VERSION ""

NS_ :

BS_:

BU_: CH DIPF DIPR ETH FC HVI HVS PARTY SDCV VEH VIRT

BO_ 1448 EPBR_alertLog: 8 VEH
 SG_ EPBR_a174_nonterminalReason m174 : 56|5@1+ (1,0) [0|21] ""  gtw
 SG_ EPBR_a190_nonterminalReason m190 : 56|5@1+ (1,0) [0|21] ""  gtw
 SG_ EPBR_a175_nonterminalReason m175 : 56|5@1+ (1,0) [0|21] ""  gtw
 SG_ EPBR_a042_UsageNVMMTask m42 : 56|8@1+ (1,0) [0|255] ""  gtw
 SG_ EPBR_a247_nonterminalReason m247 : 56|5@1+ (1,0) [0|21] ""  gtw
 SG_ EPBR_a191_nonterminalReason m191 : 56|5@1+ (1,0) [0|21] ""  gtw
 SG_ EPBR_a022_TaskInitError4 m22 : 56|8@1+ (1,0) [0|255] ""  gtw
 SG_ EPBR_a179_nonterminalReason m179 : 56|5@1+ (1,0) [0|21] ""  gtw
 SG_ EPBR_a176_nonterminalReason m176 : 56|5@1+ (1,0) [0|21] ""  gtw
 SG_ EPBR_a248_nonterminalReason m248 : 56|5@1+ (1,0) [0|21] ""  gtw
 SG_ EPBR_a177_nonterminalReason m177 : 56|5@1+ (1,0) [0|21] ""  gtw
 SG_ EPBR_a041_CPULoadNVMMTask m41 : 56|8@1+ (1,0) [0|255] ""  gtw
 SG_ EPBR_a138_monitorState m138 : 51|3@1+ (1,0) [0|5] ""  gtw
 SG_ EPBR_a177_esmOpTrigger m177 : 48|5@1+ (1,0) [0|30] ""  gtw
 SG_ EPBR_a248_esmOpTrigger m248 : 48|5@1+ (1,0) [0|30] ""  gtw
 SG_ EPBR_a041_CPULoad1000msTask m41 : 48|8@1+ (1,0) [0|255] ""  gtw
 SG_ EPBR_a022_TaskInitError3 m22 : 48|8@1+ (1,0) [0|255] ""  gtw
 SG_ EPBR_a190_esmOpTrigger m190 : 48|5@1+ (1,0) [0|30] ""  gtw
 SG_ EPBR_a042_UsageUDSTask m42 : 48|8@1+ (1,0) [0|255] ""  gtw
 SG_ EPBR_a174_esmOpTrigger m174 : 48|5@1+ (1,0) [0|30] ""  gtw
 SG_ EPBR_a003_Data m3 : 48|16@1+ (1,0) [0|65535] ""  gtw
 SG_ EPBR_a138_localState m138 : 48|3@1+ (1,0) [0|5] ""  gtw
 SG_ EPBR_a247_esmOpTrigger m247 : 48|5@1+ (1,0) [0|30] ""  gtw
 SG_ EPBR_a191_esmOpTrigger m191 : 48|5@1+ (1,0) [0|30] ""  gtw
 SG_ EPBR_a175_esmOpTrigger m175 : 48|5@1+ (1,0) [0|30] ""  gtw
 SG_ EPBR_a216_byte3 m216 : 48|8@1+ (1,0) [0|255] ""  gtw
 SG_ EPBR_a176_esmOpTrigger m176 : 48|5@1+ (1,0) [0|30] ""  gtw
 SG_ EPBR_a000_alertDataW2 m0 : 48|16@1+ (1,0) [0|65535] ""  X
 SG_ EPBR_a179_esmOpTrigger m179 : 48|5@1+ (1,0) [0|30] ""  gtw
 SG_ EPBR_a183_invalidateReason m183 : 45|2@1+ (1,0) [0|3] ""  gtw
 SG_ EPBR_a063_faulted m63 : 43|1@1+ (1,0) [0|1] ""  gtw
 SG_ EPBR_a063_stuckActive m63 : 42|1@1+ (1,0) [0|1] ""  gtw
 SG_ EPBR_a063_indeterminate m63 : 41|1@1+ (1,0) [0|1] ""  gtw
 SG_ EPBR_a171_12vFilt m171 : 40|12@1+ (0.005443676098,0) [0|22.29185] "V"  gtw
 SG_ EPBR_a135_12vFilt m135 : 40|12@1+ (0.005443676098,0) [0|22.29185] "V"  gtw
 SG_ EPBR_a022_TaskInitError2 m22 : 40|8@1+ (1,0) [0|255] ""  gtw
 SG_ EPBR_a247_csmFaultReason m247 : 40|5@1+ (1,0) [0|21] ""  gtw
 SG_ EPBR_a183_nextState m183 : 40|5@1+ (1,0) [0|19] ""  gtw
 SG_ EPBR_a191_csmFaultReason m191 : 40|5@1+ (1,0) [0|21] ""  gtw
 SG_ EPBR_a186_nextState m186 : 40|5@1+ (1,0) [0|19] ""  gtw
 SG_ EPBR_a126_12vFilt m126 : 40|12@1+ (0.005443676098,0) [0|22.29185] "V"  gtw
 SG_ EPBR_a041_CPULoad100msTask m41 : 40|8@1+ (1,0) [0|255] ""  gtw
 SG_ EPBR_a170_12vFilt m170 : 40|12@1+ (0.005443676098,0) [0|22.29185] "V"  gtw
 SG_ EPBR_a246_esmOpTrigger m246 : 40|5@1+ (1,0) [0|30] ""  gtw
 SG_ EPBR_a134_12vFilt m134 : 40|12@1+ (0.005443676098,0) [0|22.29185] "V"  gtw
 SG_ EPBR_a063_disconnected m63 : 40|1@1+ (1,0) [0|1] ""  gtw
 SG_ EPBR_a180_nextState m180 : 40|5@1+ (1,0) [0|19] ""  gtw
 SG_ EPBR_a174_csmFaultReason m174 : 40|5@1+ (1,0) [0|21] ""  gtw
 SG_ EPBR_a217_byte7 m217 : 40|8@1+ (1,0) [0|255] ""  gtw
 SG_ EPBR_a187_nextState m187 : 40|5@1+ (1,0) [0|19] ""  gtw
 SG_ EPBR_a127_12vFilt m127 : 40|12@1+ (0.005443676098,0) [0|22.29185] "V"  gtw
 SG_ EPBR_a190_csmFaultReason m190 : 40|5@1+ (1,0) [0|21] ""  gtw
 SG_ EPBR_a249_esmOpTrigger m249 : 40|5@1+ (1,0) [0|30] ""  gtw
 SG_ EPBR_a216_byte2 m216 : 40|8@1+ (1,0) [0|255] ""  gtw
 SG_ EPBR_a059_current m59 : 40|12@1+ (0.05,0) [0|204.75] "A"  gtw
 SG_ EPBR_a184_nextState m184 : 40|5@1+ (1,0) [0|19] ""  gtw
 SG_ EPBR_a043_CallTrace1 m43 : 40|24@1+ (1,0) [0|16777215] ""  gtw
 SG_ EPBR_a248_csmFaultReason m248 : 40|5@1+ (1,0) [0|21] ""  gtw
 SG_ EPBR_a044_CallTrace1 m44 : 40|24@1+ (1,0) [0|16777215] ""  gtw
 SG_ EPBR_a177_csmFaultReason m177 : 40|5@1+ (1,0) [0|21] ""  gtw
 SG_ EPBR_a137_12vFilt m137 : 40|12@1+ (0.005443676098,0) [0|22.29185] "V"  gtw
 SG_ EPBR_a125_12vFilt m125 : 40|12@1+ (0.005443676098,0) [0|22.29185] "V"  gtw
 SG_ EPBR_a179_csmFaultReason m179 : 40|5@1+ (1,0) [0|21] ""  gtw
 SG_ EPBR_a042_Usage1000msTask m42 : 40|8@1+ (1,0) [0|255] ""  gtw
 SG_ EPBR_a188_nextState m188 : 40|5@1+ (1,0) [0|19] ""  gtw
 SG_ EPBR_a128_12vFilt m128 : 40|12@1+ (0.005443676098,0) [0|22.29185] "V"  gtw
 SG_ EPBR_a136_12vFilt m136 : 40|12@1+ (0.005443676098,0) [0|22.29185] "V"  gtw
 SG_ EPBR_a176_csmFaultReason m176 : 40|5@1+ (1,0) [0|21] ""  gtw
 SG_ EPBR_a045_CallTrace1 m45 : 40|24@1+ (1,0) [0|16777215] ""  gtw
 SG_ EPBR_a189_nextState m189 : 40|5@1+ (1,0) [0|19] ""  gtw
 SG_ EPBR_a046_CallTrace1 m46 : 40|24@1+ (1,0) [0|16777215] ""  gtw
 SG_ EPBR_a175_csmFaultReason m175 : 40|5@1+ (1,0) [0|21] ""  gtw
 SG_ EPBR_a176_monitorFaultStatus m176 : 37|2@1+ (1,0) [0|3] ""  gtw
 SG_ EPBR_a249_faultStatus m249 : 37|2@1+ (1,0) [0|3] ""  gtw
 SG_ EPBR_a177_monitorFaultStatus m177 : 37|2@1+ (1,0) [0|3] ""  gtw
 SG_ EPBR_a174_monitorFaultStatus m174 : 37|2@1+ (1,0) [0|3] ""  gtw
 SG_ EPBR_a179_monitorFaultStatus m179 : 37|2@1+ (1,0) [0|3] ""  gtw
 SG_ EPBR_a190_monitorFaultStatus m190 : 37|2@1+ (1,0) [0|3] ""  gtw
 SG_ EPBR_a248_monitorFaultStatus m248 : 37|2@1+ (1,0) [0|3] ""  gtw
 SG_ EPBR_a175_monitorFaultStatus m175 : 37|2@1+ (1,0) [0|3] ""  gtw
 SG_ EPBR_a246_faultStatus m246 : 37|2@1+ (1,0) [0|3] ""  gtw
 SG_ EPBR_a191_monitorFaultStatus m191 : 37|2@1+ (1,0) [0|3] ""  gtw
 SG_ EPBR_a247_monitorFaultStatus m247 : 37|2@1+ (1,0) [0|3] ""  gtw
 SG_ EPBR_a188_previousState m188 : 32|5@1+ (1,0) [0|19] ""  gtw
 SG_ EPBR_a177_monitorUnitStatus m177 : 32|5@1+ (1,0) [0|21] ""  gtw
 SG_ EPBR_a041_CPULoad10msTask m41 : 32|8@1+ (1,0) [0|255] ""  gtw
 SG_ EPBR_a183_previousState m183 : 32|5@1+ (1,0) [0|19] ""  gtw
 SG_ EPBR_a003_LineNumber m3 : 32|16@1+ (1,0) [0|65535] ""  gtw
 SG_ EPBR_a176_monitorUnitStatus m176 : 32|5@1+ (1,0) [0|21] ""  gtw
 SG_ EPBR_a216_byte1 m216 : 32|8@1+ (1,0) [0|255] ""  gtw
 SG_ EPBR_a189_previousState m189 : 32|5@1+ (1,0) [0|19] ""  gtw
 SG_ EPBR_a184_previousState m184 : 32|5@1+ (1,0) [0|19] ""  gtw
 SG_ EPBR_a217_byte6 m217 : 32|8@1+ (1,0) [0|255] ""  gtw
 SG_ EPBR_a248_monitorUnitStatus m248 : 32|5@1+ (1,0) [0|21] ""  gtw
 SG_ EPBR_a000_alertDataW1 m0 : 32|16@1+ (1,0) [0|65535] ""  X
 SG_ EPBR_a175_monitorUnitStatus m175 : 32|5@1+ (1,0) [0|21] ""  gtw
 SG_ EPBR_a246_esmStateRequest m246 : 32|5@1+ (1,0) [0|19] ""  gtw
 SG_ EPBR_a249_esmStateRequest m249 : 32|5@1+ (1,0) [0|19] ""  gtw
 SG_ EPBR_a247_monitorUnitStatus m247 : 32|5@1+ (1,0) [0|21] ""  gtw
 SG_ EPBR_a191_monitorUnitStatus m191 : 32|5@1+ (1,0) [0|21] ""  gtw
 SG_ EPBR_a180_previousState m180 : 32|5@1+ (1,0) [0|19] ""  gtw
 SG_ EPBR_a173_csmState m173 : 32|4@1+ (1,0) [0|14] ""  gtw
 SG_ EPBR_a182_temperature m182 : 32|8@1- (0.5,-40) [-40|80] "deg C"  gtw
 SG_ EPBR_a174_monitorUnitStatus m174 : 32|5@1+ (1,0) [0|21] ""  gtw
 SG_ EPBR_a042_Usage100msTask m42 : 32|8@1+ (1,0) [0|255] ""  gtw
 SG_ EPBR_a179_monitorUnitStatus m179 : 32|5@1+ (1,0) [0|21] ""  gtw
 SG_ EPBR_a186_previousState m186 : 32|5@1+ (1,0) [0|19] ""  gtw
 SG_ EPBR_a063_ADCVoltage m63 : 32|8@1+ (0.025,0) [0|6.375] "V"  gtw
 SG_ EPBR_a022_TaskInitError1 m22 : 32|8@1+ (1,0) [0|255] ""  gtw
 SG_ EPBR_a190_monitorUnitStatus m190 : 32|5@1+ (1,0) [0|21] ""  gtw
 SG_ EPBR_a187_previousState m187 : 32|5@1+ (1,0) [0|19] ""  gtw
 SG_ EPBR_a177_faultStatus m177 : 29|2@1+ (1,0) [0|3] ""  gtw
 SG_ EPBR_a176_faultStatus m176 : 29|2@1+ (1,0) [0|3] ""  gtw
 SG_ EPBR_a248_faultStatus m248 : 29|2@1+ (1,0) [0|3] ""  gtw
 SG_ EPBR_a175_faultStatus m175 : 29|2@1+ (1,0) [0|3] ""  gtw
 SG_ EPBR_a191_faultStatus m191 : 29|2@1+ (1,0) [0|3] ""  gtw
 SG_ EPBR_a247_faultStatus m247 : 29|2@1+ (1,0) [0|3] ""  gtw
 SG_ EPBR_a174_faultStatus m174 : 29|2@1+ (1,0) [0|3] ""  gtw
 SG_ EPBR_a179_faultStatus m179 : 29|2@1+ (1,0) [0|3] ""  gtw
 SG_ EPBR_a190_faultStatus m190 : 29|2@1+ (1,0) [0|3] ""  gtw
 SG_ EPBR_a126_nvFilt m126 : 28|12@1+ (0.005443676098,0) [0|22.29185] "V"  gtw
 SG_ EPBR_a128_nvFilt m128 : 28|12@1+ (0.005443676098,0) [0|22.29185] "V"  gtw
 SG_ EPBR_a170_nvFilt m170 : 28|12@1+ (0.005443676098,0) [0|22.29185] "V"  gtw
 SG_ EPBR_a059_resistanceEstimate m59 : 28|12@1+ (0.00244,0) [0|9.9918] "Ohms"  gtw
 SG_ EPBR_a134_nvFilt m134 : 28|12@1+ (0.005443676098,0) [0|22.29185] "V"  gtw
 SG_ EPBR_a127_nvFilt m127 : 28|12@1+ (0.005443676098,0) [0|22.29185] "V"  gtw
 SG_ EPBR_a137_nvFilt m137 : 28|12@1+ (0.005443676098,0) [0|22.29185] "V"  gtw
 SG_ EPBR_a125_nvFilt m125 : 28|12@1+ (0.005443676098,0) [0|22.29185] "V"  gtw
 SG_ EPBR_a136_nvFilt m136 : 28|12@1+ (0.005443676098,0) [0|22.29185] "V"  gtw
 SG_ EPBR_a135_nvFilt m135 : 28|12@1+ (0.005443676098,0) [0|22.29185] "V"  gtw
 SG_ EPBR_a171_nvFilt m171 : 28|12@1+ (0.005443676098,0) [0|22.29185] "V"  gtw
 SG_ EPBR_a116_VEH_logging1Hz m116 : 27|1@1+ (1,0) [0|1] ""  gtw
 SG_ EPBR_a021_Task1000msMissed m21 : 27|1@1+ (1,0) [0|1] ""  gtw
 SG_ EPBR_a021_Task1000msStarved m21 : 26|1@1+ (1,0) [0|1] ""  gtw
 SG_ EPBR_a116_VEH_switchStatus m116 : 26|1@1+ (1,0) [0|1] ""  gtw
 SG_ EPBR_a241_highCurrent m241 : 26|2@1+ (1,0) [0|3] ""  gtw
 SG_ EPBR_a243_brakeDiscWipingActive m243 : 26|1@1+ (1,0) [0|1] ""  gtw
 SG_ EPBR_a242_highCurrent m242 : 26|2@1+ (1,0) [0|3] ""  gtw
 SG_ EPBR_a021_Task1000msLate m21 : 25|1@1+ (1,0) [0|1] ""  gtw
 SG_ EPBR_a243_vehiclePowerState m243 : 25|1@1+ (1,0) [0|1] ""  gtw
 SG_ EPBR_a116_VEH_restraintStatus m116 : 25|1@1+ (1,0) [0|1] ""  gtw
 SG_ EPBR_a117_VEH_intrusionSensorSta m117 : 25|1@1+ (1,0) [0|1] ""  gtw
 SG_ EPBR_a180_esmOpTrigger m180 : 24|5@1+ (1,0) [0|30] ""  gtw
 SG_ EPBR_a176_esmStateRequest m176 : 24|5@1+ (1,0) [0|19] ""  gtw
 SG_ EPBR_a187_esmOpTrigger m187 : 24|5@1+ (1,0) [0|30] ""  gtw
 SG_ EPBR_a179_esmStateRequest m179 : 24|5@1+ (1,0) [0|19] ""  gtw
 SG_ EPBR_a216_byte0 m216 : 24|8@1+ (1,0) [0|255] ""  gtw
 SG_ EPBR_a249_nextState m249 : 24|5@1+ (1,0) [0|19] ""  gtw
 SG_ EPBR_a041_CPULoad1msTask m41 : 24|8@1+ (1,0) [0|255] ""  gtw
 SG_ EPBR_a300_subUsageId m300 : 24|5@1+ (1,0) [0|19] ""  gtw
 SG_ EPBR_a242_vehiclePowerState m242 : 24|2@1+ (1,0) [0|3] ""  gtw
 SG_ EPBR_a177_esmStateRequest m177 : 24|5@1+ (1,0) [0|19] ""  gtw
 SG_ EPBR_a189_esmOpTrigger m189 : 24|5@1+ (1,0) [0|30] ""  gtw
 SG_ EPBR_a183_esmOpTrigger m183 : 24|5@1+ (1,0) [0|30] ""  gtw
 SG_ EPBR_a186_esmOpTrigger m186 : 24|5@1+ (1,0) [0|30] ""  gtw
 SG_ EPBR_a248_esmStateRequest m248 : 24|5@1+ (1,0) [0|19] ""  gtw
 SG_ EPBR_a141_toState m141 : 24|5@1+ (1,0) [0|19] ""  gtw
 SG_ EPBR_a117_VEH_switchStatus m117 : 24|1@1+ (1,0) [0|1] ""  gtw
 SG_ EPBR_a118_VEH_systemStatus m118 : 24|1@1+ (1,0) [0|1] ""  gtw
 SG_ EPBR_a190_esmStateRequest m190 : 24|5@1+ (1,0) [0|19] ""  gtw
 SG_ EPBR_a116_VEH_seatHeatStatus m116 : 24|1@1+ (1,0) [0|1] ""  gtw
 SG_ EPBR_a188_esmOpTrigger m188 : 24|5@1+ (1,0) [0|30] ""  gtw
 SG_ EPBR_a241_vehiclePowerState m241 : 24|2@1+ (1,0) [0|3] ""  gtw
 SG_ EPBR_a113_VEH_powertrainControl m113 : 24|1@1+ (1,0) [0|1] ""  gtw
 SG_ EPBR_a174_esmStateRequest m174 : 24|5@1+ (1,0) [0|19] ""  gtw
 SG_ EPBR_a022_TaskInitError0 m22 : 24|8@1+ (1,0) [0|255] ""  gtw
 SG_ EPBR_a063_switchType m63 : 24|8@1+ (1,0) [0|255] ""  gtw
 SG_ EPBR_a191_esmStateRequest m191 : 24|5@1+ (1,0) [0|19] ""  gtw
 SG_ EPBR_a021_Task100msMissed m21 : 24|1@1+ (1,0) [0|1] ""  gtw
 SG_ EPBR_a247_esmStateRequest m247 : 24|5@1+ (1,0) [0|19] ""  gtw
 SG_ EPBR_a184_esmOpTrigger m184 : 24|5@1+ (1,0) [0|30] ""  gtw
 SG_ EPBR_a042_Usage10msTask m42 : 24|8@1+ (1,0) [0|255] ""  gtw
 SG_ EPBR_a175_esmStateRequest m175 : 24|5@1+ (1,0) [0|19] ""  gtw
 SG_ EPBR_a182_grade m182 : 24|7@1- (1,0) [-64|63] "%"  gtw
 SG_ EPBR_a217_byte5 m217 : 24|8@1+ (1,0) [0|255] ""  gtw
 SG_ EPBR_a243_wiperSpeed m243 : 24|1@1+ (1,0) [0|1] ""  gtw
 SG_ EPBR_a173_esmStateRequest m173 : 24|5@1+ (1,0) [0|19] ""  gtw
 SG_ EPBR_a246_nextState m246 : 24|5@1+ (1,0) [0|19] ""  gtw
 SG_ EPBR_a120_VEH_speed m120 : 24|1@1+ (1,0) [0|1] ""  gtw
 SG_ EPBR_a120_PARTY_speed m120 : 23|1@1+ (1,0) [0|1] ""  gtw
 SG_ EPBR_a117_VEH_doorStatus m117 : 23|1@1+ (1,0) [0|1] ""  gtw
 SG_ EPBR_a113_VEH_chassisControl m113 : 23|1@1+ (1,0) [0|1] ""  gtw
 SG_ EPBR_a021_Task100msStarved m21 : 23|1@1+ (1,0) [0|1] ""  gtw
 SG_ EPBR_a243_thermistorTMin m243 : 23|1@1+ (1,0) [0|1] ""  gtw
 SG_ EPBR_a118_VEH_12VBattStatus m118 : 23|1@1+ (1,0) [0|1] ""  gtw
 SG_ EPBR_a116_VEH_doorStatus m116 : 23|1@1+ (1,0) [0|1] ""  gtw
 SG_ EPBR_a117_VEH_seatStatus m117 : 22|1@1+ (1,0) [0|1] ""  gtw
 SG_ EPBR_a118_VEH_vehicleStatus m118 : 22|1@1+ (1,0) [0|1] ""  gtw
 SG_ EPBR_a021_Task100msLate m21 : 22|1@1+ (1,0) [0|1] ""  gtw
 SG_ EPBR_a113_VEH_ventCntlReq m113 : 22|1@1+ (1,0) [0|1] ""  gtw
 SG_ EPBR_a116_VEH_thsStatus m116 : 22|1@1+ (1,0) [0|1] ""  gtw
 SG_ EPBR_a243_tempAmbient m243 : 22|1@1+ (1,0) [0|1] ""  gtw
 SG_ EPBR_a120_VEH_status m120 : 22|1@1+ (1,0) [0|1] ""  gtw
 SG_ EPBR_a015_NVMMWriteFailed m15 : 21|1@1+ (1,0) [0|1] ""  gtw
 SG_ EPBR_a021_Task10msMissed m21 : 21|1@1+ (1,0) [0|1] ""  gtw
 SG_ EPBR_a113_VEH_solarData m113 : 21|1@1+ (1,0) [0|1] ""  gtw
 SG_ EPBR_a117_VEH_lightStatus m117 : 21|1@1+ (1,0) [0|1] ""  gtw
 SG_ EPBR_a120_PARTY_locStatus m120 : 21|1@1+ (1,0) [0|1] ""  gtw
 SG_ EPBR_a012_ExternalReset m12 : 21|1@1+ (1,0) [0|1] ""  gtw
 SG_ EPBR_a116_VEH_seatStatus m116 : 21|1@1+ (1,0) [0|1] ""  gtw
 SG_ EPBR_a243_vehicleSpeed m243 : 21|1@1+ (1,0) [0|1] ""  gtw
 SG_ EPBR_a118_VEH_LVPowerState m118 : 21|1@1+ (1,0) [0|1] ""  gtw
 SG_ EPBR_a242_hvState m242 : 20|3@1+ (1,0) [0|6] ""  gtw
 SG_ EPBR_a243_DIStorqueActual m243 : 20|1@1+ (1,0) [0|1] ""  gtw
 SG_ EPBR_a021_Task10msStarved m21 : 20|1@1+ (1,0) [0|1] ""  gtw
 SG_ EPBR_a117_VEH_restraintStatus m117 : 20|1@1+ (1,0) [0|1] ""  gtw
 SG_ EPBR_a118_VEH_okToUseHighPwr m118 : 20|1@1+ (1,0) [0|1] ""  gtw
 SG_ EPBR_a116_VEH_lightStatus m116 : 20|1@1+ (1,0) [0|1] ""  gtw
 SG_ EPBR_a015_NVMMMemOverflow m15 : 20|1@1+ (1,0) [0|1] ""  gtw
 SG_ EPBR_a113_VEH_vehicleControl2 m113 : 20|1@1+ (1,0) [0|1] ""  gtw
 SG_ EPBR_a120_VEH_torque m120 : 20|1@1+ (1,0) [0|1] ""  gtw
 SG_ EPBR_a012_DebugReset m12 : 20|1@1+ (1,0) [0|1] ""  gtw
 SG_ EPBR_a107_VEH_bmbMinMax m107 : 20|1@1+ (1,0) [0|1] ""  gtw
 SG_ EPBR_a107_VEH_thermalStatus m107 : 19|1@1+ (1,0) [0|1] ""  gtw
 SG_ EPBR_a015_NVMMRecordUpgraded m15 : 19|1@1+ (1,0) [0|1] ""  gtw
 SG_ EPBR_a021_Task10msLate m21 : 19|1@1+ (1,0) [0|1] ""  gtw
 SG_ EPBR_a178_monitorCaliperState m178 : 19|3@1+ (1,0) [0|5] ""  gtw
 SG_ EPBR_a241_epbSysStatus m241 : 19|4@1+ (1,0) [0|8] ""  gtw
 SG_ EPBR_a120_PARTY_torque m120 : 19|1@1+ (1,0) [0|1] ""  gtw
 SG_ EPBR_a012_CheckstopReset m12 : 19|1@1+ (1,0) [0|1] ""  gtw
 SG_ EPBR_a114_PARTY_party3 m114 : 19|1@1+ (1,0) [0|1] ""  gtw
 SG_ EPBR_a116_VEH_LVPowerState m116 : 19|1@1+ (1,0) [0|1] ""  gtw
 SG_ EPBR_a109_PARTY_collision m109 : 19|1@1+ (1,0) [0|1] ""  gtw
 SG_ EPBR_a242_contCurrentState m242 : 19|1@1+ (1,0) [0|1] ""  gtw
 SG_ EPBR_a117_VEH_LVPowerState m117 : 19|1@1+ (1,0) [0|1] ""  gtw
 SG_ EPBR_a243_DItorqueActual m243 : 19|1@1+ (1,0) [0|1] ""  gtw
 SG_ EPBR_a216_monitor_MIA m216 : 19|1@1+ (1,0) [0|1] ""  gtw
 SG_ EPBR_a104_PARTY_control m104 : 19|1@1+ (1,0) [0|1] ""  gtw
 SG_ EPBR_a113_VEH_vehicleControl m113 : 19|1@1+ (1,0) [0|1] ""  gtw
 SG_ EPBR_a108_PARTY_torque m108 : 19|1@1+ (1,0) [0|1] ""  gtw
 SG_ EPBR_a118_VEH_status m118 : 19|1@1+ (1,0) [0|1] ""  gtw
 SG_ EPBR_a242_contDesiredState m242 : 18|1@1+ (1,0) [0|1] ""  gtw
 SG_ EPBR_a109_PARTY_nearDeploy m109 : 18|1@1+ (1,0) [0|1] ""  gtw
 SG_ EPBR_a116_VEH_hvacRequest m116 : 18|1@1+ (1,0) [0|1] ""  gtw
 SG_ EPBR_a114_VEH_wheelSpeeds m114 : 18|1@1+ (1,0) [0|1] ""  gtw
 SG_ EPBR_a106_VEH_thermalStatus m106 : 18|1@1+ (1,0) [0|1] ""  gtw
 SG_ EPBR_a187_monitorCDPStatus m187 : 18|2@1+ (1,0) [0|2] ""  gtw
 SG_ EPBR_a110_VEH_time m110 : 18|1@1+ (1,0) [0|1] ""  gtw
 SG_ EPBR_a243_drivetrainType m243 : 18|1@1+ (1,0) [0|1] ""  gtw
 SG_ EPBR_a118_VEH_sensors m118 : 18|1@1+ (1,0) [0|1] ""  gtw
 SG_ EPBR_a241_diKeepAlive m241 : 18|1@1+ (1,0) [0|1] ""  gtw
 SG_ EPBR_a188_monitorCDPStatus m188 : 18|2@1+ (1,0) [0|2] ""  gtw
 SG_ EPBR_a117_VEH_hvacBlowerFdb m117 : 18|1@1+ (1,0) [0|1] ""  gtw
 SG_ EPBR_a102_VEH_sensorStatus m102 : 18|1@1+ (1,0) [0|1] ""  gtw
 SG_ EPBR_a183_monitorCDPStatus m183 : 18|2@1+ (1,0) [0|2] ""  gtw
 SG_ EPBR_a108_VEH_torque m108 : 18|1@1+ (1,0) [0|1] ""  gtw
 SG_ EPBR_a103_VEH_status m103 : 18|1@1+ (1,0) [0|1] ""  gtw
 SG_ EPBR_a015_NVMMVersionMismatch m15 : 18|1@1+ (1,0) [0|1] ""  gtw
 SG_ EPBR_a184_monitorCDPStatus m184 : 18|2@1+ (1,0) [0|2] ""  gtw
 SG_ EPBR_a189_monitorCDPStatus m189 : 18|2@1+ (1,0) [0|2] ""  gtw
 SG_ EPBR_a021_Task1msMissed m21 : 18|1@1+ (1,0) [0|1] ""  gtw
 SG_ EPBR_a113_VEH_chargeRequest m113 : 18|1@1+ (1,0) [0|1] ""  gtw
 SG_ EPBR_a119_VEH_rightStalk m119 : 18|1@1+ (1,0) [0|1] ""  gtw
 SG_ EPBR_a012_SoftwareReset m12 : 18|1@1+ (1,0) [0|1] ""  gtw
 SG_ EPBR_a180_monitorCDPStatus m180 : 18|2@1+ (1,0) [0|2] ""  gtw
 SG_ EPBR_a107_VEH_status m107 : 18|1@1+ (1,0) [0|1] ""  gtw
 SG_ EPBR_a104_VEH_thermalStatus m104 : 18|1@1+ (1,0) [0|1] ""  gtw
 SG_ EPBR_a120_PARTY_systemStatus m120 : 18|1@1+ (1,0) [0|1] ""  gtw
 SG_ EPBR_a216_CRC_error m216 : 18|1@1+ (1,0) [0|1] ""  gtw
 SG_ EPBR_a186_monitorCDPStatus m186 : 18|2@1+ (1,0) [0|2] ""  gtw
 SG_ EPBR_a216_spiFault m216 : 17|1@1+ (1,0) [0|1] ""  gtw
 SG_ EPBR_a114_PARTY_wheelSpeeds m114 : 17|1@1+ (1,0) [0|1] ""  gtw
 SG_ EPBR_a113_VEH_hvacRequest m113 : 17|1@1+ (1,0) [0|1] ""  gtw
 SG_ EPBR_a118_VEH_lighting m118 : 17|1@1+ (1,0) [0|1] ""  gtw
 SG_ EPBR_a107_VEH_vehNm m107 : 17|1@1+ (1,0) [0|1] ""  gtw
 SG_ EPBR_a112_VEH_status m112 : 17|1@1+ (1,0) [0|1] ""  gtw
 SG_ EPBR_a242_hvcCurrentState m242 : 17|1@1+ (1,0) [0|1] ""  gtw
 SG_ EPBR_a106_VEH_thermalControl m106 : 17|1@1+ (1,0) [0|1] ""  gtw
 SG_ EPBR_a119_VEH_leftStalk m119 : 17|1@1+ (1,0) [0|1] ""  gtw
 SG_ EPBR_a100_PARTY m100 : 17|1@1+ (1,0) [0|1] ""  gtw
 SG_ EPBR_a201_epbHWBrakeType m201 : 17|2@1+ (1,0) [0|2] ""  gtw
 SG_ EPBR_a241_currentState m241 : 17|1@1+ (1,0) [0|1] ""  gtw
 SG_ EPBR_a115_VEH_authentication m115 : 17|1@1+ (1,0) [0|1] ""  gtw
 SG_ EPBR_a002_PowerOnReset m2 : 17|1@1+ (1,0) [0|1] ""  gtw
 SG_ EPBR_a013_ClearQueueFull m13 : 17|1@1+ (1,0) [0|1] ""  gtw
 SG_ EPBR_a103_VEH_vehNm m103 : 17|1@1+ (1,0) [0|1] ""  gtw
 SG_ EPBR_a117_VEH_vehNm m117 : 17|1@1+ (1,0) [0|1] ""  gtw
 SG_ EPBR_a012_FlashError m12 : 17|1@1+ (1,0) [0|1] ""  gtw
 SG_ EPBR_a105_VEH_chNm m105 : 17|1@1+ (1,0) [0|1] ""  gtw
 SG_ EPBR_a097_VEH_state m97 : 17|1@1+ (1,0) [0|1] ""  gtw
 SG_ EPBR_a104_VEH_bodyControls m104 : 17|1@1+ (1,0) [0|1] ""  gtw
 SG_ EPBR_a021_Task1msStarved m21 : 17|1@1+ (1,0) [0|1] ""  gtw
 SG_ EPBR_a116_VEH_vehNm m116 : 17|1@1+ (1,0) [0|1] ""  gtw
 SG_ EPBR_a015_NVMMCRCMismatch m15 : 17|1@1+ (1,0) [0|1] ""  gtw
 SG_ EPBR_a102_VEH_feedbackStatus m102 : 17|1@1+ (1,0) [0|1] ""  gtw
 SG_ EPBR_a060_resetUnlocked m60 : 17|1@1+ (1,0) [0|1] ""  gtw
 SG_ EPBR_a098_VEH_temperature m98 : 17|1@1+ (1,0) [0|1] ""  gtw
 SG_ EPBR_a111_VEH_status m111 : 17|1@1+ (1,0) [0|1] ""  gtw
 SG_ EPBR_a108_VEH_thermalControl m108 : 17|1@1+ (1,0) [0|1] ""  gtw
 SG_ EPBR_a120_VEH_systemStatus m120 : 17|1@1+ (1,0) [0|1] ""  gtw
 SG_ EPBR_a110_VEH_carConfig m110 : 17|1@1+ (1,0) [0|1] ""  gtw
 SG_ EPBR_a109_PARTY_inertial2 m109 : 17|1@1+ (1,0) [0|1] ""  gtw
 SG_ EPBR_a243_brakeMasterCylPressQF m243 : 17|1@1+ (1,0) [0|1] ""  gtw
 SG_ EPBR_a010_UnderVoltageTimeout m10 : 17|1@1+ (1,0) [0|1] ""  gtw
 SG_ EPBR_a185_summonFaultReason m185 : 16|5@1+ (1,0) [0|28] ""  gtw
 SG_ EPBR_a109_PARTY_status m109 : 16|1@1+ (1,0) [0|1] ""  gtw
 SG_ EPBR_a121_caliperState m121 : 16|4@1+ (1,0) [0|14] ""  gtw
 SG_ EPBR_a177_esmState m177 : 16|5@1+ (1,0) [0|19] ""  gtw
 SG_ EPBR_a136_pvFilt m136 : 16|12@1+ (0.005443676098,0) [0|22.29185] "V"  gtw
 SG_ EPBR_a141_fromState m141 : 16|5@1+ (1,0) [0|19] ""  gtw
 SG_ EPBR_a181_grade m181 : 16|7@1+ (1,0) [0|127] "%"  gtw
 SG_ EPBR_a217_byte4 m217 : 16|8@1+ (1,0) [0|255] ""  gtw
 SG_ EPBR_a015_NVMMRecordNotFound m15 : 16|1@1+ (1,0) [0|1] ""  gtw
 SG_ EPBR_a030_logId m30 : 16|4@1+ (1,0) [0|15] ""  gtw
 SG_ EPBR_a045_CallTrace0 m45 : 16|24@1+ (1,0) [0|16777215] ""  gtw
 SG_ EPBR_a248_esmState m248 : 16|5@1+ (1,0) [0|19] ""  gtw
 SG_ EPBR_a128_pvFilt m128 : 16|12@1+ (0.005443676098,0) [0|22.29185] "V"  gtw
 SG_ EPBR_a100_VEH m100 : 16|1@1+ (1,0) [0|1] ""  gtw
 SG_ EPBR_a186_espCDPStatus m186 : 16|2@1+ (1,0) [0|2] ""  gtw
 SG_ EPBR_a041_CPULoadTotal m41 : 16|8@1+ (1,0) [0|255] ""  gtw
 SG_ EPBR_a059_voltageDrop m59 : 16|12@1+ (0.005443676098,0) [0|22.29185] "V"  gtw
 SG_ EPBR_a201_gtwHWBrakeType m201 : 16|1@1+ (1,0) [0|1] ""  gtw
 SG_ EPBR_a125_pvFilt m125 : 16|12@1+ (0.005443676098,0) [0|22.29185] "V"  gtw
 SG_ EPBR_a122_filteredCurrentCal m122 : 16|12@1+ (0.01,0) [0|40.95] "A"  gtw
 SG_ EPBR_a124_calOutOfBoundsData m124 : 16|1@1+ (1,0) [0|1] ""  gtw
 SG_ EPBR_a243_brakeMasterCylPress m243 : 16|1@1+ (1,0) [0|1] ""  gtw
 SG_ EPBR_a106_VEH_dcdcStatus m106 : 16|1@1+ (1,0) [0|1] ""  gtw
 SG_ EPBR_a105_VEH_states m105 : 16|1@1+ (1,0) [0|1] ""  gtw
 SG_ EPBR_a190_esmState m190 : 16|5@1+ (1,0) [0|19] ""  gtw
 SG_ EPBR_a188_espCDPStatus m188 : 16|2@1+ (1,0) [0|2] ""  gtw
 SG_ EPBR_a107_VEH_hvsNm m107 : 16|1@1+ (1,0) [0|1] ""  gtw
 SG_ EPBR_a003_AssertID m3 : 16|16@1+ (1,0) [0|65535] ""  gtw
 SG_ EPBR_a126_pvFilt m126 : 16|12@1+ (0.005443676098,0) [0|22.29185] "V"  gtw
 SG_ EPBR_a000_alertDataW0 m0 : 16|16@1+ (1,0) [0|65535] ""  X
 SG_ EPBR_a182_epbSysStatus m182 : 16|4@1+ (1,0) [0|8] ""  gtw
 SG_ EPBR_a002_CPUUndervoltage m2 : 16|1@1+ (1,0) [0|1] ""  gtw
 SG_ EPBR_a171_pvFilt m171 : 16|12@1+ (0.005443676098,0) [0|22.29185] "V"  gtw
 SG_ EPBR_a174_esmState m174 : 16|5@1+ (1,0) [0|19] ""  gtw
 SG_ EPBR_a246_previousState m246 : 16|5@1+ (1,0) [0|19] ""  gtw
 SG_ EPBR_a300_harnessId m300 : 16|5@1+ (1,0) [0|19] ""  gtw
 SG_ EPBR_a135_pvFilt m135 : 16|12@1+ (0.005443676098,0) [0|22.29185] "V"  gtw
 SG_ EPBR_a044_CallTrace0 m44 : 16|24@1+ (1,0) [0|16777215] ""  gtw
 SG_ EPBR_a060_lockoutDisabled m60 : 16|1@1+ (1,0) [0|1] ""  gtw
 SG_ EPBR_a187_espCDPStatus m187 : 16|2@1+ (1,0) [0|2] ""  gtw
 SG_ EPBR_a099_VEH_oocStatus m99 : 16|1@1+ (1,0) [0|1] ""  gtw
 SG_ EPBR_a001_InternalWatchdog m1 : 16|1@1+ (1,0) [0|1] ""  gtw
 SG_ EPBR_a064_busBitField m64 : 16|8@1+ (1,0) [0|255] ""  gtw
 SG_ EPBR_a117_PARTY_epbmStatus m117 : 16|1@1+ (1,0) [0|1] ""  gtw
 SG_ EPBR_a184_espCDPStatus m184 : 16|2@1+ (1,0) [0|2] ""  gtw
 SG_ EPBR_a097_VEH_HVStatus m97 : 16|1@1+ (1,0) [0|1] ""  gtw
 SG_ EPBR_a021_Task1msLate m21 : 16|1@1+ (1,0) [0|1] ""  gtw
 SG_ EPBR_a113_VEH_ethNm m113 : 16|1@1+ (1,0) [0|1] ""  gtw
 SG_ EPBR_a189_espCDPStatus m189 : 16|2@1+ (1,0) [0|2] ""  gtw
 SG_ EPBR_a247_esmState m247 : 16|5@1+ (1,0) [0|19] ""  gtw
 SG_ EPBR_a191_esmState m191 : 16|5@1+ (1,0) [0|19] ""  gtw
 SG_ EPBR_a112_VEH_internalStatus m112 : 16|1@1+ (1,0) [0|1] ""  gtw
 SG_ EPBR_a010_UnderVoltageDetected m10 : 16|1@1+ (1,0) [0|1] ""  gtw
 SG_ EPBR_a127_pvFilt m127 : 16|12@1+ (0.005443676098,0) [0|22.29185] "V"  gtw
 SG_ EPBR_a251_currentVariance m251 : 16|12@1+ (0.01,0) [0|40.95] "A"  gtw
 SG_ EPBR_a170_pvFilt m170 : 16|12@1+ (0.005443676098,0) [0|22.29185] "V"  gtw
 SG_ EPBR_a175_esmState m175 : 16|5@1+ (1,0) [0|19] ""  gtw
 SG_ EPBR_a183_espCDPStatus m183 : 16|2@1+ (1,0) [0|2] ""  gtw
 SG_ EPBR_a120_PARTY_chassisCntl m120 : 16|1@1+ (1,0) [0|1] ""  gtw
 SG_ EPBR_a134_pvFilt m134 : 16|12@1+ (0.005443676098,0) [0|22.29185] "V"  gtw
 SG_ EPBR_a137_pvFilt m137 : 16|12@1+ (0.005443676098,0) [0|22.29185] "V"  gtw
 SG_ EPBR_a180_espCDPStatus m180 : 16|2@1+ (1,0) [0|2] ""  gtw
 SG_ EPBR_a118_VEH_vehNm m118 : 16|1@1+ (1,0) [0|1] ""  gtw
 SG_ EPBR_a216_noData m216 : 16|1@1+ (1,0) [0|1] ""  gtw
 SG_ EPBR_a022_TaskInitErrorCount m22 : 16|8@1+ (1,0) [0|255] ""  gtw
 SG_ EPBR_a043_CallTrace0 m43 : 16|24@1+ (1,0) [0|16777215] ""  gtw
 SG_ EPBR_a178_localCaliperState m178 : 16|3@1+ (1,0) [0|5] ""  gtw
 SG_ EPBR_a013_LogQueueFull m13 : 16|1@1+ (1,0) [0|1] ""  gtw
 SG_ EPBR_a063_switchChannel m63 : 16|8@1+ (1,0) [0|255] ""  gtw
 SG_ EPBR_a176_esmState m176 : 16|5@1+ (1,0) [0|19] ""  gtw
 SG_ EPBR_a173_esmState m173 : 16|5@1+ (1,0) [0|19] ""  gtw
 SG_ EPBR_a098_VEH_thermalControl m98 : 16|1@1+ (1,0) [0|1] ""  gtw
 SG_ EPBR_a104_VEH_chNm m104 : 16|1@1+ (1,0) [0|1] ""  gtw
 SG_ EPBR_a249_previousState m249 : 16|5@1+ (1,0) [0|19] ""  gtw
 SG_ EPBR_a114_PARTY_status m114 : 16|1@1+ (1,0) [0|1] ""  gtw
 SG_ EPBR_a042_Usage1msTask m42 : 16|8@1+ (1,0) [0|255] ""  gtw
 SG_ EPBR_a119_VEH_steerAngle m119 : 16|1@1+ (1,0) [0|1] ""  gtw
 SG_ EPBR_a116_PARTY_epbmStatus m116 : 16|1@1+ (1,0) [0|1] ""  gtw
 SG_ EPBR_a108_VEH_temperature m108 : 16|1@1+ (1,0) [0|1] ""  gtw
 SG_ EPBR_a046_CallTrace0 m46 : 16|24@1+ (1,0) [0|16777215] ""  gtw
 SG_ EPBR_a115_VEH_vehNm m115 : 16|1@1+ (1,0) [0|1] ""  gtw
 SG_ EPBR_a111_VEH_internalStatus m111 : 16|1@1+ (1,0) [0|1] ""  gtw
 SG_ EPBR_a123_filteredCurrentCal m123 : 16|12@1+ (0.01,0) [0|40.95] "A"  gtw
 SG_ EPBR_a242_hvcDesiredState m242 : 16|1@1+ (1,0) [0|1] ""  gtw
 SG_ EPBR_a102_VEH_faults m102 : 16|1@1+ (1,0) [0|1] ""  gtw
 SG_ EPBR_a179_esmState m179 : 16|5@1+ (1,0) [0|19] ""  gtw
 SG_ EPBR_a110_VEH_carState m110 : 16|1@1+ (1,0) [0|1] ""  gtw
 SG_ EPBR_a101_VEH_state m101 : 16|1@1+ (1,0) [0|1] ""  gtw
 SG_ EPBR_a012_ClockError m12 : 16|1@1+ (1,0) [0|1] ""  gtw
 SG_ EPBR_a241_desiredState m241 : 16|1@1+ (1,0) [0|1] ""  gtw
 SG_ EPBR_a138_stateTime m138 : 16|32@1+ (1,0) [0|4294967295] ""  gtw
 SG_ EPBR_a103_VEH_hvsNm m103 : 16|1@1+ (1,0) [0|1] ""  gtw
 SG_ EPBR_alertType : 15|1@1+ (1,0) [0|1] ""  gtw
 SG_ EPBR_alertID M : 0|9@1+ (1,0) [0|300] ""  gtw

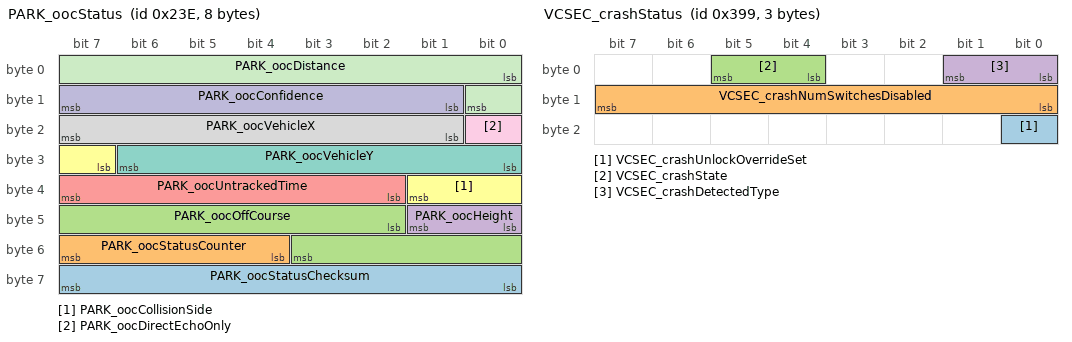
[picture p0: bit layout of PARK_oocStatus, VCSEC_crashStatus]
BO_ 574 PARK_oocStatus: 8 VEH
 SG_ PARK_oocStatusChecksum : 56|8@1+ (1,0) [0|255] ""  X
 SG_ PARK_oocStatusCounter : 52|4@1+ (1,0) [0|15] ""  X
 SG_ PARK_oocOffCourse : 42|10@1+ (1,-512) [-512|511] "cm"  X
 SG_ PARK_oocHeight : 40|2@1+ (1,0) [0|3] ""  X
 SG_ PARK_oocUntrackedTime : 34|6@1+ (0.1,0) [0|6.3] "s"  X
 SG_ PARK_oocCollisionSide : 31|3@1+ (1,0) [0|7] ""  X
 SG_ PARK_oocVehicleY : 24|7@1+ (2,-128) [-128|126] "cm"  X
 SG_ PARK_oocVehicleX : 17|7@1+ (4,-114) [-114|394] "cm"  X
 SG_ PARK_oocDirectEchoOnly : 16|1@1+ (1,0) [0|1] ""  X
 SG_ PARK_oocConfidence : 9|7@1+ (1,0) [0|127] ""  epbl
 SG_ PARK_oocDistance : 0|9@1+ (1,0) [0|511] ""  epbl

BO_ 921 VCSEC_crashStatus: 3 VEH
 SG_ VCSEC_crashUnlockOverrideSet : 16|1@1+ (1,0) [0|1] ""  gtw
 SG_ VCSEC_crashNumSwitchesDisabled : 8|8@1+ (1,0) [0|255] ""  gtw
 SG_ VCSEC_crashState : 4|2@1+ (1,0) [0|2] ""  gtw
 SG_ VCSEC_crashDetectedType : 0|2@1+ (1,0) [0|2] ""  gtw

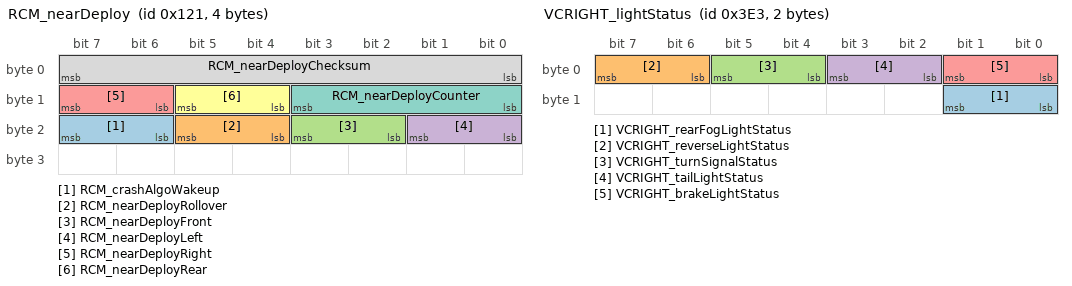
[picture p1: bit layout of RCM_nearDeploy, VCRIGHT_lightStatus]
BO_ 289 RCM_nearDeploy: 4 VEH
 SG_ RCM_crashAlgoWakeup : 22|2@1+ (1,0) [0|3] ""  vcfront
 SG_ RCM_nearDeployRollover : 20|2@1+ (1,0) [0|3] ""  vcfront
 SG_ RCM_nearDeployFront : 18|2@1+ (1,0) [0|3] ""  das
 SG_ RCM_nearDeployLeft : 16|2@1+ (1,0) [0|3] ""  vcfront
 SG_ RCM_nearDeployRight : 14|2@1+ (1,0) [0|3] ""  vcfront
 SG_ RCM_nearDeployRear : 12|2@1+ (1,0) [0|3] ""  vcfront
 SG_ RCM_nearDeployCounter : 8|4@1+ (1,0) [0|15] ""  vcfront
 SG_ RCM_nearDeployChecksum : 0|8@1+ (1,0) [0|255] ""  vcfront

BO_ 987 VCSEC_endpointTemp: 8 VEH
 SG_ VCSEC_rightCenterRSSI m1 : 56|8@1- (1,0) [-127|0] ""  X
 SG_ VCSEC_leftRearRSSI m1 : 48|8@1- (1,0) [-127|0] ""  X
 SG_ VCSEC_leftRightRSSI m1 : 40|8@1- (1,0) [-127|0] ""  X
 SG_ VCSEC_rearRightRSSI m2 : 40|8@1- (1,0) [-127|0] ""  X
 SG_ VCSEC_rearEndpointTemp m0 : 32|8@1- (1,0) [-128|127] "degC"  gtw
 SG_ VCSEC_rearLeftRSSI m2 : 32|8@1- (1,0) [-127|0] ""  X
 SG_ VCSEC_leftCenterRSSI m1 : 32|8@1- (1,0) [-127|0] ""  X
 SG_ VCSEC_rightEndpointTemp m0 : 24|8@1- (1,0) [-128|127] "degC"  gtw
 SG_ VCSEC_rearCenterRSSI m2 : 24|8@1- (1,0) [-127|0] ""  X
 SG_ VCSEC_centerRearRSSI m1 : 24|8@1- (1,0) [-127|0] ""  X
 SG_ VCSEC_leftEndpointTemp m0 : 16|8@1- (1,0) [-128|127] "degC"  gtw
 SG_ VCSEC_centerRightRSSI m1 : 16|8@1- (1,0) [-127|0] ""  X
 SG_ VCSEC_rightRearRSSI m2 : 16|8@1- (1,0) [-127|0] ""  X
 SG_ VCSEC_centerEndpointTemp m0 : 8|8@1- (1,0) [-128|127] "degC"  gtw
 SG_ VCSEC_rightLeftRSSI m2 : 8|8@1- (1,0) [-127|0] ""  X
 SG_ VCSEC_centerLeftRSSI m1 : 8|8@1- (1,0) [-127|0] ""  X
 SG_ VCSEC_endpointDataIndex M : 0|2@1+ (1,0) [0|2] ""  X

BO_ 995 VCRIGHT_lightStatus: 2 VEH
 SG_ VCRIGHT_rearFogLightStatus : 8|2@1+ (1,0) [0|3] ""  gtw
 SG_ VCRIGHT_reverseLightStatus : 6|2@1+ (1,0) [0|3] ""  gtw
 SG_ VCRIGHT_turnSignalStatus : 4|2@1+ (1,0) [0|3] ""  das
 SG_ VCRIGHT_tailLightStatus : 2|2@1+ (1,0) [0|3] ""  gtw
 SG_ VCRIGHT_brakeLightStatus : 0|2@1+ (1,0) [0|3] ""  gtw

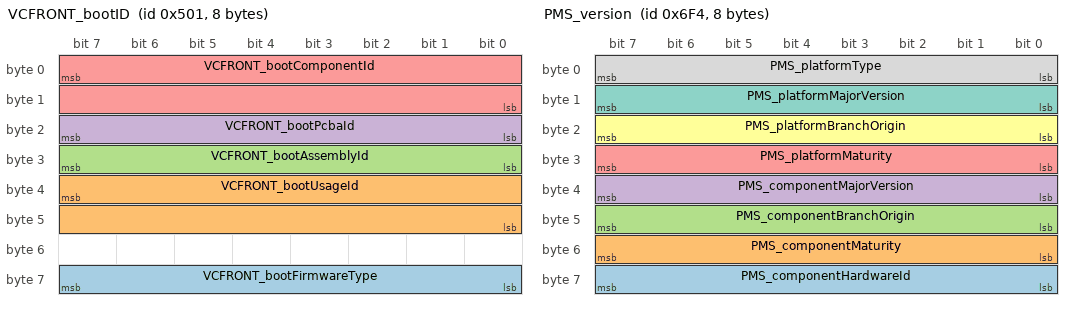
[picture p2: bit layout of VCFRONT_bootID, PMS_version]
BO_ 1281 VCFRONT_bootID: 8 VEH
 SG_ VCFRONT_bootFirmwareType : 63|8@0+ (1,0) [0|255] ""  X
 SG_ VCFRONT_bootUsageId : 39|16@0+ (1,0) [0|65535] ""  X
 SG_ VCFRONT_bootAssemblyId : 31|8@0+ (1,0) [0|255] ""  X
 SG_ VCFRONT_bootPcbaId : 23|8@0+ (1,0) [0|255] ""  gtw
 SG_ VCFRONT_bootComponentId : 7|16@0+ (1,0) [0|65535] ""  X

BO_ 1834 BMS_serialNumber: 8 VEH
 SG_ BMS_packSerialNumberByte07 m0 : 56|8@1+ (1,0) [0|255] ""  gtw
 SG_ BMS_packSerialNumberByte14 m1 : 56|8@1+ (1,0) [0|255] ""  gtw
 SG_ BMS_packSerialNumberByte13 m1 : 48|8@1+ (1,0) [0|255] ""  gtw
 SG_ BMS_packSerialNumberByte06 m0 : 48|8@1+ (1,0) [0|255] ""  gtw
 SG_ BMS_packSerialNumberByte05 m0 : 40|8@1+ (1,0) [0|255] ""  gtw
 SG_ BMS_packSerialNumberByte12 m1 : 40|8@1+ (1,0) [0|255] ""  gtw
 SG_ BMS_packSerialNumberByte11 m1 : 32|8@1+ (1,0) [0|255] ""  gtw
 SG_ BMS_packSerialNumberByte04 m0 : 32|8@1+ (1,0) [0|255] ""  gtw
 SG_ BMS_packSerialNumberByte03 m0 : 24|8@1+ (1,0) [0|255] ""  gtw
 SG_ BMS_packSerialNumberByte10 m1 : 24|8@1+ (1,0) [0|255] ""  gtw
 SG_ BMS_packSerialNumberByte02 m0 : 16|8@1+ (1,0) [0|255] ""  gtw
 SG_ BMS_packSerialNumberByte09 m1 : 16|8@1+ (1,0) [0|255] ""  gtw
 SG_ BMS_packSerialNumberByte01 m0 : 8|8@1+ (1,0) [0|255] ""  gtw
 SG_ BMS_packSerialNumberByte08 m1 : 8|8@1+ (1,0) [0|255] ""  gtw
 SG_ BMS_serialNumberMultiplexer M : 0|1@1+ (1,0) [0|1] ""  X

BO_ 1780 PMS_version: 8 VEH
 SG_ PMS_componentHardwareId : 56|8@1+ (1,0) [0|255] ""  X
 SG_ PMS_componentMaturity : 48|8@1+ (1,0) [0|255] ""  X
 SG_ PMS_componentBranchOrigin : 40|8@1+ (1,0) [0|255] ""  X
 SG_ PMS_componentMajorVersion : 32|8@1+ (1,0) [0|255] ""  X
 SG_ PMS_platformMaturity : 24|8@1+ (1,0) [0|255] ""  X
 SG_ PMS_platformBranchOrigin : 16|8@1+ (1,0) [0|255] ""  X
 SG_ PMS_platformMajorVersion : 8|8@1+ (1,0) [0|255] ""  X
 SG_ PMS_platformType : 0|8@1+ (1,0) [0|255] ""  X

BO_ 978 BMS_kwhCounter: 8 VEH
 SG_ BMS_kwhChargeTotal : 32|32@1+ (0.001,0) [0|268435.456] "KWh"  gtw
 SG_ BMS_kwhDischargeTotal : 0|32@1+ (0.001,0) [0|268435.456] "KWh"  gtw

BO_ 1290 HVP_alertLog: 8 VEH
 SG_ HVP_a033_pwmDutyCyleNegative m33 : 56|8@1+ (1,0) [0|255] "Percentage"  gtw
 SG_ HVP_a035_pwmDutyCyleNegative m35 : 56|8@1+ (1,0) [0|255] "Percentage"  gtw
 SG_ HVP_a050_negCtrState m50 : 51|3@1+ (1,0) [0|7] ""  gtw
 SG_ HVP_a049_negCtrState m49 : 51|3@1+ (1,0) [0|7] ""  gtw
 SG_ HVP_a020_shuntTemperature m20 : 48|16@1- (0.01,0) [-327.67|327.67] "C"  gtw
 SG_ HVP_a033_pwmDutyCylePositive m33 : 48|8@1+ (1,0) [0|255] "Percentage"  gtw
 SG_ HVP_a046_asicTemperature m46 : 48|16@1+ (0.01,0) [0|655.35] "C"  gtw
 SG_ HVP_a035_pwmDutyCylePositive m35 : 48|8@1+ (1,0) [0|255] "Percentage"  gtw
 SG_ HVP_a051_energyReserveV m51 : 48|16@1+ (0.001,0) [0|65.534] "V"  gtw
 SG_ HVP_a000_alertDataW2 m0 : 48|16@1+ (1,0) [0|65535] ""  X
 SG_ HVP_a050_posCtrState m50 : 48|3@1+ (1,0) [0|7] ""  gtw
 SG_ HVP_a049_posCtrState m49 : 48|3@1+ (1,0) [0|7] ""  gtw
 SG_ HVP_a036_pyroFiringAttempt m36 : 40|4@1+ (1,0) [0|15] ""  gtw
 SG_ HVP_a041_dcLinkOverVoltage m41 : 39|1@1+ (1,0) [0|1] ""  gtw
 SG_ HVP_a042_resetRequestRequired m42 : 39|1@1+ (1,0) [0|1] ""  gtw
 SG_ HVP_a010_primaryChainSensor m10 : 39|1@1+ (1,0) [0|1] ""  gtw
 SG_ HVP_a009_primaryChainSensor m9 : 39|1@1+ (1,0) [0|1] ""  gtw
 SG_ HVP_a042_packContactorOpening m42 : 38|1@1+ (1,0) [0|1] ""  gtw
 SG_ HVP_a008_primaryChainSensor m8 : 38|1@1+ (1,0) [0|1] ""  gtw
 SG_ HVP_a041_pyroFault m41 : 38|1@1+ (1,0) [0|1] ""  gtw
 SG_ HVP_a042_packContactorClosing m42 : 37|1@1+ (1,0) [0|1] ""  gtw
 SG_ HVP_a041_resetRequestRequired m41 : 37|1@1+ (1,0) [0|1] ""  gtw
 SG_ HVP_a042_shuntCurrentMia m42 : 36|1@1+ (1,0) [0|1] ""  gtw
 SG_ HVP_a041_fcContactorOpening m41 : 36|1@1+ (1,0) [0|1] ""  gtw
 SG_ HVP_a041_fcContactorClosing m41 : 35|1@1+ (1,0) [0|1] ""  gtw
 SG_ HVP_a042_shuntHwMia m42 : 35|1@1+ (1,0) [0|1] ""  gtw
 SG_ HVP_a041_gpoRequestActive m41 : 34|1@1+ (1,0) [0|1] ""  gtw
 SG_ HVP_a042_pcsFault m42 : 34|1@1+ (1,0) [0|1] ""  gtw
 SG_ HVP_a041_packVoltageMismatch m41 : 33|1@1+ (1,0) [0|1] ""  gtw
 SG_ HVP_a042_contactorStateWelded m42 : 33|1@1+ (1,0) [0|1] ""  gtw
 SG_ HVP_a047_auxCurrent m47 : 32|16@1+ (0.1,0) [0|6553.5] "A"  gtw
 SG_ HVP_a030_dcPositiveLinkV m30 : 32|16@1- (0.1,0) [-3276.8|3276.7] "V"  gtw
 SG_ HVP_a025_voltage2 m25 : 32|16@1+ (0.1,0) [0|6553.5] "V"  gtw
 SG_ HVP_a046_shuntTemperature m46 : 32|16@1+ (0.01,0) [0|655.35] "C"  gtw
 SG_ HVP_a050_coilCurrent m50 : 32|16@1+ (0.1,0) [0|6553.5] "A"  gtw
 SG_ HVP_a049_coilCurrent m49 : 32|16@1+ (0.1,0) [0|6553.5] "A"  gtw
 SG_ HVP_a000_alertDataW1 m0 : 32|16@1+ (1,0) [0|65535] ""  X
 SG_ HVP_a031_dcNegativeLinkV m31 : 32|16@1- (0.1,0) [-3276.8|3276.7] "V"  gtw
 SG_ HVP_a020_shuntCurrentAux m20 : 32|16@1- (0.1,0) [-3276.7|3276.7] "A"  gtw
 SG_ HVP_a035_coilCurrent m35 : 32|16@1+ (0.1,0) [0|6553.5] "A"  gtw
 SG_ HVP_a051_shuntCurrent m51 : 32|16@1- (0.1,0) [-3276.7|3276.7] "A"  gtw
 SG_ HVP_a041_secondaryBmbMia m41 : 32|1@1+ (1,0) [0|1] ""  gtw
 SG_ HVP_a028_sumOfBrickV m28 : 32|16@1+ (0.1,0) [0|6553.5] "V"  gtw
 SG_ HVP_a042_hvilFault m42 : 32|1@1+ (1,0) [0|1] ""  gtw
 SG_ HVP_a010_brickId m10 : 32|7@1+ (1,1) [1|128] ""  gtw
 SG_ HVP_a009_brickId m9 : 32|7@1+ (1,1) [1|128] ""  gtw
 SG_ HVP_a033_coilCurrent m33 : 32|16@1+ (0.1,0) [0|6553.5] "A"  gtw
 SG_ HVP_a044_contactorOpened m44 : 32|1@1+ (1,0) [0|1] ""  gtw
 SG_ HVP_a008_sensorId m8 : 32|6@1+ (1,0) [0|63] ""  gtw
 SG_ HVP_a034_brickId m34 : 32|7@1+ (1,1) [1|128] ""  gtw
 SG_ HVP_a042_packVoltageMismatch m42 : 31|1@1+ (1,0) [0|1] ""  gtw
 SG_ HVP_a044_packVoltageMismatch m44 : 31|1@1+ (1,0) [0|1] ""  gtw
 SG_ HVP_a041_shuntCurrentMia m41 : 31|1@1+ (1,0) [0|1] ""  gtw
 SG_ HVP_a041_shuntHwMia m41 : 30|1@1+ (1,0) [0|1] ""  gtw
 SG_ HVP_a044_bmsFault m44 : 30|1@1+ (1,0) [0|1] ""  gtw
 SG_ HVP_a042_bmsFault m42 : 30|1@1+ (1,0) [0|1] ""  gtw
 SG_ HVP_a042_supplyVer m42 : 29|1@1+ (1,0) [0|1] ""  gtw
 SG_ HVP_a044_supplyVer m44 : 29|1@1+ (1,0) [0|1] ""  gtw
 SG_ HVP_a041_pcsFault m41 : 29|1@1+ (1,0) [0|1] ""  gtw
 SG_ HVP_a044_supply12V m44 : 28|1@1+ (1,0) [0|1] ""  gtw
 SG_ HVP_a042_supply12V m42 : 28|1@1+ (1,0) [0|1] ""  gtw
 SG_ HVP_a041_contactorStateWelded m41 : 28|1@1+ (1,0) [0|1] ""  gtw
 SG_ HVP_a041_hvilFault m41 : 27|1@1+ (1,0) [0|1] ""  gtw
 SG_ HVP_a042_cpFault m42 : 27|1@1+ (1,0) [0|1] ""  gtw
 SG_ HVP_a044_cpFault m44 : 27|1@1+ (1,0) [0|1] ""  gtw
 SG_ HVP_a043_contactorOpened m43 : 27|1@1+ (1,0) [0|1] ""  gtw
 SG_ HVP_a042_secondaryBmbMia m42 : 26|1@1+ (1,0) [0|1] ""  gtw
 SG_ HVP_a043_bmbMia m43 : 26|1@1+ (1,0) [0|1] ""  gtw
 SG_ HVP_a044_secondaryBmbMia m44 : 26|1@1+ (1,0) [0|1] ""  gtw
 SG_ HVP_a041_bmbMia m41 : 26|1@1+ (1,0) [0|1] ""  gtw
 SG_ HVP_a044_cpMia m44 : 25|1@1+ (1,0) [0|1] ""  gtw
 SG_ HVP_a043_bmsFault m43 : 25|1@1+ (1,0) [0|1] ""  gtw
 SG_ HVP_a042_cpMia m42 : 25|1@1+ (1,0) [0|1] ""  gtw
 SG_ HVP_a041_bmsFault m41 : 25|1@1+ (1,0) [0|1] ""  gtw
 SG_ HVP_a041_notAllowedtoEnergize m41 : 24|1@1+ (1,0) [0|1] ""  gtw
 SG_ HVP_a036_pyroFiringTime m36 : 24|16@1+ (1,0) [0|65535] ""  gtw
 SG_ HVP_a044_bmsHvsMia m44 : 24|1@1+ (1,0) [0|1] ""  gtw
 SG_ HVP_a021_VstTestFailed m21 : 24|1@1+ (1,0) [0|1] ""  gtw
 SG_ HVP_a042_bmsHvsMia m42 : 24|1@1+ (1,0) [0|1] ""  gtw
 SG_ HVP_a043_notAllowedtoEnergize m43 : 24|1@1+ (1,0) [0|1] ""  gtw
 SG_ HVP_a041_packContactorHw m41 : 23|1@1+ (1,0) [0|1] ""  gtw
 SG_ HVP_a042_notAllowedtoEnergize m42 : 23|1@1+ (1,0) [0|1] ""  gtw
 SG_ HVP_a044_notAllowedtoEnergize m44 : 23|1@1+ (1,0) [0|1] ""  gtw
 SG_ HVP_a021_SquibResTestFailed m21 : 23|1@1+ (1,0) [0|1] ""  gtw
 SG_ HVP_a043_packContactorHw m43 : 23|1@1+ (1,0) [0|1] ""  gtw
 SG_ HVP_a021_SquibLeakTestFailed m21 : 22|1@1+ (1,0) [0|1] ""  gtw
 SG_ HVP_a044_fcContactorHw m44 : 22|1@1+ (1,0) [0|1] ""  gtw
 SG_ HVP_a043_crashEvent m43 : 22|1@1+ (1,0) [0|1] ""  gtw
 SG_ HVP_a042_fcContactorHw m42 : 22|1@1+ (1,0) [0|1] ""  gtw
 SG_ HVP_a041_crashEvent m41 : 22|1@1+ (1,0) [0|1] ""  gtw
 SG_ HVP_a042_crashEvent m42 : 21|1@1+ (1,0) [0|1] ""  gtw
 SG_ HVP_a041_underVoltage m41 : 21|1@1+ (1,0) [0|1] ""  gtw
 SG_ HVP_a021_RefCurrentTestFailed m21 : 21|1@1+ (1,0) [0|1] ""  gtw
 SG_ HVP_a044_crashEvent m44 : 21|1@1+ (1,0) [0|1] ""  gtw
 SG_ HVP_a043_underVoltage m43 : 21|1@1+ (1,0) [0|1] ""  gtw
 SG_ HVP_a042_overTemperature m42 : 20|1@1+ (1,0) [0|1] ""  gtw
 SG_ HVP_a021_LowSideLeakTestFailed m21 : 20|1@1+ (1,0) [0|1] ""  gtw
 SG_ HVP_a044_overTemperature m44 : 20|1@1+ (1,0) [0|1] ""  gtw
 SG_ HVP_a043_overTemperature m43 : 20|1@1+ (1,0) [0|1] ""  gtw
 SG_ HVP_a041_overTemperature m41 : 20|1@1+ (1,0) [0|1] ""  gtw
 SG_ HVP_a041_overVoltage m41 : 19|1@1+ (1,0) [0|1] ""  gtw
 SG_ HVP_a044_overVoltage m44 : 19|1@1+ (1,0) [0|1] ""  gtw
 SG_ HVP_a042_overVoltage m42 : 19|1@1+ (1,0) [0|1] ""  gtw
 SG_ HVP_a021_HighSideLeakTestFailed m21 : 19|1@1+ (1,0) [0|1] ""  gtw
 SG_ HVP_a043_overVoltage m43 : 19|1@1+ (1,0) [0|1] ""  gtw
 SG_ HVP_a043_overDischargeCurrent m43 : 18|1@1+ (1,0) [0|1] ""  gtw
 SG_ HVP_a041_overDischargeCurrent m41 : 18|1@1+ (1,0) [0|1] ""  gtw
 SG_ HVP_a021_ErTestFailed m21 : 18|1@1+ (1,0) [0|1] ""  gtw
 SG_ HVP_a042_overDischargeCurrent m42 : 18|1@1+ (1,0) [0|1] ""  gtw
 SG_ HVP_a044_overDischargeCurrent m44 : 18|1@1+ (1,0) [0|1] ""  gtw
 SG_ HVP_a043_overChargeCurrent m43 : 17|1@1+ (1,0) [0|1] ""  gtw
 SG_ HVP_a044_overChargeCurrent m44 : 17|1@1+ (1,0) [0|1] ""  gtw
 SG_ HVP_a042_overChargeCurrent m42 : 17|1@1+ (1,0) [0|1] ""  gtw
 SG_ HVP_a040_negContactorFailed m40 : 17|1@1+ (1,0) [0|1] ""  gtw
 SG_ HVP_a041_overChargeCurrent m41 : 17|1@1+ (1,0) [0|1] ""  gtw
 SG_ HVP_a039_negContactorFailed m39 : 17|1@1+ (1,0) [0|1] ""  gtw
 SG_ HVP_a047_shuntCurrent m47 : 16|16@1+ (0.1,0) [0|6553.5] "A"  gtw
 SG_ HVP_a007_current m7 : 16|24@1+ (0.001,0) [0|16777.215] "A"  gtw
 SG_ HVP_a031_packNegativeLinkV m31 : 16|16@1- (0.1,0) [-3276.8|3276.7] "V"  gtw
 SG_ HVP_a020_energyReserveV m20 : 16|16@1+ (0.001,0) [0|65.534] "V"  gtw
 SG_ HVP_a050_contactorPowerV m50 : 16|16@1+ (0.1,0) [0|6553.5] "V"  gtw
 SG_ HVP_a049_contactorPowerV m49 : 16|16@1+ (0.1,0) [0|6553.5] "V"  gtw
 SG_ HVP_a042_overCurrent m42 : 16|1@1+ (1,0) [0|1] ""  gtw
 SG_ HVP_a008_temperature m8 : 16|16@1+ (0.01,0) [0|655.35] "C"  gtw
 SG_ HVP_a045_dcLinkVoltage m45 : 16|16@1+ (0.1,0) [0|6553.5] "V"  gtw
 SG_ HVP_a033_contactorPowerV m33 : 16|16@1+ (0.1,0) [0|6553.5] "V"  gtw
 SG_ HVP_a034_brickVoltage m34 : 16|16@1- (0.001,0) [-5|5] "V"  gtw
 SG_ HVP_a037_pyroFiringHandle m37 : 16|4@1+ (1,0) [1|12] ""  gtw
 SG_ HVP_a006_current m6 : 16|24@1+ (0.001,0) [0|16777.215] "A"  gtw
 SG_ HVP_a009_brickVoltage m9 : 16|16@1+ (0.001,0) [0|65.535] "V"  gtw
 SG_ HVP_a035_contactorPowerV m35 : 16|16@1+ (0.1,0) [0|6553.5] "V"  gtw
 SG_ HVP_a010_brickVoltage m10 : 16|16@1- (0.001,0) [-5|5] "V"  gtw
 SG_ HVP_a041_overCurrent m41 : 16|1@1+ (1,0) [0|1] ""  gtw
 SG_ HVP_a021_pyroStatus m21 : 16|2@1+ (1,0) [0|3] ""  gtw
 SG_ HVP_a040_posContactorFailed m40 : 16|1@1+ (1,0) [0|1] ""  gtw
 SG_ HVP_a036_pyroFiringHandle m36 : 16|4@1+ (1,0) [1|12] ""  gtw
 SG_ HVP_a028_packVoltage m28 : 16|16@1+ (0.1,0) [0|6553.5] "V"  gtw
 SG_ HVP_a000_alertDataW0 m0 : 16|16@1+ (1,0) [0|65535] ""  X
 SG_ HVP_a024_voltage m24 : 16|16@1+ (0.1,0) [0|6553.5] "V"  gtw
 SG_ HVP_a051_shuntTemperature m51 : 16|16@1- (0.01,0) [-327.67|327.67] "C"  gtw
 SG_ HVP_a025_voltage1 m25 : 16|16@1+ (0.1,0) [0|6553.5] "V"  gtw
 SG_ HVP_a005_current m5 : 16|24@1+ (0.001,0) [0|16777.215] "A"  gtw
 SG_ HVP_a046_shuntCurrent m46 : 16|16@1+ (0.1,0) [0|6553.5] "A"  gtw
 SG_ HVP_a044_overCurrent m44 : 16|1@1+ (1,0) [0|1] ""  gtw
 SG_ HVP_a030_packPositiveLinkV m30 : 16|16@1- (0.1,0) [-3276.8|3276.7] "V"  gtw
 SG_ HVP_a048_logId m48 : 16|4@1+ (1,0) [0|15] ""  gtw
 SG_ HVP_a043_overCurrent m43 : 16|1@1+ (1,0) [0|1] ""  gtw
 SG_ HVP_a039_posContactorFailed m39 : 16|1@1+ (1,0) [0|1] ""  gtw
 SG_ HVP_a003_programCounter m3 : 16|32@1+ (1,0) [0|4294967295] ""  gtw
 SG_ HVP_a026_hvilStatus m26 : 16|4@1+ (1,0) [0|8] ""  gtw
 SG_ HVP_alertSet : 15|1@1+ (1,0) [0|1] ""  gtw
 SG_ HVP_alertID M : 0|6@1+ (1,0) [0|51] ""  dbg

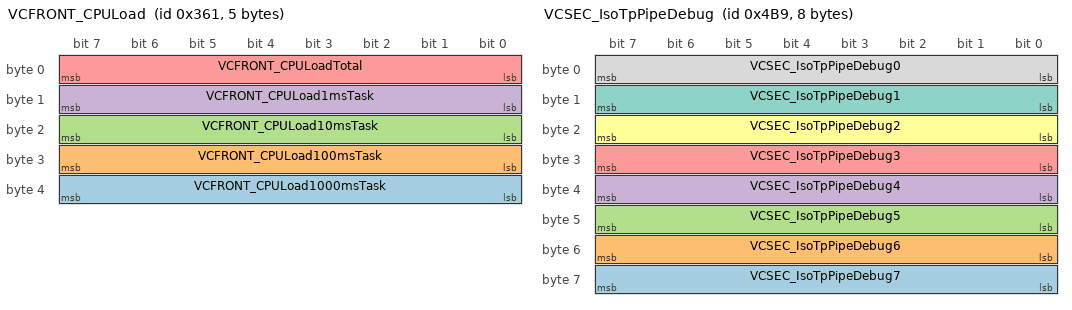
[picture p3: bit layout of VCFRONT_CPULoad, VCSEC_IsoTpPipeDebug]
BO_ 865 VCFRONT_CPULoad: 5 VEH
 SG_ VCFRONT_CPULoad1000msTask : 32|8@1+ (1,0) [0|255] ""  X
 SG_ VCFRONT_CPULoad100msTask : 24|8@1+ (1,0) [0|255] ""  X
 SG_ VCFRONT_CPULoad10msTask : 16|8@1+ (1,0) [0|255] ""  X
 SG_ VCFRONT_CPULoad1msTask : 8|8@1+ (1,0) [0|255] ""  X
 SG_ VCFRONT_CPULoadTotal : 0|8@1+ (1,0) [0|255] ""  X

BO_ 1878 XCP_vcleftRequest: 8 VEH
 SG_ XCP_vcleftRequestData : 7|64@0+ (1,0) [0|18446744073709551615] ""  vcleft

BO_ 1209 VCSEC_IsoTpPipeDebug: 8 VEH
 SG_ VCSEC_IsoTpPipeDebug7 : 56|8@1+ (1,0) [0|255] ""  X
 SG_ VCSEC_IsoTpPipeDebug6 : 48|8@1+ (1,0) [0|255] ""  X
 SG_ VCSEC_IsoTpPipeDebug5 : 40|8@1+ (1,0) [0|255] ""  X
 SG_ VCSEC_IsoTpPipeDebug4 : 32|8@1+ (1,0) [0|255] ""  X
 SG_ VCSEC_IsoTpPipeDebug3 : 24|8@1+ (1,0) [0|255] ""  X
 SG_ VCSEC_IsoTpPipeDebug2 : 16|8@1+ (1,0) [0|255] ""  X
 SG_ VCSEC_IsoTpPipeDebug1 : 8|8@1+ (1,0) [0|255] ""  X
 SG_ VCSEC_IsoTpPipeDebug0 : 0|8@1+ (1,0) [0|255] ""  X

BA_DEF_ SG_  "SystemSignalLongSymbol" STRING ;
BA_DEF_DEF_  "SystemSignalLongSymbol" "";
BA_ "SystemSignalLongSymbol" SG_ 1448 EPBR_a117_VEH_intrusionSensorSta "EPBR_a117_VEH_intrusionSensorStatus";
VAL_ 1448 EPBR_a174_nonterminalReason 5 "CSM_FAULT_APPLY_BLOCKED" 19 "CSM_FAULT_EPBM_MIA" 1 "CSM_FAULT_EPBM_DISABLED" 16 "CSM_FAULT_MOTOR_IDLE_FAULT" 8 "CSM_FAULT_TIMEOUT_APPLY_INRUSH" 3 "CSM_FAULT_STATE_MISMATCH" 13 "CSM_FAULT_TIMEOUT_EPBM_CUTOFF" 15 "CSM_FAULT_TIMEOUT_EPBM_START" 2 "CSM_FAULT_EPBM_FAULTED" 4 "CSM_FAULT_TIMEOUT_CALIBRATE" 12 "CSM_FAULT_TIMEOUT_RELEASE_COMPLETE" 17 "CSM_FAULT_MOTOR_ACTIVE_FAULT" 18 "CSM_FAULT_MOTOR_NOT_READY" 11 "CSM_FAULT_TIMEOUT_RELEASE_WAIT_FOR_ENDSTOP" 0 "CSM_FAULT_NONE" 9 "CSM_FAULT_TIMEOUT_WAIT_FOR_CLAMP" 14 "CSM_FAULT_TIMEOUT_NO_RAMP" 10 "CSM_FAULT_TIMEOUT_RELEASE_INRUSH" 21 "CSM_FAULT_REMOTE_MIA" 20 "CSM_FAULT_NVM_MISMATCH" 6 "CSM_FAULT_RELEASE_BLOCKED" 7 "CSM_FAULT_TIMEOUT_APPLY_COMPLETE" ;
VAL_ 1448 EPBR_a190_nonterminalReason 5 "CSM_FAULT_APPLY_BLOCKED" 19 "CSM_FAULT_EPBM_MIA" 1 "CSM_FAULT_EPBM_DISABLED" 16 "CSM_FAULT_MOTOR_IDLE_FAULT" 8 "CSM_FAULT_TIMEOUT_APPLY_INRUSH" 3 "CSM_FAULT_STATE_MISMATCH" 13 "CSM_FAULT_TIMEOUT_EPBM_CUTOFF" 15 "CSM_FAULT_TIMEOUT_EPBM_START" 2 "CSM_FAULT_EPBM_FAULTED" 4 "CSM_FAULT_TIMEOUT_CALIBRATE" 12 "CSM_FAULT_TIMEOUT_RELEASE_COMPLETE" 17 "CSM_FAULT_MOTOR_ACTIVE_FAULT" 18 "CSM_FAULT_MOTOR_NOT_READY" 11 "CSM_FAULT_TIMEOUT_RELEASE_WAIT_FOR_ENDSTOP" 0 "CSM_FAULT_NONE" 9 "CSM_FAULT_TIMEOUT_WAIT_FOR_CLAMP" 14 "CSM_FAULT_TIMEOUT_NO_RAMP" 10 "CSM_FAULT_TIMEOUT_RELEASE_INRUSH" 21 "CSM_FAULT_REMOTE_MIA" 20 "CSM_FAULT_NVM_MISMATCH" 6 "CSM_FAULT_RELEASE_BLOCKED" 7 "CSM_FAULT_TIMEOUT_APPLY_COMPLETE" ;
VAL_ 1448 EPBR_a175_nonterminalReason 5 "CSM_FAULT_APPLY_BLOCKED" 19 "CSM_FAULT_EPBM_MIA" 1 "CSM_FAULT_EPBM_DISABLED" 16 "CSM_FAULT_MOTOR_IDLE_FAULT" 8 "CSM_FAULT_TIMEOUT_APPLY_INRUSH" 3 "CSM_FAULT_STATE_MISMATCH" 13 "CSM_FAULT_TIMEOUT_EPBM_CUTOFF" 15 "CSM_FAULT_TIMEOUT_EPBM_START" 2 "CSM_FAULT_EPBM_FAULTED" 4 "CSM_FAULT_TIMEOUT_CALIBRATE" 12 "CSM_FAULT_TIMEOUT_RELEASE_COMPLETE" 17 "CSM_FAULT_MOTOR_ACTIVE_FAULT" 18 "CSM_FAULT_MOTOR_NOT_READY" 11 "CSM_FAULT_TIMEOUT_RELEASE_WAIT_FOR_ENDSTOP" 0 "CSM_FAULT_NONE" 9 "CSM_FAULT_TIMEOUT_WAIT_FOR_CLAMP" 14 "CSM_FAULT_TIMEOUT_NO_RAMP" 10 "CSM_FAULT_TIMEOUT_RELEASE_INRUSH" 21 "CSM_FAULT_REMOTE_MIA" 20 "CSM_FAULT_NVM_MISMATCH" 6 "CSM_FAULT_RELEASE_BLOCKED" 7 "CSM_FAULT_TIMEOUT_APPLY_COMPLETE" ;
VAL_ 1448 EPBR_a247_nonterminalReason 5 "CSM_FAULT_APPLY_BLOCKED" 19 "CSM_FAULT_EPBM_MIA" 1 "CSM_FAULT_EPBM_DISABLED" 16 "CSM_FAULT_MOTOR_IDLE_FAULT" 8 "CSM_FAULT_TIMEOUT_APPLY_INRUSH" 3 "CSM_FAULT_STATE_MISMATCH" 13 "CSM_FAULT_TIMEOUT_EPBM_CUTOFF" 15 "CSM_FAULT_TIMEOUT_EPBM_START" 2 "CSM_FAULT_EPBM_FAULTED" 4 "CSM_FAULT_TIMEOUT_CALIBRATE" 12 "CSM_FAULT_TIMEOUT_RELEASE_COMPLETE" 17 "CSM_FAULT_MOTOR_ACTIVE_FAULT" 18 "CSM_FAULT_MOTOR_NOT_READY" 11 "CSM_FAULT_TIMEOUT_RELEASE_WAIT_FOR_ENDSTOP" 0 "CSM_FAULT_NONE" 9 "CSM_FAULT_TIMEOUT_WAIT_FOR_CLAMP" 14 "CSM_FAULT_TIMEOUT_NO_RAMP" 10 "CSM_FAULT_TIMEOUT_RELEASE_INRUSH" 21 "CSM_FAULT_REMOTE_MIA" 20 "CSM_FAULT_NVM_MISMATCH" 6 "CSM_FAULT_RELEASE_BLOCKED" 7 "CSM_FAULT_TIMEOUT_APPLY_COMPLETE" ;
VAL_ 1448 EPBR_a191_nonterminalReason 5 "CSM_FAULT_APPLY_BLOCKED" 19 "CSM_FAULT_EPBM_MIA" 1 "CSM_FAULT_EPBM_DISABLED" 16 "CSM_FAULT_MOTOR_IDLE_FAULT" 8 "CSM_FAULT_TIMEOUT_APPLY_INRUSH" 3 "CSM_FAULT_STATE_MISMATCH" 13 "CSM_FAULT_TIMEOUT_EPBM_CUTOFF" 15 "CSM_FAULT_TIMEOUT_EPBM_START" 2 "CSM_FAULT_EPBM_FAULTED" 4 "CSM_FAULT_TIMEOUT_CALIBRATE" 12 "CSM_FAULT_TIMEOUT_RELEASE_COMPLETE" 17 "CSM_FAULT_MOTOR_ACTIVE_FAULT" 18 "CSM_FAULT_MOTOR_NOT_READY" 11 "CSM_FAULT_TIMEOUT_RELEASE_WAIT_FOR_ENDSTOP" 0 "CSM_FAULT_NONE" 9 "CSM_FAULT_TIMEOUT_WAIT_FOR_CLAMP" 14 "CSM_FAULT_TIMEOUT_NO_RAMP" 10 "CSM_FAULT_TIMEOUT_RELEASE_INRUSH" 21 "CSM_FAULT_REMOTE_MIA" 20 "CSM_FAULT_NVM_MISMATCH" 6 "CSM_FAULT_RELEASE_BLOCKED" 7 "CSM_FAULT_TIMEOUT_APPLY_COMPLETE" ;
VAL_ 1448 EPBR_a179_nonterminalReason 5 "CSM_FAULT_APPLY_BLOCKED" 19 "CSM_FAULT_EPBM_MIA" 1 "CSM_FAULT_EPBM_DISABLED" 16 "CSM_FAULT_MOTOR_IDLE_FAULT" 8 "CSM_FAULT_TIMEOUT_APPLY_INRUSH" 3 "CSM_FAULT_STATE_MISMATCH" 13 "CSM_FAULT_TIMEOUT_EPBM_CUTOFF" 15 "CSM_FAULT_TIMEOUT_EPBM_START" 2 "CSM_FAULT_EPBM_FAULTED" 4 "CSM_FAULT_TIMEOUT_CALIBRATE" 12 "CSM_FAULT_TIMEOUT_RELEASE_COMPLETE" 17 "CSM_FAULT_MOTOR_ACTIVE_FAULT" 18 "CSM_FAULT_MOTOR_NOT_READY" 11 "CSM_FAULT_TIMEOUT_RELEASE_WAIT_FOR_ENDSTOP" 0 "CSM_FAULT_NONE" 9 "CSM_FAULT_TIMEOUT_WAIT_FOR_CLAMP" 14 "CSM_FAULT_TIMEOUT_NO_RAMP" 10 "CSM_FAULT_TIMEOUT_RELEASE_INRUSH" 21 "CSM_FAULT_REMOTE_MIA" 20 "CSM_FAULT_NVM_MISMATCH" 6 "CSM_FAULT_RELEASE_BLOCKED" 7 "CSM_FAULT_TIMEOUT_APPLY_COMPLETE" ;
VAL_ 1448 EPBR_a176_nonterminalReason 5 "CSM_FAULT_APPLY_BLOCKED" 19 "CSM_FAULT_EPBM_MIA" 1 "CSM_FAULT_EPBM_DISABLED" 16 "CSM_FAULT_MOTOR_IDLE_FAULT" 8 "CSM_FAULT_TIMEOUT_APPLY_INRUSH" 3 "CSM_FAULT_STATE_MISMATCH" 13 "CSM_FAULT_TIMEOUT_EPBM_CUTOFF" 15 "CSM_FAULT_TIMEOUT_EPBM_START" 2 "CSM_FAULT_EPBM_FAULTED" 4 "CSM_FAULT_TIMEOUT_CALIBRATE" 12 "CSM_FAULT_TIMEOUT_RELEASE_COMPLETE" 17 "CSM_FAULT_MOTOR_ACTIVE_FAULT" 18 "CSM_FAULT_MOTOR_NOT_READY" 11 "CSM_FAULT_TIMEOUT_RELEASE_WAIT_FOR_ENDSTOP" 0 "CSM_FAULT_NONE" 9 "CSM_FAULT_TIMEOUT_WAIT_FOR_CLAMP" 14 "CSM_FAULT_TIMEOUT_NO_RAMP" 10 "CSM_FAULT_TIMEOUT_RELEASE_INRUSH" 21 "CSM_FAULT_REMOTE_MIA" 20 "CSM_FAULT_NVM_MISMATCH" 6 "CSM_FAULT_RELEASE_BLOCKED" 7 "CSM_FAULT_TIMEOUT_APPLY_COMPLETE" ;
VAL_ 1448 EPBR_a248_nonterminalReason 5 "CSM_FAULT_APPLY_BLOCKED" 19 "CSM_FAULT_EPBM_MIA" 1 "CSM_FAULT_EPBM_DISABLED" 16 "CSM_FAULT_MOTOR_IDLE_FAULT" 8 "CSM_FAULT_TIMEOUT_APPLY_INRUSH" 3 "CSM_FAULT_STATE_MISMATCH" 13 "CSM_FAULT_TIMEOUT_EPBM_CUTOFF" 15 "CSM_FAULT_TIMEOUT_EPBM_START" 2 "CSM_FAULT_EPBM_FAULTED" 4 "CSM_FAULT_TIMEOUT_CALIBRATE" 12 "CSM_FAULT_TIMEOUT_RELEASE_COMPLETE" 17 "CSM_FAULT_MOTOR_ACTIVE_FAULT" 18 "CSM_FAULT_MOTOR_NOT_READY" 11 "CSM_FAULT_TIMEOUT_RELEASE_WAIT_FOR_ENDSTOP" 0 "CSM_FAULT_NONE" 9 "CSM_FAULT_TIMEOUT_WAIT_FOR_CLAMP" 14 "CSM_FAULT_TIMEOUT_NO_RAMP" 10 "CSM_FAULT_TIMEOUT_RELEASE_INRUSH" 21 "CSM_FAULT_REMOTE_MIA" 20 "CSM_FAULT_NVM_MISMATCH" 6 "CSM_FAULT_RELEASE_BLOCKED" 7 "CSM_FAULT_TIMEOUT_APPLY_COMPLETE" ;
VAL_ 1448 EPBR_a177_nonterminalReason 5 "CSM_FAULT_APPLY_BLOCKED" 19 "CSM_FAULT_EPBM_MIA" 1 "CSM_FAULT_EPBM_DISABLED" 16 "CSM_FAULT_MOTOR_IDLE_FAULT" 8 "CSM_FAULT_TIMEOUT_APPLY_INRUSH" 3 "CSM_FAULT_STATE_MISMATCH" 13 "CSM_FAULT_TIMEOUT_EPBM_CUTOFF" 15 "CSM_FAULT_TIMEOUT_EPBM_START" 2 "CSM_FAULT_EPBM_FAULTED" 4 "CSM_FAULT_TIMEOUT_CALIBRATE" 12 "CSM_FAULT_TIMEOUT_RELEASE_COMPLETE" 17 "CSM_FAULT_MOTOR_ACTIVE_FAULT" 18 "CSM_FAULT_MOTOR_NOT_READY" 11 "CSM_FAULT_TIMEOUT_RELEASE_WAIT_FOR_ENDSTOP" 0 "CSM_FAULT_NONE" 9 "CSM_FAULT_TIMEOUT_WAIT_FOR_CLAMP" 14 "CSM_FAULT_TIMEOUT_NO_RAMP" 10 "CSM_FAULT_TIMEOUT_RELEASE_INRUSH" 21 "CSM_FAULT_REMOTE_MIA" 20 "CSM_FAULT_NVM_MISMATCH" 6 "CSM_FAULT_RELEASE_BLOCKED" 7 "CSM_FAULT_TIMEOUT_APPLY_COMPLETE" ;
VAL_ 1448 EPBR_a138_monitorState 5 "EPB_SAVED_CALIPERSTATE_SERVICE" 1 "EPB_SAVED_CALIPERSTATE_UNKNOWN" 4 "EPB_SAVED_CALIPERSTATE_OPEN" 2 "EPB_SAVED_CALIPERSTATE_REAPPLY" 0 "EPB_SAVED_CALIPERSTATE_UNSAVED" 3 "EPB_SAVED_CALIPERSTATE_PARK" ;
VAL_ 1448 EPBR_a177_esmOpTrigger 20 "EPB_TRIGGER_TIMEOUT" 2 "EPB_TRIGGER_PBUTTON_PRESSED_FAST" 19 "EPB_TRIGGER_SPEED_FAST" 3 "EPB_TRIGGER_PBUTTON_PRESSED_UNKNOWN" 27 "EPB_TRIGGER_EPBM_DISQUALIFIED" 10 "EPB_TRIGGER_WINCHMODE_UNAVAILABLE" 28 "EPB_TRIGGER_ACCELERATION" 12 "EPB_TRIGGER_DIAG_CLOSE" 24 "EPB_TRIGGER_FAULT" 25 "EPB_TRIGGER_SUMMON_FAULT" 30 "EPB_TRIGGER_DRIVER_IS_LEAVING" 18 "EPB_TRIGGER_SPEED_OKAYTOPARK" 1 "EPB_TRIGGER_PBUTTON_PRESSED_OKTOPARK" 4 "EPB_TRIGGER_PBUTTON_RELEASED" 14 "EPB_TRIGGER_DIAG_EXIT" 21 "EPB_TRIGGER_SAVESTATE_ON_BOOT" 6 "EPB_TRIGGER_DI_UNPARK" 23 "EPB_TRIGGER_SUMMON_COMPLETE" 22 "EPB_TRIGGER_REAPPLY" 26 "EPB_TRIGGER_DISQUALIFIED" 16 "EPB_TRIGGER_USER_CANCEL" 13 "EPB_TRIGGER_DIAG_OPEN" 11 "EPB_TRIGGER_SERVICE" 5 "EPB_TRIGGER_ACTIVE_PARK_REQUEST" 15 "EPB_TRIGGER_USER_CONFIRMED" 8 "EPB_TRIGGER_WINCHMODE_EXIT" 9 "EPB_TRIGGER_WINCHMODE_ENTER" 17 "EPB_TRIGGER_SPEED_STOPPED" 0 "EPB_TRIGGER_PBUTTON_PRESSED_STOPPED" 7 "EPB_TRIGGER_TOUCHSCREEN" 29 "EPB_TRIGGER_SYSTEM_APPLY" ;
VAL_ 1448 EPBR_a248_esmOpTrigger 20 "EPB_TRIGGER_TIMEOUT" 2 "EPB_TRIGGER_PBUTTON_PRESSED_FAST" 19 "EPB_TRIGGER_SPEED_FAST" 3 "EPB_TRIGGER_PBUTTON_PRESSED_UNKNOWN" 27 "EPB_TRIGGER_EPBM_DISQUALIFIED" 10 "EPB_TRIGGER_WINCHMODE_UNAVAILABLE" 28 "EPB_TRIGGER_ACCELERATION" 12 "EPB_TRIGGER_DIAG_CLOSE" 24 "EPB_TRIGGER_FAULT" 25 "EPB_TRIGGER_SUMMON_FAULT" 30 "EPB_TRIGGER_DRIVER_IS_LEAVING" 18 "EPB_TRIGGER_SPEED_OKAYTOPARK" 1 "EPB_TRIGGER_PBUTTON_PRESSED_OKTOPARK" 4 "EPB_TRIGGER_PBUTTON_RELEASED" 14 "EPB_TRIGGER_DIAG_EXIT" 21 "EPB_TRIGGER_SAVESTATE_ON_BOOT" 6 "EPB_TRIGGER_DI_UNPARK" 23 "EPB_TRIGGER_SUMMON_COMPLETE" 22 "EPB_TRIGGER_REAPPLY" 26 "EPB_TRIGGER_DISQUALIFIED" 16 "EPB_TRIGGER_USER_CANCEL" 13 "EPB_TRIGGER_DIAG_OPEN" 11 "EPB_TRIGGER_SERVICE" 5 "EPB_TRIGGER_ACTIVE_PARK_REQUEST" 15 "EPB_TRIGGER_USER_CONFIRMED" 8 "EPB_TRIGGER_WINCHMODE_EXIT" 9 "EPB_TRIGGER_WINCHMODE_ENTER" 17 "EPB_TRIGGER_SPEED_STOPPED" 0 "EPB_TRIGGER_PBUTTON_PRESSED_STOPPED" 7 "EPB_TRIGGER_TOUCHSCREEN" 29 "EPB_TRIGGER_SYSTEM_APPLY" ;
VAL_ 1448 EPBR_a190_esmOpTrigger 20 "EPB_TRIGGER_TIMEOUT" 2 "EPB_TRIGGER_PBUTTON_PRESSED_FAST" 19 "EPB_TRIGGER_SPEED_FAST" 3 "EPB_TRIGGER_PBUTTON_PRESSED_UNKNOWN" 27 "EPB_TRIGGER_EPBM_DISQUALIFIED" 10 "EPB_TRIGGER_WINCHMODE_UNAVAILABLE" 28 "EPB_TRIGGER_ACCELERATION" 12 "EPB_TRIGGER_DIAG_CLOSE" 24 "EPB_TRIGGER_FAULT" 25 "EPB_TRIGGER_SUMMON_FAULT" 30 "EPB_TRIGGER_DRIVER_IS_LEAVING" 18 "EPB_TRIGGER_SPEED_OKAYTOPARK" 1 "EPB_TRIGGER_PBUTTON_PRESSED_OKTOPARK" 4 "EPB_TRIGGER_PBUTTON_RELEASED" 14 "EPB_TRIGGER_DIAG_EXIT" 21 "EPB_TRIGGER_SAVESTATE_ON_BOOT" 6 "EPB_TRIGGER_DI_UNPARK" 23 "EPB_TRIGGER_SUMMON_COMPLETE" 22 "EPB_TRIGGER_REAPPLY" 26 "EPB_TRIGGER_DISQUALIFIED" 16 "EPB_TRIGGER_USER_CANCEL" 13 "EPB_TRIGGER_DIAG_OPEN" 11 "EPB_TRIGGER_SERVICE" 5 "EPB_TRIGGER_ACTIVE_PARK_REQUEST" 15 "EPB_TRIGGER_USER_CONFIRMED" 8 "EPB_TRIGGER_WINCHMODE_EXIT" 9 "EPB_TRIGGER_WINCHMODE_ENTER" 17 "EPB_TRIGGER_SPEED_STOPPED" 0 "EPB_TRIGGER_PBUTTON_PRESSED_STOPPED" 7 "EPB_TRIGGER_TOUCHSCREEN" 29 "EPB_TRIGGER_SYSTEM_APPLY" ;
VAL_ 1448 EPBR_a174_esmOpTrigger 20 "EPB_TRIGGER_TIMEOUT" 2 "EPB_TRIGGER_PBUTTON_PRESSED_FAST" 19 "EPB_TRIGGER_SPEED_FAST" 3 "EPB_TRIGGER_PBUTTON_PRESSED_UNKNOWN" 27 "EPB_TRIGGER_EPBM_DISQUALIFIED" 10 "EPB_TRIGGER_WINCHMODE_UNAVAILABLE" 28 "EPB_TRIGGER_ACCELERATION" 12 "EPB_TRIGGER_DIAG_CLOSE" 24 "EPB_TRIGGER_FAULT" 25 "EPB_TRIGGER_SUMMON_FAULT" 30 "EPB_TRIGGER_DRIVER_IS_LEAVING" 18 "EPB_TRIGGER_SPEED_OKAYTOPARK" 1 "EPB_TRIGGER_PBUTTON_PRESSED_OKTOPARK" 4 "EPB_TRIGGER_PBUTTON_RELEASED" 14 "EPB_TRIGGER_DIAG_EXIT" 21 "EPB_TRIGGER_SAVESTATE_ON_BOOT" 6 "EPB_TRIGGER_DI_UNPARK" 23 "EPB_TRIGGER_SUMMON_COMPLETE" 22 "EPB_TRIGGER_REAPPLY" 26 "EPB_TRIGGER_DISQUALIFIED" 16 "EPB_TRIGGER_USER_CANCEL" 13 "EPB_TRIGGER_DIAG_OPEN" 11 "EPB_TRIGGER_SERVICE" 5 "EPB_TRIGGER_ACTIVE_PARK_REQUEST" 15 "EPB_TRIGGER_USER_CONFIRMED" 8 "EPB_TRIGGER_WINCHMODE_EXIT" 9 "EPB_TRIGGER_WINCHMODE_ENTER" 17 "EPB_TRIGGER_SPEED_STOPPED" 0 "EPB_TRIGGER_PBUTTON_PRESSED_STOPPED" 7 "EPB_TRIGGER_TOUCHSCREEN" 29 "EPB_TRIGGER_SYSTEM_APPLY" ;
VAL_ 1448 EPBR_a138_localState 5 "EPB_SAVED_CALIPERSTATE_SERVICE" 1 "EPB_SAVED_CALIPERSTATE_UNKNOWN" 4 "EPB_SAVED_CALIPERSTATE_OPEN" 2 "EPB_SAVED_CALIPERSTATE_REAPPLY" 0 "EPB_SAVED_CALIPERSTATE_UNSAVED" 3 "EPB_SAVED_CALIPERSTATE_PARK" ;
VAL_ 1448 EPBR_a247_esmOpTrigger 20 "EPB_TRIGGER_TIMEOUT" 2 "EPB_TRIGGER_PBUTTON_PRESSED_FAST" 19 "EPB_TRIGGER_SPEED_FAST" 3 "EPB_TRIGGER_PBUTTON_PRESSED_UNKNOWN" 27 "EPB_TRIGGER_EPBM_DISQUALIFIED" 10 "EPB_TRIGGER_WINCHMODE_UNAVAILABLE" 28 "EPB_TRIGGER_ACCELERATION" 12 "EPB_TRIGGER_DIAG_CLOSE" 24 "EPB_TRIGGER_FAULT" 25 "EPB_TRIGGER_SUMMON_FAULT" 30 "EPB_TRIGGER_DRIVER_IS_LEAVING" 18 "EPB_TRIGGER_SPEED_OKAYTOPARK" 1 "EPB_TRIGGER_PBUTTON_PRESSED_OKTOPARK" 4 "EPB_TRIGGER_PBUTTON_RELEASED" 14 "EPB_TRIGGER_DIAG_EXIT" 21 "EPB_TRIGGER_SAVESTATE_ON_BOOT" 6 "EPB_TRIGGER_DI_UNPARK" 23 "EPB_TRIGGER_SUMMON_COMPLETE" 22 "EPB_TRIGGER_REAPPLY" 26 "EPB_TRIGGER_DISQUALIFIED" 16 "EPB_TRIGGER_USER_CANCEL" 13 "EPB_TRIGGER_DIAG_OPEN" 11 "EPB_TRIGGER_SERVICE" 5 "EPB_TRIGGER_ACTIVE_PARK_REQUEST" 15 "EPB_TRIGGER_USER_CONFIRMED" 8 "EPB_TRIGGER_WINCHMODE_EXIT" 9 "EPB_TRIGGER_WINCHMODE_ENTER" 17 "EPB_TRIGGER_SPEED_STOPPED" 0 "EPB_TRIGGER_PBUTTON_PRESSED_STOPPED" 7 "EPB_TRIGGER_TOUCHSCREEN" 29 "EPB_TRIGGER_SYSTEM_APPLY" ;
VAL_ 1448 EPBR_a191_esmOpTrigger 20 "EPB_TRIGGER_TIMEOUT" 2 "EPB_TRIGGER_PBUTTON_PRESSED_FAST" 19 "EPB_TRIGGER_SPEED_FAST" 3 "EPB_TRIGGER_PBUTTON_PRESSED_UNKNOWN" 27 "EPB_TRIGGER_EPBM_DISQUALIFIED" 10 "EPB_TRIGGER_WINCHMODE_UNAVAILABLE" 28 "EPB_TRIGGER_ACCELERATION" 12 "EPB_TRIGGER_DIAG_CLOSE" 24 "EPB_TRIGGER_FAULT" 25 "EPB_TRIGGER_SUMMON_FAULT" 30 "EPB_TRIGGER_DRIVER_IS_LEAVING" 18 "EPB_TRIGGER_SPEED_OKAYTOPARK" 1 "EPB_TRIGGER_PBUTTON_PRESSED_OKTOPARK" 4 "EPB_TRIGGER_PBUTTON_RELEASED" 14 "EPB_TRIGGER_DIAG_EXIT" 21 "EPB_TRIGGER_SAVESTATE_ON_BOOT" 6 "EPB_TRIGGER_DI_UNPARK" 23 "EPB_TRIGGER_SUMMON_COMPLETE" 22 "EPB_TRIGGER_REAPPLY" 26 "EPB_TRIGGER_DISQUALIFIED" 16 "EPB_TRIGGER_USER_CANCEL" 13 "EPB_TRIGGER_DIAG_OPEN" 11 "EPB_TRIGGER_SERVICE" 5 "EPB_TRIGGER_ACTIVE_PARK_REQUEST" 15 "EPB_TRIGGER_USER_CONFIRMED" 8 "EPB_TRIGGER_WINCHMODE_EXIT" 9 "EPB_TRIGGER_WINCHMODE_ENTER" 17 "EPB_TRIGGER_SPEED_STOPPED" 0 "EPB_TRIGGER_PBUTTON_PRESSED_STOPPED" 7 "EPB_TRIGGER_TOUCHSCREEN" 29 "EPB_TRIGGER_SYSTEM_APPLY" ;
VAL_ 1448 EPBR_a175_esmOpTrigger 20 "EPB_TRIGGER_TIMEOUT" 2 "EPB_TRIGGER_PBUTTON_PRESSED_FAST" 19 "EPB_TRIGGER_SPEED_FAST" 3 "EPB_TRIGGER_PBUTTON_PRESSED_UNKNOWN" 27 "EPB_TRIGGER_EPBM_DISQUALIFIED" 10 "EPB_TRIGGER_WINCHMODE_UNAVAILABLE" 28 "EPB_TRIGGER_ACCELERATION" 12 "EPB_TRIGGER_DIAG_CLOSE" 24 "EPB_TRIGGER_FAULT" 25 "EPB_TRIGGER_SUMMON_FAULT" 30 "EPB_TRIGGER_DRIVER_IS_LEAVING" 18 "EPB_TRIGGER_SPEED_OKAYTOPARK" 1 "EPB_TRIGGER_PBUTTON_PRESSED_OKTOPARK" 4 "EPB_TRIGGER_PBUTTON_RELEASED" 14 "EPB_TRIGGER_DIAG_EXIT" 21 "EPB_TRIGGER_SAVESTATE_ON_BOOT" 6 "EPB_TRIGGER_DI_UNPARK" 23 "EPB_TRIGGER_SUMMON_COMPLETE" 22 "EPB_TRIGGER_REAPPLY" 26 "EPB_TRIGGER_DISQUALIFIED" 16 "EPB_TRIGGER_USER_CANCEL" 13 "EPB_TRIGGER_DIAG_OPEN" 11 "EPB_TRIGGER_SERVICE" 5 "EPB_TRIGGER_ACTIVE_PARK_REQUEST" 15 "EPB_TRIGGER_USER_CONFIRMED" 8 "EPB_TRIGGER_WINCHMODE_EXIT" 9 "EPB_TRIGGER_WINCHMODE_ENTER" 17 "EPB_TRIGGER_SPEED_STOPPED" 0 "EPB_TRIGGER_PBUTTON_PRESSED_STOPPED" 7 "EPB_TRIGGER_TOUCHSCREEN" 29 "EPB_TRIGGER_SYSTEM_APPLY" ;
VAL_ 1448 EPBR_a176_esmOpTrigger 20 "EPB_TRIGGER_TIMEOUT" 2 "EPB_TRIGGER_PBUTTON_PRESSED_FAST" 19 "EPB_TRIGGER_SPEED_FAST" 3 "EPB_TRIGGER_PBUTTON_PRESSED_UNKNOWN" 27 "EPB_TRIGGER_EPBM_DISQUALIFIED" 10 "EPB_TRIGGER_WINCHMODE_UNAVAILABLE" 28 "EPB_TRIGGER_ACCELERATION" 12 "EPB_TRIGGER_DIAG_CLOSE" 24 "EPB_TRIGGER_FAULT" 25 "EPB_TRIGGER_SUMMON_FAULT" 30 "EPB_TRIGGER_DRIVER_IS_LEAVING" 18 "EPB_TRIGGER_SPEED_OKAYTOPARK" 1 "EPB_TRIGGER_PBUTTON_PRESSED_OKTOPARK" 4 "EPB_TRIGGER_PBUTTON_RELEASED" 14 "EPB_TRIGGER_DIAG_EXIT" 21 "EPB_TRIGGER_SAVESTATE_ON_BOOT" 6 "EPB_TRIGGER_DI_UNPARK" 23 "EPB_TRIGGER_SUMMON_COMPLETE" 22 "EPB_TRIGGER_REAPPLY" 26 "EPB_TRIGGER_DISQUALIFIED" 16 "EPB_TRIGGER_USER_CANCEL" 13 "EPB_TRIGGER_DIAG_OPEN" 11 "EPB_TRIGGER_SERVICE" 5 "EPB_TRIGGER_ACTIVE_PARK_REQUEST" 15 "EPB_TRIGGER_USER_CONFIRMED" 8 "EPB_TRIGGER_WINCHMODE_EXIT" 9 "EPB_TRIGGER_WINCHMODE_ENTER" 17 "EPB_TRIGGER_SPEED_STOPPED" 0 "EPB_TRIGGER_PBUTTON_PRESSED_STOPPED" 7 "EPB_TRIGGER_TOUCHSCREEN" 29 "EPB_TRIGGER_SYSTEM_APPLY" ;
VAL_ 1448 EPBR_a179_esmOpTrigger 20 "EPB_TRIGGER_TIMEOUT" 2 "EPB_TRIGGER_PBUTTON_PRESSED_FAST" 19 "EPB_TRIGGER_SPEED_FAST" 3 "EPB_TRIGGER_PBUTTON_PRESSED_UNKNOWN" 27 "EPB_TRIGGER_EPBM_DISQUALIFIED" 10 "EPB_TRIGGER_WINCHMODE_UNAVAILABLE" 28 "EPB_TRIGGER_ACCELERATION" 12 "EPB_TRIGGER_DIAG_CLOSE" 24 "EPB_TRIGGER_FAULT" 25 "EPB_TRIGGER_SUMMON_FAULT" 30 "EPB_TRIGGER_DRIVER_IS_LEAVING" 18 "EPB_TRIGGER_SPEED_OKAYTOPARK" 1 "EPB_TRIGGER_PBUTTON_PRESSED_OKTOPARK" 4 "EPB_TRIGGER_PBUTTON_RELEASED" 14 "EPB_TRIGGER_DIAG_EXIT" 21 "EPB_TRIGGER_SAVESTATE_ON_BOOT" 6 "EPB_TRIGGER_DI_UNPARK" 23 "EPB_TRIGGER_SUMMON_COMPLETE" 22 "EPB_TRIGGER_REAPPLY" 26 "EPB_TRIGGER_DISQUALIFIED" 16 "EPB_TRIGGER_USER_CANCEL" 13 "EPB_TRIGGER_DIAG_OPEN" 11 "EPB_TRIGGER_SERVICE" 5 "EPB_TRIGGER_ACTIVE_PARK_REQUEST" 15 "EPB_TRIGGER_USER_CONFIRMED" 8 "EPB_TRIGGER_WINCHMODE_EXIT" 9 "EPB_TRIGGER_WINCHMODE_ENTER" 17 "EPB_TRIGGER_SPEED_STOPPED" 0 "EPB_TRIGGER_PBUTTON_PRESSED_STOPPED" 7 "EPB_TRIGGER_TOUCHSCREEN" 29 "EPB_TRIGGER_SYSTEM_APPLY" ;
VAL_ 1448 EPBR_a183_invalidateReason 0 "EPB_CDP_ESP_MIA" 3 "EPB_CDP_EPBM_INVALID" 2 "EPB_CDP_EPBM_MIA" 1 "EPB_CDP_ESP_INVALID" ;
VAL_ 1448 EPBR_a247_csmFaultReason 5 "CSM_FAULT_APPLY_BLOCKED" 19 "CSM_FAULT_EPBM_MIA" 1 "CSM_FAULT_EPBM_DISABLED" 16 "CSM_FAULT_MOTOR_IDLE_FAULT" 8 "CSM_FAULT_TIMEOUT_APPLY_INRUSH" 3 "CSM_FAULT_STATE_MISMATCH" 13 "CSM_FAULT_TIMEOUT_EPBM_CUTOFF" 15 "CSM_FAULT_TIMEOUT_EPBM_START" 2 "CSM_FAULT_EPBM_FAULTED" 4 "CSM_FAULT_TIMEOUT_CALIBRATE" 12 "CSM_FAULT_TIMEOUT_RELEASE_COMPLETE" 17 "CSM_FAULT_MOTOR_ACTIVE_FAULT" 18 "CSM_FAULT_MOTOR_NOT_READY" 11 "CSM_FAULT_TIMEOUT_RELEASE_WAIT_FOR_ENDSTOP" 0 "CSM_FAULT_NONE" 9 "CSM_FAULT_TIMEOUT_WAIT_FOR_CLAMP" 14 "CSM_FAULT_TIMEOUT_NO_RAMP" 10 "CSM_FAULT_TIMEOUT_RELEASE_INRUSH" 21 "CSM_FAULT_REMOTE_MIA" 20 "CSM_FAULT_NVM_MISMATCH" 6 "CSM_FAULT_RELEASE_BLOCKED" 7 "CSM_FAULT_TIMEOUT_APPLY_COMPLETE" ;
VAL_ 1448 EPBR_a183_nextState 11 "ESM_PARK_PENDING" 1 "ESM_PARK" 3 "ESM_OPEN" 5 "ESM_SUMMON" 0 "ESM_INIT" 6 "ESM_WINCHMODE" 13 "ESM_SUMMON_PARK" 18 "ESM_DYNAMIC_EXTERNAL_EXIT" 19 "ESM_UNKNOWN" 12 "ESM_WINCHMODE_PENDING" 8 "ESM_DIAGNOSTIC_PARK" 16 "ESM_LATCHED_DYNAMIC_EXTERNAL" 2 "ESM_REAPPLY" 9 "ESM_DIAGNOSTIC_OPEN" 14 "ESM_DYNAMIC_EXTERNAL" 10 "ESM_DYNAMIC_PARK" 17 "ESM_SERVICE_PENDING" 15 "ESM_DYNAMIC_PENDING" 7 "ESM_SERVICE" 4 "ESM_DYNAMIC" ;
VAL_ 1448 EPBR_a191_csmFaultReason 5 "CSM_FAULT_APPLY_BLOCKED" 19 "CSM_FAULT_EPBM_MIA" 1 "CSM_FAULT_EPBM_DISABLED" 16 "CSM_FAULT_MOTOR_IDLE_FAULT" 8 "CSM_FAULT_TIMEOUT_APPLY_INRUSH" 3 "CSM_FAULT_STATE_MISMATCH" 13 "CSM_FAULT_TIMEOUT_EPBM_CUTOFF" 15 "CSM_FAULT_TIMEOUT_EPBM_START" 2 "CSM_FAULT_EPBM_FAULTED" 4 "CSM_FAULT_TIMEOUT_CALIBRATE" 12 "CSM_FAULT_TIMEOUT_RELEASE_COMPLETE" 17 "CSM_FAULT_MOTOR_ACTIVE_FAULT" 18 "CSM_FAULT_MOTOR_NOT_READY" 11 "CSM_FAULT_TIMEOUT_RELEASE_WAIT_FOR_ENDSTOP" 0 "CSM_FAULT_NONE" 9 "CSM_FAULT_TIMEOUT_WAIT_FOR_CLAMP" 14 "CSM_FAULT_TIMEOUT_NO_RAMP" 10 "CSM_FAULT_TIMEOUT_RELEASE_INRUSH" 21 "CSM_FAULT_REMOTE_MIA" 20 "CSM_FAULT_NVM_MISMATCH" 6 "CSM_FAULT_RELEASE_BLOCKED" 7 "CSM_FAULT_TIMEOUT_APPLY_COMPLETE" ;
VAL_ 1448 EPBR_a186_nextState 11 "ESM_PARK_PENDING" 1 "ESM_PARK" 3 "ESM_OPEN" 5 "ESM_SUMMON" 0 "ESM_INIT" 6 "ESM_WINCHMODE" 13 "ESM_SUMMON_PARK" 18 "ESM_DYNAMIC_EXTERNAL_EXIT" 19 "ESM_UNKNOWN" 12 "ESM_WINCHMODE_PENDING" 8 "ESM_DIAGNOSTIC_PARK" 16 "ESM_LATCHED_DYNAMIC_EXTERNAL" 2 "ESM_REAPPLY" 9 "ESM_DIAGNOSTIC_OPEN" 14 "ESM_DYNAMIC_EXTERNAL" 10 "ESM_DYNAMIC_PARK" 17 "ESM_SERVICE_PENDING" 15 "ESM_DYNAMIC_PENDING" 7 "ESM_SERVICE" 4 "ESM_DYNAMIC" ;
VAL_ 1448 EPBR_a246_esmOpTrigger 20 "EPB_TRIGGER_TIMEOUT" 2 "EPB_TRIGGER_PBUTTON_PRESSED_FAST" 19 "EPB_TRIGGER_SPEED_FAST" 3 "EPB_TRIGGER_PBUTTON_PRESSED_UNKNOWN" 27 "EPB_TRIGGER_EPBM_DISQUALIFIED" 10 "EPB_TRIGGER_WINCHMODE_UNAVAILABLE" 28 "EPB_TRIGGER_ACCELERATION" 12 "EPB_TRIGGER_DIAG_CLOSE" 24 "EPB_TRIGGER_FAULT" 25 "EPB_TRIGGER_SUMMON_FAULT" 30 "EPB_TRIGGER_DRIVER_IS_LEAVING" 18 "EPB_TRIGGER_SPEED_OKAYTOPARK" 1 "EPB_TRIGGER_PBUTTON_PRESSED_OKTOPARK" 4 "EPB_TRIGGER_PBUTTON_RELEASED" 14 "EPB_TRIGGER_DIAG_EXIT" 21 "EPB_TRIGGER_SAVESTATE_ON_BOOT" 6 "EPB_TRIGGER_DI_UNPARK" 23 "EPB_TRIGGER_SUMMON_COMPLETE" 22 "EPB_TRIGGER_REAPPLY" 26 "EPB_TRIGGER_DISQUALIFIED" 16 "EPB_TRIGGER_USER_CANCEL" 13 "EPB_TRIGGER_DIAG_OPEN" 11 "EPB_TRIGGER_SERVICE" 5 "EPB_TRIGGER_ACTIVE_PARK_REQUEST" 15 "EPB_TRIGGER_USER_CONFIRMED" 8 "EPB_TRIGGER_WINCHMODE_EXIT" 9 "EPB_TRIGGER_WINCHMODE_ENTER" 17 "EPB_TRIGGER_SPEED_STOPPED" 0 "EPB_TRIGGER_PBUTTON_PRESSED_STOPPED" 7 "EPB_TRIGGER_TOUCHSCREEN" 29 "EPB_TRIGGER_SYSTEM_APPLY" ;
VAL_ 1448 EPBR_a180_nextState 11 "ESM_PARK_PENDING" 1 "ESM_PARK" 3 "ESM_OPEN" 5 "ESM_SUMMON" 0 "ESM_INIT" 6 "ESM_WINCHMODE" 13 "ESM_SUMMON_PARK" 18 "ESM_DYNAMIC_EXTERNAL_EXIT" 19 "ESM_UNKNOWN" 12 "ESM_WINCHMODE_PENDING" 8 "ESM_DIAGNOSTIC_PARK" 16 "ESM_LATCHED_DYNAMIC_EXTERNAL" 2 "ESM_REAPPLY" 9 "ESM_DIAGNOSTIC_OPEN" 14 "ESM_DYNAMIC_EXTERNAL" 10 "ESM_DYNAMIC_PARK" 17 "ESM_SERVICE_PENDING" 15 "ESM_DYNAMIC_PENDING" 7 "ESM_SERVICE" 4 "ESM_DYNAMIC" ;
VAL_ 1448 EPBR_a174_csmFaultReason 5 "CSM_FAULT_APPLY_BLOCKED" 19 "CSM_FAULT_EPBM_MIA" 1 "CSM_FAULT_EPBM_DISABLED" 16 "CSM_FAULT_MOTOR_IDLE_FAULT" 8 "CSM_FAULT_TIMEOUT_APPLY_INRUSH" 3 "CSM_FAULT_STATE_MISMATCH" 13 "CSM_FAULT_TIMEOUT_EPBM_CUTOFF" 15 "CSM_FAULT_TIMEOUT_EPBM_START" 2 "CSM_FAULT_EPBM_FAULTED" 4 "CSM_FAULT_TIMEOUT_CALIBRATE" 12 "CSM_FAULT_TIMEOUT_RELEASE_COMPLETE" 17 "CSM_FAULT_MOTOR_ACTIVE_FAULT" 18 "CSM_FAULT_MOTOR_NOT_READY" 11 "CSM_FAULT_TIMEOUT_RELEASE_WAIT_FOR_ENDSTOP" 0 "CSM_FAULT_NONE" 9 "CSM_FAULT_TIMEOUT_WAIT_FOR_CLAMP" 14 "CSM_FAULT_TIMEOUT_NO_RAMP" 10 "CSM_FAULT_TIMEOUT_RELEASE_INRUSH" 21 "CSM_FAULT_REMOTE_MIA" 20 "CSM_FAULT_NVM_MISMATCH" 6 "CSM_FAULT_RELEASE_BLOCKED" 7 "CSM_FAULT_TIMEOUT_APPLY_COMPLETE" ;
VAL_ 1448 EPBR_a187_nextState 11 "ESM_PARK_PENDING" 1 "ESM_PARK" 3 "ESM_OPEN" 5 "ESM_SUMMON" 0 "ESM_INIT" 6 "ESM_WINCHMODE" 13 "ESM_SUMMON_PARK" 18 "ESM_DYNAMIC_EXTERNAL_EXIT" 19 "ESM_UNKNOWN" 12 "ESM_WINCHMODE_PENDING" 8 "ESM_DIAGNOSTIC_PARK" 16 "ESM_LATCHED_DYNAMIC_EXTERNAL" 2 "ESM_REAPPLY" 9 "ESM_DIAGNOSTIC_OPEN" 14 "ESM_DYNAMIC_EXTERNAL" 10 "ESM_DYNAMIC_PARK" 17 "ESM_SERVICE_PENDING" 15 "ESM_DYNAMIC_PENDING" 7 "ESM_SERVICE" 4 "ESM_DYNAMIC" ;
VAL_ 1448 EPBR_a190_csmFaultReason 5 "CSM_FAULT_APPLY_BLOCKED" 19 "CSM_FAULT_EPBM_MIA" 1 "CSM_FAULT_EPBM_DISABLED" 16 "CSM_FAULT_MOTOR_IDLE_FAULT" 8 "CSM_FAULT_TIMEOUT_APPLY_INRUSH" 3 "CSM_FAULT_STATE_MISMATCH" 13 "CSM_FAULT_TIMEOUT_EPBM_CUTOFF" 15 "CSM_FAULT_TIMEOUT_EPBM_START" 2 "CSM_FAULT_EPBM_FAULTED" 4 "CSM_FAULT_TIMEOUT_CALIBRATE" 12 "CSM_FAULT_TIMEOUT_RELEASE_COMPLETE" 17 "CSM_FAULT_MOTOR_ACTIVE_FAULT" 18 "CSM_FAULT_MOTOR_NOT_READY" 11 "CSM_FAULT_TIMEOUT_RELEASE_WAIT_FOR_ENDSTOP" 0 "CSM_FAULT_NONE" 9 "CSM_FAULT_TIMEOUT_WAIT_FOR_CLAMP" 14 "CSM_FAULT_TIMEOUT_NO_RAMP" 10 "CSM_FAULT_TIMEOUT_RELEASE_INRUSH" 21 "CSM_FAULT_REMOTE_MIA" 20 "CSM_FAULT_NVM_MISMATCH" 6 "CSM_FAULT_RELEASE_BLOCKED" 7 "CSM_FAULT_TIMEOUT_APPLY_COMPLETE" ;
VAL_ 1448 EPBR_a249_esmOpTrigger 20 "EPB_TRIGGER_TIMEOUT" 2 "EPB_TRIGGER_PBUTTON_PRESSED_FAST" 19 "EPB_TRIGGER_SPEED_FAST" 3 "EPB_TRIGGER_PBUTTON_PRESSED_UNKNOWN" 27 "EPB_TRIGGER_EPBM_DISQUALIFIED" 10 "EPB_TRIGGER_WINCHMODE_UNAVAILABLE" 28 "EPB_TRIGGER_ACCELERATION" 12 "EPB_TRIGGER_DIAG_CLOSE" 24 "EPB_TRIGGER_FAULT" 25 "EPB_TRIGGER_SUMMON_FAULT" 30 "EPB_TRIGGER_DRIVER_IS_LEAVING" 18 "EPB_TRIGGER_SPEED_OKAYTOPARK" 1 "EPB_TRIGGER_PBUTTON_PRESSED_OKTOPARK" 4 "EPB_TRIGGER_PBUTTON_RELEASED" 14 "EPB_TRIGGER_DIAG_EXIT" 21 "EPB_TRIGGER_SAVESTATE_ON_BOOT" 6 "EPB_TRIGGER_DI_UNPARK" 23 "EPB_TRIGGER_SUMMON_COMPLETE" 22 "EPB_TRIGGER_REAPPLY" 26 "EPB_TRIGGER_DISQUALIFIED" 16 "EPB_TRIGGER_USER_CANCEL" 13 "EPB_TRIGGER_DIAG_OPEN" 11 "EPB_TRIGGER_SERVICE" 5 "EPB_TRIGGER_ACTIVE_PARK_REQUEST" 15 "EPB_TRIGGER_USER_CONFIRMED" 8 "EPB_TRIGGER_WINCHMODE_EXIT" 9 "EPB_TRIGGER_WINCHMODE_ENTER" 17 "EPB_TRIGGER_SPEED_STOPPED" 0 "EPB_TRIGGER_PBUTTON_PRESSED_STOPPED" 7 "EPB_TRIGGER_TOUCHSCREEN" 29 "EPB_TRIGGER_SYSTEM_APPLY" ;
VAL_ 1448 EPBR_a184_nextState 11 "ESM_PARK_PENDING" 1 "ESM_PARK" 3 "ESM_OPEN" 5 "ESM_SUMMON" 0 "ESM_INIT" 6 "ESM_WINCHMODE" 13 "ESM_SUMMON_PARK" 18 "ESM_DYNAMIC_EXTERNAL_EXIT" 19 "ESM_UNKNOWN" 12 "ESM_WINCHMODE_PENDING" 8 "ESM_DIAGNOSTIC_PARK" 16 "ESM_LATCHED_DYNAMIC_EXTERNAL" 2 "ESM_REAPPLY" 9 "ESM_DIAGNOSTIC_OPEN" 14 "ESM_DYNAMIC_EXTERNAL" 10 "ESM_DYNAMIC_PARK" 17 "ESM_SERVICE_PENDING" 15 "ESM_DYNAMIC_PENDING" 7 "ESM_SERVICE" 4 "ESM_DYNAMIC" ;
VAL_ 1448 EPBR_a248_csmFaultReason 5 "CSM_FAULT_APPLY_BLOCKED" 19 "CSM_FAULT_EPBM_MIA" 1 "CSM_FAULT_EPBM_DISABLED" 16 "CSM_FAULT_MOTOR_IDLE_FAULT" 8 "CSM_FAULT_TIMEOUT_APPLY_INRUSH" 3 "CSM_FAULT_STATE_MISMATCH" 13 "CSM_FAULT_TIMEOUT_EPBM_CUTOFF" 15 "CSM_FAULT_TIMEOUT_EPBM_START" 2 "CSM_FAULT_EPBM_FAULTED" 4 "CSM_FAULT_TIMEOUT_CALIBRATE" 12 "CSM_FAULT_TIMEOUT_RELEASE_COMPLETE" 17 "CSM_FAULT_MOTOR_ACTIVE_FAULT" 18 "CSM_FAULT_MOTOR_NOT_READY" 11 "CSM_FAULT_TIMEOUT_RELEASE_WAIT_FOR_ENDSTOP" 0 "CSM_FAULT_NONE" 9 "CSM_FAULT_TIMEOUT_WAIT_FOR_CLAMP" 14 "CSM_FAULT_TIMEOUT_NO_RAMP" 10 "CSM_FAULT_TIMEOUT_RELEASE_INRUSH" 21 "CSM_FAULT_REMOTE_MIA" 20 "CSM_FAULT_NVM_MISMATCH" 6 "CSM_FAULT_RELEASE_BLOCKED" 7 "CSM_FAULT_TIMEOUT_APPLY_COMPLETE" ;
VAL_ 1448 EPBR_a177_csmFaultReason 5 "CSM_FAULT_APPLY_BLOCKED" 19 "CSM_FAULT_EPBM_MIA" 1 "CSM_FAULT_EPBM_DISABLED" 16 "CSM_FAULT_MOTOR_IDLE_FAULT" 8 "CSM_FAULT_TIMEOUT_APPLY_INRUSH" 3 "CSM_FAULT_STATE_MISMATCH" 13 "CSM_FAULT_TIMEOUT_EPBM_CUTOFF" 15 "CSM_FAULT_TIMEOUT_EPBM_START" 2 "CSM_FAULT_EPBM_FAULTED" 4 "CSM_FAULT_TIMEOUT_CALIBRATE" 12 "CSM_FAULT_TIMEOUT_RELEASE_COMPLETE" 17 "CSM_FAULT_MOTOR_ACTIVE_FAULT" 18 "CSM_FAULT_MOTOR_NOT_READY" 11 "CSM_FAULT_TIMEOUT_RELEASE_WAIT_FOR_ENDSTOP" 0 "CSM_FAULT_NONE" 9 "CSM_FAULT_TIMEOUT_WAIT_FOR_CLAMP" 14 "CSM_FAULT_TIMEOUT_NO_RAMP" 10 "CSM_FAULT_TIMEOUT_RELEASE_INRUSH" 21 "CSM_FAULT_REMOTE_MIA" 20 "CSM_FAULT_NVM_MISMATCH" 6 "CSM_FAULT_RELEASE_BLOCKED" 7 "CSM_FAULT_TIMEOUT_APPLY_COMPLETE" ;
VAL_ 1448 EPBR_a179_csmFaultReason 5 "CSM_FAULT_APPLY_BLOCKED" 19 "CSM_FAULT_EPBM_MIA" 1 "CSM_FAULT_EPBM_DISABLED" 16 "CSM_FAULT_MOTOR_IDLE_FAULT" 8 "CSM_FAULT_TIMEOUT_APPLY_INRUSH" 3 "CSM_FAULT_STATE_MISMATCH" 13 "CSM_FAULT_TIMEOUT_EPBM_CUTOFF" 15 "CSM_FAULT_TIMEOUT_EPBM_START" 2 "CSM_FAULT_EPBM_FAULTED" 4 "CSM_FAULT_TIMEOUT_CALIBRATE" 12 "CSM_FAULT_TIMEOUT_RELEASE_COMPLETE" 17 "CSM_FAULT_MOTOR_ACTIVE_FAULT" 18 "CSM_FAULT_MOTOR_NOT_READY" 11 "CSM_FAULT_TIMEOUT_RELEASE_WAIT_FOR_ENDSTOP" 0 "CSM_FAULT_NONE" 9 "CSM_FAULT_TIMEOUT_WAIT_FOR_CLAMP" 14 "CSM_FAULT_TIMEOUT_NO_RAMP" 10 "CSM_FAULT_TIMEOUT_RELEASE_INRUSH" 21 "CSM_FAULT_REMOTE_MIA" 20 "CSM_FAULT_NVM_MISMATCH" 6 "CSM_FAULT_RELEASE_BLOCKED" 7 "CSM_FAULT_TIMEOUT_APPLY_COMPLETE" ;
VAL_ 1448 EPBR_a188_nextState 11 "ESM_PARK_PENDING" 1 "ESM_PARK" 3 "ESM_OPEN" 5 "ESM_SUMMON" 0 "ESM_INIT" 6 "ESM_WINCHMODE" 13 "ESM_SUMMON_PARK" 18 "ESM_DYNAMIC_EXTERNAL_EXIT" 19 "ESM_UNKNOWN" 12 "ESM_WINCHMODE_PENDING" 8 "ESM_DIAGNOSTIC_PARK" 16 "ESM_LATCHED_DYNAMIC_EXTERNAL" 2 "ESM_REAPPLY" 9 "ESM_DIAGNOSTIC_OPEN" 14 "ESM_DYNAMIC_EXTERNAL" 10 "ESM_DYNAMIC_PARK" 17 "ESM_SERVICE_PENDING" 15 "ESM_DYNAMIC_PENDING" 7 "ESM_SERVICE" 4 "ESM_DYNAMIC" ;
VAL_ 1448 EPBR_a176_csmFaultReason 5 "CSM_FAULT_APPLY_BLOCKED" 19 "CSM_FAULT_EPBM_MIA" 1 "CSM_FAULT_EPBM_DISABLED" 16 "CSM_FAULT_MOTOR_IDLE_FAULT" 8 "CSM_FAULT_TIMEOUT_APPLY_INRUSH" 3 "CSM_FAULT_STATE_MISMATCH" 13 "CSM_FAULT_TIMEOUT_EPBM_CUTOFF" 15 "CSM_FAULT_TIMEOUT_EPBM_START" 2 "CSM_FAULT_EPBM_FAULTED" 4 "CSM_FAULT_TIMEOUT_CALIBRATE" 12 "CSM_FAULT_TIMEOUT_RELEASE_COMPLETE" 17 "CSM_FAULT_MOTOR_ACTIVE_FAULT" 18 "CSM_FAULT_MOTOR_NOT_READY" 11 "CSM_FAULT_TIMEOUT_RELEASE_WAIT_FOR_ENDSTOP" 0 "CSM_FAULT_NONE" 9 "CSM_FAULT_TIMEOUT_WAIT_FOR_CLAMP" 14 "CSM_FAULT_TIMEOUT_NO_RAMP" 10 "CSM_FAULT_TIMEOUT_RELEASE_INRUSH" 21 "CSM_FAULT_REMOTE_MIA" 20 "CSM_FAULT_NVM_MISMATCH" 6 "CSM_FAULT_RELEASE_BLOCKED" 7 "CSM_FAULT_TIMEOUT_APPLY_COMPLETE" ;
VAL_ 1448 EPBR_a189_nextState 11 "ESM_PARK_PENDING" 1 "ESM_PARK" 3 "ESM_OPEN" 5 "ESM_SUMMON" 0 "ESM_INIT" 6 "ESM_WINCHMODE" 13 "ESM_SUMMON_PARK" 18 "ESM_DYNAMIC_EXTERNAL_EXIT" 19 "ESM_UNKNOWN" 12 "ESM_WINCHMODE_PENDING" 8 "ESM_DIAGNOSTIC_PARK" 16 "ESM_LATCHED_DYNAMIC_EXTERNAL" 2 "ESM_REAPPLY" 9 "ESM_DIAGNOSTIC_OPEN" 14 "ESM_DYNAMIC_EXTERNAL" 10 "ESM_DYNAMIC_PARK" 17 "ESM_SERVICE_PENDING" 15 "ESM_DYNAMIC_PENDING" 7 "ESM_SERVICE" 4 "ESM_DYNAMIC" ;
VAL_ 1448 EPBR_a175_csmFaultReason 5 "CSM_FAULT_APPLY_BLOCKED" 19 "CSM_FAULT_EPBM_MIA" 1 "CSM_FAULT_EPBM_DISABLED" 16 "CSM_FAULT_MOTOR_IDLE_FAULT" 8 "CSM_FAULT_TIMEOUT_APPLY_INRUSH" 3 "CSM_FAULT_STATE_MISMATCH" 13 "CSM_FAULT_TIMEOUT_EPBM_CUTOFF" 15 "CSM_FAULT_TIMEOUT_EPBM_START" 2 "CSM_FAULT_EPBM_FAULTED" 4 "CSM_FAULT_TIMEOUT_CALIBRATE" 12 "CSM_FAULT_TIMEOUT_RELEASE_COMPLETE" 17 "CSM_FAULT_MOTOR_ACTIVE_FAULT" 18 "CSM_FAULT_MOTOR_NOT_READY" 11 "CSM_FAULT_TIMEOUT_RELEASE_WAIT_FOR_ENDSTOP" 0 "CSM_FAULT_NONE" 9 "CSM_FAULT_TIMEOUT_WAIT_FOR_CLAMP" 14 "CSM_FAULT_TIMEOUT_NO_RAMP" 10 "CSM_FAULT_TIMEOUT_RELEASE_INRUSH" 21 "CSM_FAULT_REMOTE_MIA" 20 "CSM_FAULT_NVM_MISMATCH" 6 "CSM_FAULT_RELEASE_BLOCKED" 7 "CSM_FAULT_TIMEOUT_APPLY_COMPLETE" ;
VAL_ 1448 EPBR_a176_monitorFaultStatus 1 "EPB_STATUS_RETRY" 3 "EPB_STATUS_FAULT_IDLE" 0 "EPB_STATUS_NOMINAL" 2 "EPB_STATUS_FAULT" ;
VAL_ 1448 EPBR_a249_faultStatus 1 "EPB_STATUS_RETRY" 3 "EPB_STATUS_FAULT_IDLE" 0 "EPB_STATUS_NOMINAL" 2 "EPB_STATUS_FAULT" ;
VAL_ 1448 EPBR_a177_monitorFaultStatus 1 "EPB_STATUS_RETRY" 3 "EPB_STATUS_FAULT_IDLE" 0 "EPB_STATUS_NOMINAL" 2 "EPB_STATUS_FAULT" ;
VAL_ 1448 EPBR_a174_monitorFaultStatus 1 "EPB_STATUS_RETRY" 3 "EPB_STATUS_FAULT_IDLE" 0 "EPB_STATUS_NOMINAL" 2 "EPB_STATUS_FAULT" ;
VAL_ 1448 EPBR_a179_monitorFaultStatus 1 "EPB_STATUS_RETRY" 3 "EPB_STATUS_FAULT_IDLE" 0 "EPB_STATUS_NOMINAL" 2 "EPB_STATUS_FAULT" ;
VAL_ 1448 EPBR_a190_monitorFaultStatus 1 "EPB_STATUS_RETRY" 3 "EPB_STATUS_FAULT_IDLE" 0 "EPB_STATUS_NOMINAL" 2 "EPB_STATUS_FAULT" ;
VAL_ 1448 EPBR_a248_monitorFaultStatus 1 "EPB_STATUS_RETRY" 3 "EPB_STATUS_FAULT_IDLE" 0 "EPB_STATUS_NOMINAL" 2 "EPB_STATUS_FAULT" ;
VAL_ 1448 EPBR_a175_monitorFaultStatus 1 "EPB_STATUS_RETRY" 3 "EPB_STATUS_FAULT_IDLE" 0 "EPB_STATUS_NOMINAL" 2 "EPB_STATUS_FAULT" ;
VAL_ 1448 EPBR_a246_faultStatus 1 "EPB_STATUS_RETRY" 3 "EPB_STATUS_FAULT_IDLE" 0 "EPB_STATUS_NOMINAL" 2 "EPB_STATUS_FAULT" ;
VAL_ 1448 EPBR_a191_monitorFaultStatus 1 "EPB_STATUS_RETRY" 3 "EPB_STATUS_FAULT_IDLE" 0 "EPB_STATUS_NOMINAL" 2 "EPB_STATUS_FAULT" ;
VAL_ 1448 EPBR_a247_monitorFaultStatus 1 "EPB_STATUS_RETRY" 3 "EPB_STATUS_FAULT_IDLE" 0 "EPB_STATUS_NOMINAL" 2 "EPB_STATUS_FAULT" ;
VAL_ 1448 EPBR_a188_previousState 11 "ESM_PARK_PENDING" 1 "ESM_PARK" 3 "ESM_OPEN" 5 "ESM_SUMMON" 0 "ESM_INIT" 6 "ESM_WINCHMODE" 13 "ESM_SUMMON_PARK" 18 "ESM_DYNAMIC_EXTERNAL_EXIT" 19 "ESM_UNKNOWN" 12 "ESM_WINCHMODE_PENDING" 8 "ESM_DIAGNOSTIC_PARK" 16 "ESM_LATCHED_DYNAMIC_EXTERNAL" 2 "ESM_REAPPLY" 9 "ESM_DIAGNOSTIC_OPEN" 14 "ESM_DYNAMIC_EXTERNAL" 10 "ESM_DYNAMIC_PARK" 17 "ESM_SERVICE_PENDING" 15 "ESM_DYNAMIC_PENDING" 7 "ESM_SERVICE" 4 "ESM_DYNAMIC" ;
VAL_ 1448 EPBR_a177_monitorUnitStatus 14 "EPB_STATUS_SUMMON" 1 "EPB_STATUS_OPEN" 9 "EPB_STATUS_DYNAMIC_APPLYING" 21 "EPB_STATUS_COUNT" 12 "EPB_STATUS_PARK_PENDING" 13 "EPB_STATUS_WINCHMODE_PENDING" 6 "EPB_STATUS_WINCHMODE" 3 "EPB_STATUS_PARK" 0 "EPB_STATUS_UNKNOWN" 4 "EPB_STATUS_START" 18 "EPB_STATUS_RELEASING_FOR_EXTERNAL_PARK" 19 "EPB_STATUS_EXTERNAL_PARKING" 17 "EPB_STATUS_EXTERNAL_DYNAMIC" 10 "EPB_STATUS_RELEASING" 15 "EPB_STATUS_SUMMON_RELEASING" 11 "EPB_STATUS_SERVICE_RELEASING" 7 "EPB_STATUS_WINCHMODE_RELEASING" 16 "EPB_STATUS_SUMMON_PARKING" 8 "EPB_STATUS_PARKING" 2 "EPB_STATUS_DYNAMIC" 5 "EPB_STATUS_SERVICE" 20 "EPB_STATUS_DYNAMIC_PARKING" ;
VAL_ 1448 EPBR_a183_previousState 11 "ESM_PARK_PENDING" 1 "ESM_PARK" 3 "ESM_OPEN" 5 "ESM_SUMMON" 0 "ESM_INIT" 6 "ESM_WINCHMODE" 13 "ESM_SUMMON_PARK" 18 "ESM_DYNAMIC_EXTERNAL_EXIT" 19 "ESM_UNKNOWN" 12 "ESM_WINCHMODE_PENDING" 8 "ESM_DIAGNOSTIC_PARK" 16 "ESM_LATCHED_DYNAMIC_EXTERNAL" 2 "ESM_REAPPLY" 9 "ESM_DIAGNOSTIC_OPEN" 14 "ESM_DYNAMIC_EXTERNAL" 10 "ESM_DYNAMIC_PARK" 17 "ESM_SERVICE_PENDING" 15 "ESM_DYNAMIC_PENDING" 7 "ESM_SERVICE" 4 "ESM_DYNAMIC" ;
VAL_ 1448 EPBR_a176_monitorUnitStatus 14 "EPB_STATUS_SUMMON" 1 "EPB_STATUS_OPEN" 9 "EPB_STATUS_DYNAMIC_APPLYING" 21 "EPB_STATUS_COUNT" 12 "EPB_STATUS_PARK_PENDING" 13 "EPB_STATUS_WINCHMODE_PENDING" 6 "EPB_STATUS_WINCHMODE" 3 "EPB_STATUS_PARK" 0 "EPB_STATUS_UNKNOWN" 4 "EPB_STATUS_START" 18 "EPB_STATUS_RELEASING_FOR_EXTERNAL_PARK" 19 "EPB_STATUS_EXTERNAL_PARKING" 17 "EPB_STATUS_EXTERNAL_DYNAMIC" 10 "EPB_STATUS_RELEASING" 15 "EPB_STATUS_SUMMON_RELEASING" 11 "EPB_STATUS_SERVICE_RELEASING" 7 "EPB_STATUS_WINCHMODE_RELEASING" 16 "EPB_STATUS_SUMMON_PARKING" 8 "EPB_STATUS_PARKING" 2 "EPB_STATUS_DYNAMIC" 5 "EPB_STATUS_SERVICE" 20 "EPB_STATUS_DYNAMIC_PARKING" ;
VAL_ 1448 EPBR_a189_previousState 11 "ESM_PARK_PENDING" 1 "ESM_PARK" 3 "ESM_OPEN" 5 "ESM_SUMMON" 0 "ESM_INIT" 6 "ESM_WINCHMODE" 13 "ESM_SUMMON_PARK" 18 "ESM_DYNAMIC_EXTERNAL_EXIT" 19 "ESM_UNKNOWN" 12 "ESM_WINCHMODE_PENDING" 8 "ESM_DIAGNOSTIC_PARK" 16 "ESM_LATCHED_DYNAMIC_EXTERNAL" 2 "ESM_REAPPLY" 9 "ESM_DIAGNOSTIC_OPEN" 14 "ESM_DYNAMIC_EXTERNAL" 10 "ESM_DYNAMIC_PARK" 17 "ESM_SERVICE_PENDING" 15 "ESM_DYNAMIC_PENDING" 7 "ESM_SERVICE" 4 "ESM_DYNAMIC" ;
VAL_ 1448 EPBR_a184_previousState 11 "ESM_PARK_PENDING" 1 "ESM_PARK" 3 "ESM_OPEN" 5 "ESM_SUMMON" 0 "ESM_INIT" 6 "ESM_WINCHMODE" 13 "ESM_SUMMON_PARK" 18 "ESM_DYNAMIC_EXTERNAL_EXIT" 19 "ESM_UNKNOWN" 12 "ESM_WINCHMODE_PENDING" 8 "ESM_DIAGNOSTIC_PARK" 16 "ESM_LATCHED_DYNAMIC_EXTERNAL" 2 "ESM_REAPPLY" 9 "ESM_DIAGNOSTIC_OPEN" 14 "ESM_DYNAMIC_EXTERNAL" 10 "ESM_DYNAMIC_PARK" 17 "ESM_SERVICE_PENDING" 15 "ESM_DYNAMIC_PENDING" 7 "ESM_SERVICE" 4 "ESM_DYNAMIC" ;
VAL_ 1448 EPBR_a248_monitorUnitStatus 14 "EPB_STATUS_SUMMON" 1 "EPB_STATUS_OPEN" 9 "EPB_STATUS_DYNAMIC_APPLYING" 21 "EPB_STATUS_COUNT" 12 "EPB_STATUS_PARK_PENDING" 13 "EPB_STATUS_WINCHMODE_PENDING" 6 "EPB_STATUS_WINCHMODE" 3 "EPB_STATUS_PARK" 0 "EPB_STATUS_UNKNOWN" 4 "EPB_STATUS_START" 18 "EPB_STATUS_RELEASING_FOR_EXTERNAL_PARK" 19 "EPB_STATUS_EXTERNAL_PARKING" 17 "EPB_STATUS_EXTERNAL_DYNAMIC" 10 "EPB_STATUS_RELEASING" 15 "EPB_STATUS_SUMMON_RELEASING" 11 "EPB_STATUS_SERVICE_RELEASING" 7 "EPB_STATUS_WINCHMODE_RELEASING" 16 "EPB_STATUS_SUMMON_PARKING" 8 "EPB_STATUS_PARKING" 2 "EPB_STATUS_DYNAMIC" 5 "EPB_STATUS_SERVICE" 20 "EPB_STATUS_DYNAMIC_PARKING" ;
VAL_ 1448 EPBR_a175_monitorUnitStatus 14 "EPB_STATUS_SUMMON" 1 "EPB_STATUS_OPEN" 9 "EPB_STATUS_DYNAMIC_APPLYING" 21 "EPB_STATUS_COUNT" 12 "EPB_STATUS_PARK_PENDING" 13 "EPB_STATUS_WINCHMODE_PENDING" 6 "EPB_STATUS_WINCHMODE" 3 "EPB_STATUS_PARK" 0 "EPB_STATUS_UNKNOWN" 4 "EPB_STATUS_START" 18 "EPB_STATUS_RELEASING_FOR_EXTERNAL_PARK" 19 "EPB_STATUS_EXTERNAL_PARKING" 17 "EPB_STATUS_EXTERNAL_DYNAMIC" 10 "EPB_STATUS_RELEASING" 15 "EPB_STATUS_SUMMON_RELEASING" 11 "EPB_STATUS_SERVICE_RELEASING" 7 "EPB_STATUS_WINCHMODE_RELEASING" 16 "EPB_STATUS_SUMMON_PARKING" 8 "EPB_STATUS_PARKING" 2 "EPB_STATUS_DYNAMIC" 5 "EPB_STATUS_SERVICE" 20 "EPB_STATUS_DYNAMIC_PARKING" ;
VAL_ 1448 EPBR_a246_esmStateRequest 11 "ESM_PARK_PENDING" 1 "ESM_PARK" 3 "ESM_OPEN" 5 "ESM_SUMMON" 0 "ESM_INIT" 6 "ESM_WINCHMODE" 13 "ESM_SUMMON_PARK" 18 "ESM_DYNAMIC_EXTERNAL_EXIT" 19 "ESM_UNKNOWN" 12 "ESM_WINCHMODE_PENDING" 8 "ESM_DIAGNOSTIC_PARK" 16 "ESM_LATCHED_DYNAMIC_EXTERNAL" 2 "ESM_REAPPLY" 9 "ESM_DIAGNOSTIC_OPEN" 14 "ESM_DYNAMIC_EXTERNAL" 10 "ESM_DYNAMIC_PARK" 17 "ESM_SERVICE_PENDING" 15 "ESM_DYNAMIC_PENDING" 7 "ESM_SERVICE" 4 "ESM_DYNAMIC" ;
VAL_ 1448 EPBR_a249_esmStateRequest 11 "ESM_PARK_PENDING" 1 "ESM_PARK" 3 "ESM_OPEN" 5 "ESM_SUMMON" 0 "ESM_INIT" 6 "ESM_WINCHMODE" 13 "ESM_SUMMON_PARK" 18 "ESM_DYNAMIC_EXTERNAL_EXIT" 19 "ESM_UNKNOWN" 12 "ESM_WINCHMODE_PENDING" 8 "ESM_DIAGNOSTIC_PARK" 16 "ESM_LATCHED_DYNAMIC_EXTERNAL" 2 "ESM_REAPPLY" 9 "ESM_DIAGNOSTIC_OPEN" 14 "ESM_DYNAMIC_EXTERNAL" 10 "ESM_DYNAMIC_PARK" 17 "ESM_SERVICE_PENDING" 15 "ESM_DYNAMIC_PENDING" 7 "ESM_SERVICE" 4 "ESM_DYNAMIC" ;
VAL_ 1448 EPBR_a247_monitorUnitStatus 14 "EPB_STATUS_SUMMON" 1 "EPB_STATUS_OPEN" 9 "EPB_STATUS_DYNAMIC_APPLYING" 21 "EPB_STATUS_COUNT" 12 "EPB_STATUS_PARK_PENDING" 13 "EPB_STATUS_WINCHMODE_PENDING" 6 "EPB_STATUS_WINCHMODE" 3 "EPB_STATUS_PARK" 0 "EPB_STATUS_UNKNOWN" 4 "EPB_STATUS_START" 18 "EPB_STATUS_RELEASING_FOR_EXTERNAL_PARK" 19 "EPB_STATUS_EXTERNAL_PARKING" 17 "EPB_STATUS_EXTERNAL_DYNAMIC" 10 "EPB_STATUS_RELEASING" 15 "EPB_STATUS_SUMMON_RELEASING" 11 "EPB_STATUS_SERVICE_RELEASING" 7 "EPB_STATUS_WINCHMODE_RELEASING" 16 "EPB_STATUS_SUMMON_PARKING" 8 "EPB_STATUS_PARKING" 2 "EPB_STATUS_DYNAMIC" 5 "EPB_STATUS_SERVICE" 20 "EPB_STATUS_DYNAMIC_PARKING" ;
VAL_ 1448 EPBR_a191_monitorUnitStatus 14 "EPB_STATUS_SUMMON" 1 "EPB_STATUS_OPEN" 9 "EPB_STATUS_DYNAMIC_APPLYING" 21 "EPB_STATUS_COUNT" 12 "EPB_STATUS_PARK_PENDING" 13 "EPB_STATUS_WINCHMODE_PENDING" 6 "EPB_STATUS_WINCHMODE" 3 "EPB_STATUS_PARK" 0 "EPB_STATUS_UNKNOWN" 4 "EPB_STATUS_START" 18 "EPB_STATUS_RELEASING_FOR_EXTERNAL_PARK" 19 "EPB_STATUS_EXTERNAL_PARKING" 17 "EPB_STATUS_EXTERNAL_DYNAMIC" 10 "EPB_STATUS_RELEASING" 15 "EPB_STATUS_SUMMON_RELEASING" 11 "EPB_STATUS_SERVICE_RELEASING" 7 "EPB_STATUS_WINCHMODE_RELEASING" 16 "EPB_STATUS_SUMMON_PARKING" 8 "EPB_STATUS_PARKING" 2 "EPB_STATUS_DYNAMIC" 5 "EPB_STATUS_SERVICE" 20 "EPB_STATUS_DYNAMIC_PARKING" ;
VAL_ 1448 EPBR_a180_previousState 11 "ESM_PARK_PENDING" 1 "ESM_PARK" 3 "ESM_OPEN" 5 "ESM_SUMMON" 0 "ESM_INIT" 6 "ESM_WINCHMODE" 13 "ESM_SUMMON_PARK" 18 "ESM_DYNAMIC_EXTERNAL_EXIT" 19 "ESM_UNKNOWN" 12 "ESM_WINCHMODE_PENDING" 8 "ESM_DIAGNOSTIC_PARK" 16 "ESM_LATCHED_DYNAMIC_EXTERNAL" 2 "ESM_REAPPLY" 9 "ESM_DIAGNOSTIC_OPEN" 14 "ESM_DYNAMIC_EXTERNAL" 10 "ESM_DYNAMIC_PARK" 17 "ESM_SERVICE_PENDING" 15 "ESM_DYNAMIC_PENDING" 7 "ESM_SERVICE" 4 "ESM_DYNAMIC" ;
VAL_ 1448 EPBR_a173_csmState 8 "CSM_WAIT_FOR_ENDSTOP" 9 "CSM_RELEASE_COMPLETE" 12 "CSM_FAULT" 5 "CSM_APPLY_COMPLETE" 7 "CSM_RELEASE_NOLOAD" 14 "CSM_HOLD_CLAMP" 4 "CSM_WAIT_FOR_CLAMP" 6 "CSM_RELEASE_INRUSH" 13 "CSM_STATIONARY_FAULT" 2 "CSM_APPLY_INRUSH" 10 "CSM_CALIBRATE" 1 "CSM_STANDBY" 0 "CSM_INIT" 11 "CSM_HALT" 3 "CSM_APPLY_NOLOAD" ;
VAL_ 1448 EPBR_a174_monitorUnitStatus 14 "EPB_STATUS_SUMMON" 1 "EPB_STATUS_OPEN" 9 "EPB_STATUS_DYNAMIC_APPLYING" 21 "EPB_STATUS_COUNT" 12 "EPB_STATUS_PARK_PENDING" 13 "EPB_STATUS_WINCHMODE_PENDING" 6 "EPB_STATUS_WINCHMODE" 3 "EPB_STATUS_PARK" 0 "EPB_STATUS_UNKNOWN" 4 "EPB_STATUS_START" 18 "EPB_STATUS_RELEASING_FOR_EXTERNAL_PARK" 19 "EPB_STATUS_EXTERNAL_PARKING" 17 "EPB_STATUS_EXTERNAL_DYNAMIC" 10 "EPB_STATUS_RELEASING" 15 "EPB_STATUS_SUMMON_RELEASING" 11 "EPB_STATUS_SERVICE_RELEASING" 7 "EPB_STATUS_WINCHMODE_RELEASING" 16 "EPB_STATUS_SUMMON_PARKING" 8 "EPB_STATUS_PARKING" 2 "EPB_STATUS_DYNAMIC" 5 "EPB_STATUS_SERVICE" 20 "EPB_STATUS_DYNAMIC_PARKING" ;
VAL_ 1448 EPBR_a179_monitorUnitStatus 14 "EPB_STATUS_SUMMON" 1 "EPB_STATUS_OPEN" 9 "EPB_STATUS_DYNAMIC_APPLYING" 21 "EPB_STATUS_COUNT" 12 "EPB_STATUS_PARK_PENDING" 13 "EPB_STATUS_WINCHMODE_PENDING" 6 "EPB_STATUS_WINCHMODE" 3 "EPB_STATUS_PARK" 0 "EPB_STATUS_UNKNOWN" 4 "EPB_STATUS_START" 18 "EPB_STATUS_RELEASING_FOR_EXTERNAL_PARK" 19 "EPB_STATUS_EXTERNAL_PARKING" 17 "EPB_STATUS_EXTERNAL_DYNAMIC" 10 "EPB_STATUS_RELEASING" 15 "EPB_STATUS_SUMMON_RELEASING" 11 "EPB_STATUS_SERVICE_RELEASING" 7 "EPB_STATUS_WINCHMODE_RELEASING" 16 "EPB_STATUS_SUMMON_PARKING" 8 "EPB_STATUS_PARKING" 2 "EPB_STATUS_DYNAMIC" 5 "EPB_STATUS_SERVICE" 20 "EPB_STATUS_DYNAMIC_PARKING" ;
VAL_ 1448 EPBR_a186_previousState 11 "ESM_PARK_PENDING" 1 "ESM_PARK" 3 "ESM_OPEN" 5 "ESM_SUMMON" 0 "ESM_INIT" 6 "ESM_WINCHMODE" 13 "ESM_SUMMON_PARK" 18 "ESM_DYNAMIC_EXTERNAL_EXIT" 19 "ESM_UNKNOWN" 12 "ESM_WINCHMODE_PENDING" 8 "ESM_DIAGNOSTIC_PARK" 16 "ESM_LATCHED_DYNAMIC_EXTERNAL" 2 "ESM_REAPPLY" 9 "ESM_DIAGNOSTIC_OPEN" 14 "ESM_DYNAMIC_EXTERNAL" 10 "ESM_DYNAMIC_PARK" 17 "ESM_SERVICE_PENDING" 15 "ESM_DYNAMIC_PENDING" 7 "ESM_SERVICE" 4 "ESM_DYNAMIC" ;
VAL_ 1448 EPBR_a190_monitorUnitStatus 14 "EPB_STATUS_SUMMON" 1 "EPB_STATUS_OPEN" 9 "EPB_STATUS_DYNAMIC_APPLYING" 21 "EPB_STATUS_COUNT" 12 "EPB_STATUS_PARK_PENDING" 13 "EPB_STATUS_WINCHMODE_PENDING" 6 "EPB_STATUS_WINCHMODE" 3 "EPB_STATUS_PARK" 0 "EPB_STATUS_UNKNOWN" 4 "EPB_STATUS_START" 18 "EPB_STATUS_RELEASING_FOR_EXTERNAL_PARK" 19 "EPB_STATUS_EXTERNAL_PARKING" 17 "EPB_STATUS_EXTERNAL_DYNAMIC" 10 "EPB_STATUS_RELEASING" 15 "EPB_STATUS_SUMMON_RELEASING" 11 "EPB_STATUS_SERVICE_RELEASING" 7 "EPB_STATUS_WINCHMODE_RELEASING" 16 "EPB_STATUS_SUMMON_PARKING" 8 "EPB_STATUS_PARKING" 2 "EPB_STATUS_DYNAMIC" 5 "EPB_STATUS_SERVICE" 20 "EPB_STATUS_DYNAMIC_PARKING" ;
VAL_ 1448 EPBR_a187_previousState 11 "ESM_PARK_PENDING" 1 "ESM_PARK" 3 "ESM_OPEN" 5 "ESM_SUMMON" 0 "ESM_INIT" 6 "ESM_WINCHMODE" 13 "ESM_SUMMON_PARK" 18 "ESM_DYNAMIC_EXTERNAL_EXIT" 19 "ESM_UNKNOWN" 12 "ESM_WINCHMODE_PENDING" 8 "ESM_DIAGNOSTIC_PARK" 16 "ESM_LATCHED_DYNAMIC_EXTERNAL" 2 "ESM_REAPPLY" 9 "ESM_DIAGNOSTIC_OPEN" 14 "ESM_DYNAMIC_EXTERNAL" 10 "ESM_DYNAMIC_PARK" 17 "ESM_SERVICE_PENDING" 15 "ESM_DYNAMIC_PENDING" 7 "ESM_SERVICE" 4 "ESM_DYNAMIC" ;
VAL_ 1448 EPBR_a177_faultStatus 1 "EPB_STATUS_RETRY" 3 "EPB_STATUS_FAULT_IDLE" 0 "EPB_STATUS_NOMINAL" 2 "EPB_STATUS_FAULT" ;
VAL_ 1448 EPBR_a176_faultStatus 1 "EPB_STATUS_RETRY" 3 "EPB_STATUS_FAULT_IDLE" 0 "EPB_STATUS_NOMINAL" 2 "EPB_STATUS_FAULT" ;
VAL_ 1448 EPBR_a248_faultStatus 1 "EPB_STATUS_RETRY" 3 "EPB_STATUS_FAULT_IDLE" 0 "EPB_STATUS_NOMINAL" 2 "EPB_STATUS_FAULT" ;
VAL_ 1448 EPBR_a175_faultStatus 1 "EPB_STATUS_RETRY" 3 "EPB_STATUS_FAULT_IDLE" 0 "EPB_STATUS_NOMINAL" 2 "EPB_STATUS_FAULT" ;
VAL_ 1448 EPBR_a191_faultStatus 1 "EPB_STATUS_RETRY" 3 "EPB_STATUS_FAULT_IDLE" 0 "EPB_STATUS_NOMINAL" 2 "EPB_STATUS_FAULT" ;
VAL_ 1448 EPBR_a247_faultStatus 1 "EPB_STATUS_RETRY" 3 "EPB_STATUS_FAULT_IDLE" 0 "EPB_STATUS_NOMINAL" 2 "EPB_STATUS_FAULT" ;
VAL_ 1448 EPBR_a174_faultStatus 1 "EPB_STATUS_RETRY" 3 "EPB_STATUS_FAULT_IDLE" 0 "EPB_STATUS_NOMINAL" 2 "EPB_STATUS_FAULT" ;
VAL_ 1448 EPBR_a179_faultStatus 1 "EPB_STATUS_RETRY" 3 "EPB_STATUS_FAULT_IDLE" 0 "EPB_STATUS_NOMINAL" 2 "EPB_STATUS_FAULT" ;
VAL_ 1448 EPBR_a190_faultStatus 1 "EPB_STATUS_RETRY" 3 "EPB_STATUS_FAULT_IDLE" 0 "EPB_STATUS_NOMINAL" 2 "EPB_STATUS_FAULT" ;
VAL_ 1448 EPBR_a241_highCurrent 1 "LV_ON" 2 "LV_GOING_DOWN" 3 "LV_FAULT" 0 "LV_OFF" ;
VAL_ 1448 EPBR_a242_highCurrent 1 "LV_ON" 2 "LV_GOING_DOWN" 3 "LV_FAULT" 0 "LV_OFF" ;
VAL_ 1448 EPBR_a180_esmOpTrigger 20 "EPB_TRIGGER_TIMEOUT" 2 "EPB_TRIGGER_PBUTTON_PRESSED_FAST" 19 "EPB_TRIGGER_SPEED_FAST" 3 "EPB_TRIGGER_PBUTTON_PRESSED_UNKNOWN" 27 "EPB_TRIGGER_EPBM_DISQUALIFIED" 10 "EPB_TRIGGER_WINCHMODE_UNAVAILABLE" 28 "EPB_TRIGGER_ACCELERATION" 12 "EPB_TRIGGER_DIAG_CLOSE" 24 "EPB_TRIGGER_FAULT" 25 "EPB_TRIGGER_SUMMON_FAULT" 30 "EPB_TRIGGER_DRIVER_IS_LEAVING" 18 "EPB_TRIGGER_SPEED_OKAYTOPARK" 1 "EPB_TRIGGER_PBUTTON_PRESSED_OKTOPARK" 4 "EPB_TRIGGER_PBUTTON_RELEASED" 14 "EPB_TRIGGER_DIAG_EXIT" 21 "EPB_TRIGGER_SAVESTATE_ON_BOOT" 6 "EPB_TRIGGER_DI_UNPARK" 23 "EPB_TRIGGER_SUMMON_COMPLETE" 22 "EPB_TRIGGER_REAPPLY" 26 "EPB_TRIGGER_DISQUALIFIED" 16 "EPB_TRIGGER_USER_CANCEL" 13 "EPB_TRIGGER_DIAG_OPEN" 11 "EPB_TRIGGER_SERVICE" 5 "EPB_TRIGGER_ACTIVE_PARK_REQUEST" 15 "EPB_TRIGGER_USER_CONFIRMED" 8 "EPB_TRIGGER_WINCHMODE_EXIT" 9 "EPB_TRIGGER_WINCHMODE_ENTER" 17 "EPB_TRIGGER_SPEED_STOPPED" 0 "EPB_TRIGGER_PBUTTON_PRESSED_STOPPED" 7 "EPB_TRIGGER_TOUCHSCREEN" 29 "EPB_TRIGGER_SYSTEM_APPLY" ;
VAL_ 1448 EPBR_a176_esmStateRequest 11 "ESM_PARK_PENDING" 1 "ESM_PARK" 3 "ESM_OPEN" 5 "ESM_SUMMON" 0 "ESM_INIT" 6 "ESM_WINCHMODE" 13 "ESM_SUMMON_PARK" 18 "ESM_DYNAMIC_EXTERNAL_EXIT" 19 "ESM_UNKNOWN" 12 "ESM_WINCHMODE_PENDING" 8 "ESM_DIAGNOSTIC_PARK" 16 "ESM_LATCHED_DYNAMIC_EXTERNAL" 2 "ESM_REAPPLY" 9 "ESM_DIAGNOSTIC_OPEN" 14 "ESM_DYNAMIC_EXTERNAL" 10 "ESM_DYNAMIC_PARK" 17 "ESM_SERVICE_PENDING" 15 "ESM_DYNAMIC_PENDING" 7 "ESM_SERVICE" 4 "ESM_DYNAMIC" ;
VAL_ 1448 EPBR_a187_esmOpTrigger 20 "EPB_TRIGGER_TIMEOUT" 2 "EPB_TRIGGER_PBUTTON_PRESSED_FAST" 19 "EPB_TRIGGER_SPEED_FAST" 3 "EPB_TRIGGER_PBUTTON_PRESSED_UNKNOWN" 27 "EPB_TRIGGER_EPBM_DISQUALIFIED" 10 "EPB_TRIGGER_WINCHMODE_UNAVAILABLE" 28 "EPB_TRIGGER_ACCELERATION" 12 "EPB_TRIGGER_DIAG_CLOSE" 24 "EPB_TRIGGER_FAULT" 25 "EPB_TRIGGER_SUMMON_FAULT" 30 "EPB_TRIGGER_DRIVER_IS_LEAVING" 18 "EPB_TRIGGER_SPEED_OKAYTOPARK" 1 "EPB_TRIGGER_PBUTTON_PRESSED_OKTOPARK" 4 "EPB_TRIGGER_PBUTTON_RELEASED" 14 "EPB_TRIGGER_DIAG_EXIT" 21 "EPB_TRIGGER_SAVESTATE_ON_BOOT" 6 "EPB_TRIGGER_DI_UNPARK" 23 "EPB_TRIGGER_SUMMON_COMPLETE" 22 "EPB_TRIGGER_REAPPLY" 26 "EPB_TRIGGER_DISQUALIFIED" 16 "EPB_TRIGGER_USER_CANCEL" 13 "EPB_TRIGGER_DIAG_OPEN" 11 "EPB_TRIGGER_SERVICE" 5 "EPB_TRIGGER_ACTIVE_PARK_REQUEST" 15 "EPB_TRIGGER_USER_CONFIRMED" 8 "EPB_TRIGGER_WINCHMODE_EXIT" 9 "EPB_TRIGGER_WINCHMODE_ENTER" 17 "EPB_TRIGGER_SPEED_STOPPED" 0 "EPB_TRIGGER_PBUTTON_PRESSED_STOPPED" 7 "EPB_TRIGGER_TOUCHSCREEN" 29 "EPB_TRIGGER_SYSTEM_APPLY" ;
VAL_ 1448 EPBR_a179_esmStateRequest 11 "ESM_PARK_PENDING" 1 "ESM_PARK" 3 "ESM_OPEN" 5 "ESM_SUMMON" 0 "ESM_INIT" 6 "ESM_WINCHMODE" 13 "ESM_SUMMON_PARK" 18 "ESM_DYNAMIC_EXTERNAL_EXIT" 19 "ESM_UNKNOWN" 12 "ESM_WINCHMODE_PENDING" 8 "ESM_DIAGNOSTIC_PARK" 16 "ESM_LATCHED_DYNAMIC_EXTERNAL" 2 "ESM_REAPPLY" 9 "ESM_DIAGNOSTIC_OPEN" 14 "ESM_DYNAMIC_EXTERNAL" 10 "ESM_DYNAMIC_PARK" 17 "ESM_SERVICE_PENDING" 15 "ESM_DYNAMIC_PENDING" 7 "ESM_SERVICE" 4 "ESM_DYNAMIC" ;
VAL_ 1448 EPBR_a249_nextState 11 "ESM_PARK_PENDING" 1 "ESM_PARK" 3 "ESM_OPEN" 5 "ESM_SUMMON" 0 "ESM_INIT" 6 "ESM_WINCHMODE" 13 "ESM_SUMMON_PARK" 18 "ESM_DYNAMIC_EXTERNAL_EXIT" 19 "ESM_UNKNOWN" 12 "ESM_WINCHMODE_PENDING" 8 "ESM_DIAGNOSTIC_PARK" 16 "ESM_LATCHED_DYNAMIC_EXTERNAL" 2 "ESM_REAPPLY" 9 "ESM_DIAGNOSTIC_OPEN" 14 "ESM_DYNAMIC_EXTERNAL" 10 "ESM_DYNAMIC_PARK" 17 "ESM_SERVICE_PENDING" 15 "ESM_DYNAMIC_PENDING" 7 "ESM_SERVICE" 4 "ESM_DYNAMIC" ;
VAL_ 1448 EPBR_a300_subUsageId 11 "ESM_PARK_PENDING" 1 "ESM_PARK" 3 "ESM_OPEN" 5 "ESM_SUMMON" 0 "ESM_INIT" 6 "ESM_WINCHMODE" 13 "ESM_SUMMON_PARK" 18 "ESM_DYNAMIC_EXTERNAL_EXIT" 19 "ESM_UNKNOWN" 12 "ESM_WINCHMODE_PENDING" 8 "ESM_DIAGNOSTIC_PARK" 16 "ESM_LATCHED_DYNAMIC_EXTERNAL" 2 "ESM_REAPPLY" 9 "ESM_DIAGNOSTIC_OPEN" 14 "ESM_DYNAMIC_EXTERNAL" 10 "ESM_DYNAMIC_PARK" 17 "ESM_SERVICE_PENDING" 15 "ESM_DYNAMIC_PENDING" 7 "ESM_SERVICE" 4 "ESM_DYNAMIC" ;
VAL_ 1448 EPBR_a242_vehiclePowerState 3 "VEHICLE_POWER_STATE_DRIVE" 1 "VEHICLE_POWER_STATE_CONDITIONING" 2 "VEHICLE_POWER_STATE_ACCESSORY" 0 "VEHICLE_POWER_STATE_OFF" ;
VAL_ 1448 EPBR_a177_esmStateRequest 11 "ESM_PARK_PENDING" 1 "ESM_PARK" 3 "ESM_OPEN" 5 "ESM_SUMMON" 0 "ESM_INIT" 6 "ESM_WINCHMODE" 13 "ESM_SUMMON_PARK" 18 "ESM_DYNAMIC_EXTERNAL_EXIT" 19 "ESM_UNKNOWN" 12 "ESM_WINCHMODE_PENDING" 8 "ESM_DIAGNOSTIC_PARK" 16 "ESM_LATCHED_DYNAMIC_EXTERNAL" 2 "ESM_REAPPLY" 9 "ESM_DIAGNOSTIC_OPEN" 14 "ESM_DYNAMIC_EXTERNAL" 10 "ESM_DYNAMIC_PARK" 17 "ESM_SERVICE_PENDING" 15 "ESM_DYNAMIC_PENDING" 7 "ESM_SERVICE" 4 "ESM_DYNAMIC" ;
VAL_ 1448 EPBR_a189_esmOpTrigger 20 "EPB_TRIGGER_TIMEOUT" 2 "EPB_TRIGGER_PBUTTON_PRESSED_FAST" 19 "EPB_TRIGGER_SPEED_FAST" 3 "EPB_TRIGGER_PBUTTON_PRESSED_UNKNOWN" 27 "EPB_TRIGGER_EPBM_DISQUALIFIED" 10 "EPB_TRIGGER_WINCHMODE_UNAVAILABLE" 28 "EPB_TRIGGER_ACCELERATION" 12 "EPB_TRIGGER_DIAG_CLOSE" 24 "EPB_TRIGGER_FAULT" 25 "EPB_TRIGGER_SUMMON_FAULT" 30 "EPB_TRIGGER_DRIVER_IS_LEAVING" 18 "EPB_TRIGGER_SPEED_OKAYTOPARK" 1 "EPB_TRIGGER_PBUTTON_PRESSED_OKTOPARK" 4 "EPB_TRIGGER_PBUTTON_RELEASED" 14 "EPB_TRIGGER_DIAG_EXIT" 21 "EPB_TRIGGER_SAVESTATE_ON_BOOT" 6 "EPB_TRIGGER_DI_UNPARK" 23 "EPB_TRIGGER_SUMMON_COMPLETE" 22 "EPB_TRIGGER_REAPPLY" 26 "EPB_TRIGGER_DISQUALIFIED" 16 "EPB_TRIGGER_USER_CANCEL" 13 "EPB_TRIGGER_DIAG_OPEN" 11 "EPB_TRIGGER_SERVICE" 5 "EPB_TRIGGER_ACTIVE_PARK_REQUEST" 15 "EPB_TRIGGER_USER_CONFIRMED" 8 "EPB_TRIGGER_WINCHMODE_EXIT" 9 "EPB_TRIGGER_WINCHMODE_ENTER" 17 "EPB_TRIGGER_SPEED_STOPPED" 0 "EPB_TRIGGER_PBUTTON_PRESSED_STOPPED" 7 "EPB_TRIGGER_TOUCHSCREEN" 29 "EPB_TRIGGER_SYSTEM_APPLY" ;
VAL_ 1448 EPBR_a183_esmOpTrigger 20 "EPB_TRIGGER_TIMEOUT" 2 "EPB_TRIGGER_PBUTTON_PRESSED_FAST" 19 "EPB_TRIGGER_SPEED_FAST" 3 "EPB_TRIGGER_PBUTTON_PRESSED_UNKNOWN" 27 "EPB_TRIGGER_EPBM_DISQUALIFIED" 10 "EPB_TRIGGER_WINCHMODE_UNAVAILABLE" 28 "EPB_TRIGGER_ACCELERATION" 12 "EPB_TRIGGER_DIAG_CLOSE" 24 "EPB_TRIGGER_FAULT" 25 "EPB_TRIGGER_SUMMON_FAULT" 30 "EPB_TRIGGER_DRIVER_IS_LEAVING" 18 "EPB_TRIGGER_SPEED_OKAYTOPARK" 1 "EPB_TRIGGER_PBUTTON_PRESSED_OKTOPARK" 4 "EPB_TRIGGER_PBUTTON_RELEASED" 14 "EPB_TRIGGER_DIAG_EXIT" 21 "EPB_TRIGGER_SAVESTATE_ON_BOOT" 6 "EPB_TRIGGER_DI_UNPARK" 23 "EPB_TRIGGER_SUMMON_COMPLETE" 22 "EPB_TRIGGER_REAPPLY" 26 "EPB_TRIGGER_DISQUALIFIED" 16 "EPB_TRIGGER_USER_CANCEL" 13 "EPB_TRIGGER_DIAG_OPEN" 11 "EPB_TRIGGER_SERVICE" 5 "EPB_TRIGGER_ACTIVE_PARK_REQUEST" 15 "EPB_TRIGGER_USER_CONFIRMED" 8 "EPB_TRIGGER_WINCHMODE_EXIT" 9 "EPB_TRIGGER_WINCHMODE_ENTER" 17 "EPB_TRIGGER_SPEED_STOPPED" 0 "EPB_TRIGGER_PBUTTON_PRESSED_STOPPED" 7 "EPB_TRIGGER_TOUCHSCREEN" 29 "EPB_TRIGGER_SYSTEM_APPLY" ;
VAL_ 1448 EPBR_a186_esmOpTrigger 20 "EPB_TRIGGER_TIMEOUT" 2 "EPB_TRIGGER_PBUTTON_PRESSED_FAST" 19 "EPB_TRIGGER_SPEED_FAST" 3 "EPB_TRIGGER_PBUTTON_PRESSED_UNKNOWN" 27 "EPB_TRIGGER_EPBM_DISQUALIFIED" 10 "EPB_TRIGGER_WINCHMODE_UNAVAILABLE" 28 "EPB_TRIGGER_ACCELERATION" 12 "EPB_TRIGGER_DIAG_CLOSE" 24 "EPB_TRIGGER_FAULT" 25 "EPB_TRIGGER_SUMMON_FAULT" 30 "EPB_TRIGGER_DRIVER_IS_LEAVING" 18 "EPB_TRIGGER_SPEED_OKAYTOPARK" 1 "EPB_TRIGGER_PBUTTON_PRESSED_OKTOPARK" 4 "EPB_TRIGGER_PBUTTON_RELEASED" 14 "EPB_TRIGGER_DIAG_EXIT" 21 "EPB_TRIGGER_SAVESTATE_ON_BOOT" 6 "EPB_TRIGGER_DI_UNPARK" 23 "EPB_TRIGGER_SUMMON_COMPLETE" 22 "EPB_TRIGGER_REAPPLY" 26 "EPB_TRIGGER_DISQUALIFIED" 16 "EPB_TRIGGER_USER_CANCEL" 13 "EPB_TRIGGER_DIAG_OPEN" 11 "EPB_TRIGGER_SERVICE" 5 "EPB_TRIGGER_ACTIVE_PARK_REQUEST" 15 "EPB_TRIGGER_USER_CONFIRMED" 8 "EPB_TRIGGER_WINCHMODE_EXIT" 9 "EPB_TRIGGER_WINCHMODE_ENTER" 17 "EPB_TRIGGER_SPEED_STOPPED" 0 "EPB_TRIGGER_PBUTTON_PRESSED_STOPPED" 7 "EPB_TRIGGER_TOUCHSCREEN" 29 "EPB_TRIGGER_SYSTEM_APPLY" ;
VAL_ 1448 EPBR_a248_esmStateRequest 11 "ESM_PARK_PENDING" 1 "ESM_PARK" 3 "ESM_OPEN" 5 "ESM_SUMMON" 0 "ESM_INIT" 6 "ESM_WINCHMODE" 13 "ESM_SUMMON_PARK" 18 "ESM_DYNAMIC_EXTERNAL_EXIT" 19 "ESM_UNKNOWN" 12 "ESM_WINCHMODE_PENDING" 8 "ESM_DIAGNOSTIC_PARK" 16 "ESM_LATCHED_DYNAMIC_EXTERNAL" 2 "ESM_REAPPLY" 9 "ESM_DIAGNOSTIC_OPEN" 14 "ESM_DYNAMIC_EXTERNAL" 10 "ESM_DYNAMIC_PARK" 17 "ESM_SERVICE_PENDING" 15 "ESM_DYNAMIC_PENDING" 7 "ESM_SERVICE" 4 "ESM_DYNAMIC" ;
VAL_ 1448 EPBR_a141_toState 11 "ESM_PARK_PENDING" 1 "ESM_PARK" 3 "ESM_OPEN" 5 "ESM_SUMMON" 0 "ESM_INIT" 6 "ESM_WINCHMODE" 13 "ESM_SUMMON_PARK" 18 "ESM_DYNAMIC_EXTERNAL_EXIT" 19 "ESM_UNKNOWN" 12 "ESM_WINCHMODE_PENDING" 8 "ESM_DIAGNOSTIC_PARK" 16 "ESM_LATCHED_DYNAMIC_EXTERNAL" 2 "ESM_REAPPLY" 9 "ESM_DIAGNOSTIC_OPEN" 14 "ESM_DYNAMIC_EXTERNAL" 10 "ESM_DYNAMIC_PARK" 17 "ESM_SERVICE_PENDING" 15 "ESM_DYNAMIC_PENDING" 7 "ESM_SERVICE" 4 "ESM_DYNAMIC" ;
VAL_ 1448 EPBR_a190_esmStateRequest 11 "ESM_PARK_PENDING" 1 "ESM_PARK" 3 "ESM_OPEN" 5 "ESM_SUMMON" 0 "ESM_INIT" 6 "ESM_WINCHMODE" 13 "ESM_SUMMON_PARK" 18 "ESM_DYNAMIC_EXTERNAL_EXIT" 19 "ESM_UNKNOWN" 12 "ESM_WINCHMODE_PENDING" 8 "ESM_DIAGNOSTIC_PARK" 16 "ESM_LATCHED_DYNAMIC_EXTERNAL" 2 "ESM_REAPPLY" 9 "ESM_DIAGNOSTIC_OPEN" 14 "ESM_DYNAMIC_EXTERNAL" 10 "ESM_DYNAMIC_PARK" 17 "ESM_SERVICE_PENDING" 15 "ESM_DYNAMIC_PENDING" 7 "ESM_SERVICE" 4 "ESM_DYNAMIC" ;
VAL_ 1448 EPBR_a188_esmOpTrigger 20 "EPB_TRIGGER_TIMEOUT" 2 "EPB_TRIGGER_PBUTTON_PRESSED_FAST" 19 "EPB_TRIGGER_SPEED_FAST" 3 "EPB_TRIGGER_PBUTTON_PRESSED_UNKNOWN" 27 "EPB_TRIGGER_EPBM_DISQUALIFIED" 10 "EPB_TRIGGER_WINCHMODE_UNAVAILABLE" 28 "EPB_TRIGGER_ACCELERATION" 12 "EPB_TRIGGER_DIAG_CLOSE" 24 "EPB_TRIGGER_FAULT" 25 "EPB_TRIGGER_SUMMON_FAULT" 30 "EPB_TRIGGER_DRIVER_IS_LEAVING" 18 "EPB_TRIGGER_SPEED_OKAYTOPARK" 1 "EPB_TRIGGER_PBUTTON_PRESSED_OKTOPARK" 4 "EPB_TRIGGER_PBUTTON_RELEASED" 14 "EPB_TRIGGER_DIAG_EXIT" 21 "EPB_TRIGGER_SAVESTATE_ON_BOOT" 6 "EPB_TRIGGER_DI_UNPARK" 23 "EPB_TRIGGER_SUMMON_COMPLETE" 22 "EPB_TRIGGER_REAPPLY" 26 "EPB_TRIGGER_DISQUALIFIED" 16 "EPB_TRIGGER_USER_CANCEL" 13 "EPB_TRIGGER_DIAG_OPEN" 11 "EPB_TRIGGER_SERVICE" 5 "EPB_TRIGGER_ACTIVE_PARK_REQUEST" 15 "EPB_TRIGGER_USER_CONFIRMED" 8 "EPB_TRIGGER_WINCHMODE_EXIT" 9 "EPB_TRIGGER_WINCHMODE_ENTER" 17 "EPB_TRIGGER_SPEED_STOPPED" 0 "EPB_TRIGGER_PBUTTON_PRESSED_STOPPED" 7 "EPB_TRIGGER_TOUCHSCREEN" 29 "EPB_TRIGGER_SYSTEM_APPLY" ;
VAL_ 1448 EPBR_a241_vehiclePowerState 3 "VEHICLE_POWER_STATE_DRIVE" 1 "VEHICLE_POWER_STATE_CONDITIONING" 2 "VEHICLE_POWER_STATE_ACCESSORY" 0 "VEHICLE_POWER_STATE_OFF" ;
VAL_ 1448 EPBR_a174_esmStateRequest 11 "ESM_PARK_PENDING" 1 "ESM_PARK" 3 "ESM_OPEN" 5 "ESM_SUMMON" 0 "ESM_INIT" 6 "ESM_WINCHMODE" 13 "ESM_SUMMON_PARK" 18 "ESM_DYNAMIC_EXTERNAL_EXIT" 19 "ESM_UNKNOWN" 12 "ESM_WINCHMODE_PENDING" 8 "ESM_DIAGNOSTIC_PARK" 16 "ESM_LATCHED_DYNAMIC_EXTERNAL" 2 "ESM_REAPPLY" 9 "ESM_DIAGNOSTIC_OPEN" 14 "ESM_DYNAMIC_EXTERNAL" 10 "ESM_DYNAMIC_PARK" 17 "ESM_SERVICE_PENDING" 15 "ESM_DYNAMIC_PENDING" 7 "ESM_SERVICE" 4 "ESM_DYNAMIC" ;
VAL_ 1448 EPBR_a191_esmStateRequest 11 "ESM_PARK_PENDING" 1 "ESM_PARK" 3 "ESM_OPEN" 5 "ESM_SUMMON" 0 "ESM_INIT" 6 "ESM_WINCHMODE" 13 "ESM_SUMMON_PARK" 18 "ESM_DYNAMIC_EXTERNAL_EXIT" 19 "ESM_UNKNOWN" 12 "ESM_WINCHMODE_PENDING" 8 "ESM_DIAGNOSTIC_PARK" 16 "ESM_LATCHED_DYNAMIC_EXTERNAL" 2 "ESM_REAPPLY" 9 "ESM_DIAGNOSTIC_OPEN" 14 "ESM_DYNAMIC_EXTERNAL" 10 "ESM_DYNAMIC_PARK" 17 "ESM_SERVICE_PENDING" 15 "ESM_DYNAMIC_PENDING" 7 "ESM_SERVICE" 4 "ESM_DYNAMIC" ;
VAL_ 1448 EPBR_a247_esmStateRequest 11 "ESM_PARK_PENDING" 1 "ESM_PARK" 3 "ESM_OPEN" 5 "ESM_SUMMON" 0 "ESM_INIT" 6 "ESM_WINCHMODE" 13 "ESM_SUMMON_PARK" 18 "ESM_DYNAMIC_EXTERNAL_EXIT" 19 "ESM_UNKNOWN" 12 "ESM_WINCHMODE_PENDING" 8 "ESM_DIAGNOSTIC_PARK" 16 "ESM_LATCHED_DYNAMIC_EXTERNAL" 2 "ESM_REAPPLY" 9 "ESM_DIAGNOSTIC_OPEN" 14 "ESM_DYNAMIC_EXTERNAL" 10 "ESM_DYNAMIC_PARK" 17 "ESM_SERVICE_PENDING" 15 "ESM_DYNAMIC_PENDING" 7 "ESM_SERVICE" 4 "ESM_DYNAMIC" ;
VAL_ 1448 EPBR_a184_esmOpTrigger 20 "EPB_TRIGGER_TIMEOUT" 2 "EPB_TRIGGER_PBUTTON_PRESSED_FAST" 19 "EPB_TRIGGER_SPEED_FAST" 3 "EPB_TRIGGER_PBUTTON_PRESSED_UNKNOWN" 27 "EPB_TRIGGER_EPBM_DISQUALIFIED" 10 "EPB_TRIGGER_WINCHMODE_UNAVAILABLE" 28 "EPB_TRIGGER_ACCELERATION" 12 "EPB_TRIGGER_DIAG_CLOSE" 24 "EPB_TRIGGER_FAULT" 25 "EPB_TRIGGER_SUMMON_FAULT" 30 "EPB_TRIGGER_DRIVER_IS_LEAVING" 18 "EPB_TRIGGER_SPEED_OKAYTOPARK" 1 "EPB_TRIGGER_PBUTTON_PRESSED_OKTOPARK" 4 "EPB_TRIGGER_PBUTTON_RELEASED" 14 "EPB_TRIGGER_DIAG_EXIT" 21 "EPB_TRIGGER_SAVESTATE_ON_BOOT" 6 "EPB_TRIGGER_DI_UNPARK" 23 "EPB_TRIGGER_SUMMON_COMPLETE" 22 "EPB_TRIGGER_REAPPLY" 26 "EPB_TRIGGER_DISQUALIFIED" 16 "EPB_TRIGGER_USER_CANCEL" 13 "EPB_TRIGGER_DIAG_OPEN" 11 "EPB_TRIGGER_SERVICE" 5 "EPB_TRIGGER_ACTIVE_PARK_REQUEST" 15 "EPB_TRIGGER_USER_CONFIRMED" 8 "EPB_TRIGGER_WINCHMODE_EXIT" 9 "EPB_TRIGGER_WINCHMODE_ENTER" 17 "EPB_TRIGGER_SPEED_STOPPED" 0 "EPB_TRIGGER_PBUTTON_PRESSED_STOPPED" 7 "EPB_TRIGGER_TOUCHSCREEN" 29 "EPB_TRIGGER_SYSTEM_APPLY" ;
VAL_ 1448 EPBR_a175_esmStateRequest 11 "ESM_PARK_PENDING" 1 "ESM_PARK" 3 "ESM_OPEN" 5 "ESM_SUMMON" 0 "ESM_INIT" 6 "ESM_WINCHMODE" 13 "ESM_SUMMON_PARK" 18 "ESM_DYNAMIC_EXTERNAL_EXIT" 19 "ESM_UNKNOWN" 12 "ESM_WINCHMODE_PENDING" 8 "ESM_DIAGNOSTIC_PARK" 16 "ESM_LATCHED_DYNAMIC_EXTERNAL" 2 "ESM_REAPPLY" 9 "ESM_DIAGNOSTIC_OPEN" 14 "ESM_DYNAMIC_EXTERNAL" 10 "ESM_DYNAMIC_PARK" 17 "ESM_SERVICE_PENDING" 15 "ESM_DYNAMIC_PENDING" 7 "ESM_SERVICE" 4 "ESM_DYNAMIC" ;
VAL_ 1448 EPBR_a173_esmStateRequest 11 "ESM_PARK_PENDING" 1 "ESM_PARK" 3 "ESM_OPEN" 5 "ESM_SUMMON" 0 "ESM_INIT" 6 "ESM_WINCHMODE" 13 "ESM_SUMMON_PARK" 18 "ESM_DYNAMIC_EXTERNAL_EXIT" 19 "ESM_UNKNOWN" 12 "ESM_WINCHMODE_PENDING" 8 "ESM_DIAGNOSTIC_PARK" 16 "ESM_LATCHED_DYNAMIC_EXTERNAL" 2 "ESM_REAPPLY" 9 "ESM_DIAGNOSTIC_OPEN" 14 "ESM_DYNAMIC_EXTERNAL" 10 "ESM_DYNAMIC_PARK" 17 "ESM_SERVICE_PENDING" 15 "ESM_DYNAMIC_PENDING" 7 "ESM_SERVICE" 4 "ESM_DYNAMIC" ;
VAL_ 1448 EPBR_a246_nextState 11 "ESM_PARK_PENDING" 1 "ESM_PARK" 3 "ESM_OPEN" 5 "ESM_SUMMON" 0 "ESM_INIT" 6 "ESM_WINCHMODE" 13 "ESM_SUMMON_PARK" 18 "ESM_DYNAMIC_EXTERNAL_EXIT" 19 "ESM_UNKNOWN" 12 "ESM_WINCHMODE_PENDING" 8 "ESM_DIAGNOSTIC_PARK" 16 "ESM_LATCHED_DYNAMIC_EXTERNAL" 2 "ESM_REAPPLY" 9 "ESM_DIAGNOSTIC_OPEN" 14 "ESM_DYNAMIC_EXTERNAL" 10 "ESM_DYNAMIC_PARK" 17 "ESM_SERVICE_PENDING" 15 "ESM_DYNAMIC_PENDING" 7 "ESM_SERVICE" 4 "ESM_DYNAMIC" ;
VAL_ 1448 EPBR_a242_hvState 6 "HV_UP" 5 "HV_UP_FOR_DC_CHARGE" 0 "HV_DOWN" 2 "HV_GOING_DOWN" 1 "HV_COMING_UP" 4 "HV_UP_FOR_CHARGE" 3 "HV_UP_FOR_DRIVE" ;
VAL_ 1448 EPBR_a178_monitorCaliperState 5 "EPB_SAVED_CALIPERSTATE_SERVICE" 1 "EPB_SAVED_CALIPERSTATE_UNKNOWN" 4 "EPB_SAVED_CALIPERSTATE_OPEN" 2 "EPB_SAVED_CALIPERSTATE_REAPPLY" 0 "EPB_SAVED_CALIPERSTATE_UNSAVED" 3 "EPB_SAVED_CALIPERSTATE_PARK" ;
VAL_ 1448 EPBR_a241_epbSysStatus 0 "EPB_VEHICLE_STATUS_UNKNOWN" 2 "EPB_VEHICLE_STATUS_PARKED" 6 "EPB_VEHICLE_STATUS_FAULT" 3 "EPB_VEHICLE_STATUS_DYNAMIC" 1 "EPB_VEHICLE_STATUS_RELEASED" 4 "EPB_VEHICLE_STATUS_PARKING" 5 "EPB_VEHICLE_STATUS_RELEASING" 8 "EPB_VEHICLE_STATUS_MISMATCH" 7 "EPB_VEHICLE_STATUS_FAULT_SECURE" ;
VAL_ 1448 EPBR_a187_monitorCDPStatus 0 "EPB_EXTERNAL_APPLY_IDLE" 1 "EPB_EXTERNAL_APPLY_VALID" 2 "EPB_EXTERNAL_APPLY_INVALID" ;
VAL_ 1448 EPBR_a188_monitorCDPStatus 0 "EPB_EXTERNAL_APPLY_IDLE" 1 "EPB_EXTERNAL_APPLY_VALID" 2 "EPB_EXTERNAL_APPLY_INVALID" ;
VAL_ 1448 EPBR_a183_monitorCDPStatus 0 "EPB_EXTERNAL_APPLY_IDLE" 1 "EPB_EXTERNAL_APPLY_VALID" 2 "EPB_EXTERNAL_APPLY_INVALID" ;
VAL_ 1448 EPBR_a184_monitorCDPStatus 0 "EPB_EXTERNAL_APPLY_IDLE" 1 "EPB_EXTERNAL_APPLY_VALID" 2 "EPB_EXTERNAL_APPLY_INVALID" ;
VAL_ 1448 EPBR_a189_monitorCDPStatus 0 "EPB_EXTERNAL_APPLY_IDLE" 1 "EPB_EXTERNAL_APPLY_VALID" 2 "EPB_EXTERNAL_APPLY_INVALID" ;
VAL_ 1448 EPBR_a180_monitorCDPStatus 0 "EPB_EXTERNAL_APPLY_IDLE" 1 "EPB_EXTERNAL_APPLY_VALID" 2 "EPB_EXTERNAL_APPLY_INVALID" ;
VAL_ 1448 EPBR_a186_monitorCDPStatus 0 "EPB_EXTERNAL_APPLY_IDLE" 1 "EPB_EXTERNAL_APPLY_VALID" 2 "EPB_EXTERNAL_APPLY_INVALID" ;
VAL_ 1448 EPBR_a201_epbHWBrakeType 1 "EPB_BRAKE_HARDWARE_MANDO" 0 "EPB_BRAKE_HARDWARE_UNKNOWN" 2 "EPB_BRAKE_HARDWARE_BREMBO" ;
VAL_ 1448 EPBR_a185_summonFaultReason 9 "EPB_SUMMONFAULT_VEH_CAN_FAULT" 21 "EPB_SUMMONFAULT_PASSIVE_REQUEST" 26 "EPB_SUMMONFAULT_START_IN_UNAVAILABLE" 5 "EPB_SUMMONFAULT_DI_FAULT" 4 "EPB_SUMMONFAULT_EPBM_MIA" 12 "EPB_SUMMONFAULT_SPEED" 14 "EPB_SUMMONFAULT_PARK_MIA" 19 "EPB_SUMMONFAULT_EPB_FAULT" 25 "EPB_SUMMONFAULT_REMOTE_UNIT_FAULTED" 11 "EPB_SUMMONFAULT_EPBM_REQUEST" 16 "EPB_SUMMONFAULT_PM_REQUEST" 6 "EPB_SUMMONFAULT_DI_APC_FAULT" 13 "EPB_SUMMONFAULT_EXTERNAL" 23 "EPB_SUMMONFAULT_REMOTE_SUMMON_FAULTED" 24 "EPB_SUMMONFAULT_LOCAL_UNIT_FAULTED" 28 "EPB_SUMMONFAULT_REMOTE_DID_NOT_START" 1 "EPB_SUMMONFAULT_DI_MIA" 15 "EPB_SUMMONFAULT_PM_MIA" 27 "EPB_SUMMONFAULT_INVALID_REMOTE_STATE" 0 "EPB_SUMMONFAULT_NONE" 10 "EPB_SUMMONFAULT_EAC_NOT_ALLOWED" 22 "EPB_SUMMONFAULT_EPBREMOTE_MIA" 18 "EPB_SUMMONFAULT_MISMATCH" 3 "EPB_SUMMONFAULT_ESP_MIA" 2 "EPB_SUMMONFAULT_DAS_MIA" 20 "EPB_SUMMONFAULT_DI_STATE_INVALID" 8 "EPB_SUMMONFAULT_ESP_FAULT" 17 "EPB_SUMMONFAULT_OOC" 7 "EPB_SUMMONFAULT_DAS_FAULT" ;
VAL_ 1448 EPBR_a121_caliperState 8 "CSM_WAIT_FOR_ENDSTOP" 9 "CSM_RELEASE_COMPLETE" 12 "CSM_FAULT" 5 "CSM_APPLY_COMPLETE" 7 "CSM_RELEASE_NOLOAD" 14 "CSM_HOLD_CLAMP" 4 "CSM_WAIT_FOR_CLAMP" 6 "CSM_RELEASE_INRUSH" 13 "CSM_STATIONARY_FAULT" 2 "CSM_APPLY_INRUSH" 10 "CSM_CALIBRATE" 1 "CSM_STANDBY" 0 "CSM_INIT" 11 "CSM_HALT" 3 "CSM_APPLY_NOLOAD" ;
VAL_ 1448 EPBR_a177_esmState 11 "ESM_PARK_PENDING" 1 "ESM_PARK" 3 "ESM_OPEN" 5 "ESM_SUMMON" 0 "ESM_INIT" 6 "ESM_WINCHMODE" 13 "ESM_SUMMON_PARK" 18 "ESM_DYNAMIC_EXTERNAL_EXIT" 19 "ESM_UNKNOWN" 12 "ESM_WINCHMODE_PENDING" 8 "ESM_DIAGNOSTIC_PARK" 16 "ESM_LATCHED_DYNAMIC_EXTERNAL" 2 "ESM_REAPPLY" 9 "ESM_DIAGNOSTIC_OPEN" 14 "ESM_DYNAMIC_EXTERNAL" 10 "ESM_DYNAMIC_PARK" 17 "ESM_SERVICE_PENDING" 15 "ESM_DYNAMIC_PENDING" 7 "ESM_SERVICE" 4 "ESM_DYNAMIC" ;
VAL_ 1448 EPBR_a141_fromState 11 "ESM_PARK_PENDING" 1 "ESM_PARK" 3 "ESM_OPEN" 5 "ESM_SUMMON" 0 "ESM_INIT" 6 "ESM_WINCHMODE" 13 "ESM_SUMMON_PARK" 18 "ESM_DYNAMIC_EXTERNAL_EXIT" 19 "ESM_UNKNOWN" 12 "ESM_WINCHMODE_PENDING" 8 "ESM_DIAGNOSTIC_PARK" 16 "ESM_LATCHED_DYNAMIC_EXTERNAL" 2 "ESM_REAPPLY" 9 "ESM_DIAGNOSTIC_OPEN" 14 "ESM_DYNAMIC_EXTERNAL" 10 "ESM_DYNAMIC_PARK" 17 "ESM_SERVICE_PENDING" 15 "ESM_DYNAMIC_PENDING" 7 "ESM_SERVICE" 4 "ESM_DYNAMIC" ;
VAL_ 1448 EPBR_a248_esmState 11 "ESM_PARK_PENDING" 1 "ESM_PARK" 3 "ESM_OPEN" 5 "ESM_SUMMON" 0 "ESM_INIT" 6 "ESM_WINCHMODE" 13 "ESM_SUMMON_PARK" 18 "ESM_DYNAMIC_EXTERNAL_EXIT" 19 "ESM_UNKNOWN" 12 "ESM_WINCHMODE_PENDING" 8 "ESM_DIAGNOSTIC_PARK" 16 "ESM_LATCHED_DYNAMIC_EXTERNAL" 2 "ESM_REAPPLY" 9 "ESM_DIAGNOSTIC_OPEN" 14 "ESM_DYNAMIC_EXTERNAL" 10 "ESM_DYNAMIC_PARK" 17 "ESM_SERVICE_PENDING" 15 "ESM_DYNAMIC_PENDING" 7 "ESM_SERVICE" 4 "ESM_DYNAMIC" ;
VAL_ 1448 EPBR_a186_espCDPStatus 0 "EPB_EXTERNAL_APPLY_IDLE" 1 "EPB_EXTERNAL_APPLY_VALID" 2 "EPB_EXTERNAL_APPLY_INVALID" ;
VAL_ 1448 EPBR_a190_esmState 11 "ESM_PARK_PENDING" 1 "ESM_PARK" 3 "ESM_OPEN" 5 "ESM_SUMMON" 0 "ESM_INIT" 6 "ESM_WINCHMODE" 13 "ESM_SUMMON_PARK" 18 "ESM_DYNAMIC_EXTERNAL_EXIT" 19 "ESM_UNKNOWN" 12 "ESM_WINCHMODE_PENDING" 8 "ESM_DIAGNOSTIC_PARK" 16 "ESM_LATCHED_DYNAMIC_EXTERNAL" 2 "ESM_REAPPLY" 9 "ESM_DIAGNOSTIC_OPEN" 14 "ESM_DYNAMIC_EXTERNAL" 10 "ESM_DYNAMIC_PARK" 17 "ESM_SERVICE_PENDING" 15 "ESM_DYNAMIC_PENDING" 7 "ESM_SERVICE" 4 "ESM_DYNAMIC" ;
VAL_ 1448 EPBR_a188_espCDPStatus 0 "EPB_EXTERNAL_APPLY_IDLE" 1 "EPB_EXTERNAL_APPLY_VALID" 2 "EPB_EXTERNAL_APPLY_INVALID" ;
VAL_ 1448 EPBR_a182_epbSysStatus 0 "EPB_VEHICLE_STATUS_UNKNOWN" 2 "EPB_VEHICLE_STATUS_PARKED" 6 "EPB_VEHICLE_STATUS_FAULT" 3 "EPB_VEHICLE_STATUS_DYNAMIC" 1 "EPB_VEHICLE_STATUS_RELEASED" 4 "EPB_VEHICLE_STATUS_PARKING" 5 "EPB_VEHICLE_STATUS_RELEASING" 8 "EPB_VEHICLE_STATUS_MISMATCH" 7 "EPB_VEHICLE_STATUS_FAULT_SECURE" ;
VAL_ 1448 EPBR_a174_esmState 11 "ESM_PARK_PENDING" 1 "ESM_PARK" 3 "ESM_OPEN" 5 "ESM_SUMMON" 0 "ESM_INIT" 6 "ESM_WINCHMODE" 13 "ESM_SUMMON_PARK" 18 "ESM_DYNAMIC_EXTERNAL_EXIT" 19 "ESM_UNKNOWN" 12 "ESM_WINCHMODE_PENDING" 8 "ESM_DIAGNOSTIC_PARK" 16 "ESM_LATCHED_DYNAMIC_EXTERNAL" 2 "ESM_REAPPLY" 9 "ESM_DIAGNOSTIC_OPEN" 14 "ESM_DYNAMIC_EXTERNAL" 10 "ESM_DYNAMIC_PARK" 17 "ESM_SERVICE_PENDING" 15 "ESM_DYNAMIC_PENDING" 7 "ESM_SERVICE" 4 "ESM_DYNAMIC" ;
VAL_ 1448 EPBR_a246_previousState 11 "ESM_PARK_PENDING" 1 "ESM_PARK" 3 "ESM_OPEN" 5 "ESM_SUMMON" 0 "ESM_INIT" 6 "ESM_WINCHMODE" 13 "ESM_SUMMON_PARK" 18 "ESM_DYNAMIC_EXTERNAL_EXIT" 19 "ESM_UNKNOWN" 12 "ESM_WINCHMODE_PENDING" 8 "ESM_DIAGNOSTIC_PARK" 16 "ESM_LATCHED_DYNAMIC_EXTERNAL" 2 "ESM_REAPPLY" 9 "ESM_DIAGNOSTIC_OPEN" 14 "ESM_DYNAMIC_EXTERNAL" 10 "ESM_DYNAMIC_PARK" 17 "ESM_SERVICE_PENDING" 15 "ESM_DYNAMIC_PENDING" 7 "ESM_SERVICE" 4 "ESM_DYNAMIC" ;
VAL_ 1448 EPBR_a300_harnessId 11 "ESM_PARK_PENDING" 1 "ESM_PARK" 3 "ESM_OPEN" 5 "ESM_SUMMON" 0 "ESM_INIT" 6 "ESM_WINCHMODE" 13 "ESM_SUMMON_PARK" 18 "ESM_DYNAMIC_EXTERNAL_EXIT" 19 "ESM_UNKNOWN" 12 "ESM_WINCHMODE_PENDING" 8 "ESM_DIAGNOSTIC_PARK" 16 "ESM_LATCHED_DYNAMIC_EXTERNAL" 2 "ESM_REAPPLY" 9 "ESM_DIAGNOSTIC_OPEN" 14 "ESM_DYNAMIC_EXTERNAL" 10 "ESM_DYNAMIC_PARK" 17 "ESM_SERVICE_PENDING" 15 "ESM_DYNAMIC_PENDING" 7 "ESM_SERVICE" 4 "ESM_DYNAMIC" ;
VAL_ 1448 EPBR_a187_espCDPStatus 0 "EPB_EXTERNAL_APPLY_IDLE" 1 "EPB_EXTERNAL_APPLY_VALID" 2 "EPB_EXTERNAL_APPLY_INVALID" ;
VAL_ 1448 EPBR_a184_espCDPStatus 0 "EPB_EXTERNAL_APPLY_IDLE" 1 "EPB_EXTERNAL_APPLY_VALID" 2 "EPB_EXTERNAL_APPLY_INVALID" ;
VAL_ 1448 EPBR_a189_espCDPStatus 0 "EPB_EXTERNAL_APPLY_IDLE" 1 "EPB_EXTERNAL_APPLY_VALID" 2 "EPB_EXTERNAL_APPLY_INVALID" ;
VAL_ 1448 EPBR_a247_esmState 11 "ESM_PARK_PENDING" 1 "ESM_PARK" 3 "ESM_OPEN" 5 "ESM_SUMMON" 0 "ESM_INIT" 6 "ESM_WINCHMODE" 13 "ESM_SUMMON_PARK" 18 "ESM_DYNAMIC_EXTERNAL_EXIT" 19 "ESM_UNKNOWN" 12 "ESM_WINCHMODE_PENDING" 8 "ESM_DIAGNOSTIC_PARK" 16 "ESM_LATCHED_DYNAMIC_EXTERNAL" 2 "ESM_REAPPLY" 9 "ESM_DIAGNOSTIC_OPEN" 14 "ESM_DYNAMIC_EXTERNAL" 10 "ESM_DYNAMIC_PARK" 17 "ESM_SERVICE_PENDING" 15 "ESM_DYNAMIC_PENDING" 7 "ESM_SERVICE" 4 "ESM_DYNAMIC" ;
VAL_ 1448 EPBR_a191_esmState 11 "ESM_PARK_PENDING" 1 "ESM_PARK" 3 "ESM_OPEN" 5 "ESM_SUMMON" 0 "ESM_INIT" 6 "ESM_WINCHMODE" 13 "ESM_SUMMON_PARK" 18 "ESM_DYNAMIC_EXTERNAL_EXIT" 19 "ESM_UNKNOWN" 12 "ESM_WINCHMODE_PENDING" 8 "ESM_DIAGNOSTIC_PARK" 16 "ESM_LATCHED_DYNAMIC_EXTERNAL" 2 "ESM_REAPPLY" 9 "ESM_DIAGNOSTIC_OPEN" 14 "ESM_DYNAMIC_EXTERNAL" 10 "ESM_DYNAMIC_PARK" 17 "ESM_SERVICE_PENDING" 15 "ESM_DYNAMIC_PENDING" 7 "ESM_SERVICE" 4 "ESM_DYNAMIC" ;
VAL_ 1448 EPBR_a175_esmState 11 "ESM_PARK_PENDING" 1 "ESM_PARK" 3 "ESM_OPEN" 5 "ESM_SUMMON" 0 "ESM_INIT" 6 "ESM_WINCHMODE" 13 "ESM_SUMMON_PARK" 18 "ESM_DYNAMIC_EXTERNAL_EXIT" 19 "ESM_UNKNOWN" 12 "ESM_WINCHMODE_PENDING" 8 "ESM_DIAGNOSTIC_PARK" 16 "ESM_LATCHED_DYNAMIC_EXTERNAL" 2 "ESM_REAPPLY" 9 "ESM_DIAGNOSTIC_OPEN" 14 "ESM_DYNAMIC_EXTERNAL" 10 "ESM_DYNAMIC_PARK" 17 "ESM_SERVICE_PENDING" 15 "ESM_DYNAMIC_PENDING" 7 "ESM_SERVICE" 4 "ESM_DYNAMIC" ;
VAL_ 1448 EPBR_a183_espCDPStatus 0 "EPB_EXTERNAL_APPLY_IDLE" 1 "EPB_EXTERNAL_APPLY_VALID" 2 "EPB_EXTERNAL_APPLY_INVALID" ;
VAL_ 1448 EPBR_a180_espCDPStatus 0 "EPB_EXTERNAL_APPLY_IDLE" 1 "EPB_EXTERNAL_APPLY_VALID" 2 "EPB_EXTERNAL_APPLY_INVALID" ;
VAL_ 1448 EPBR_a178_localCaliperState 5 "EPB_SAVED_CALIPERSTATE_SERVICE" 1 "EPB_SAVED_CALIPERSTATE_UNKNOWN" 4 "EPB_SAVED_CALIPERSTATE_OPEN" 2 "EPB_SAVED_CALIPERSTATE_REAPPLY" 0 "EPB_SAVED_CALIPERSTATE_UNSAVED" 3 "EPB_SAVED_CALIPERSTATE_PARK" ;
VAL_ 1448 EPBR_a176_esmState 11 "ESM_PARK_PENDING" 1 "ESM_PARK" 3 "ESM_OPEN" 5 "ESM_SUMMON" 0 "ESM_INIT" 6 "ESM_WINCHMODE" 13 "ESM_SUMMON_PARK" 18 "ESM_DYNAMIC_EXTERNAL_EXIT" 19 "ESM_UNKNOWN" 12 "ESM_WINCHMODE_PENDING" 8 "ESM_DIAGNOSTIC_PARK" 16 "ESM_LATCHED_DYNAMIC_EXTERNAL" 2 "ESM_REAPPLY" 9 "ESM_DIAGNOSTIC_OPEN" 14 "ESM_DYNAMIC_EXTERNAL" 10 "ESM_DYNAMIC_PARK" 17 "ESM_SERVICE_PENDING" 15 "ESM_DYNAMIC_PENDING" 7 "ESM_SERVICE" 4 "ESM_DYNAMIC" ;
VAL_ 1448 EPBR_a173_esmState 11 "ESM_PARK_PENDING" 1 "ESM_PARK" 3 "ESM_OPEN" 5 "ESM_SUMMON" 0 "ESM_INIT" 6 "ESM_WINCHMODE" 13 "ESM_SUMMON_PARK" 18 "ESM_DYNAMIC_EXTERNAL_EXIT" 19 "ESM_UNKNOWN" 12 "ESM_WINCHMODE_PENDING" 8 "ESM_DIAGNOSTIC_PARK" 16 "ESM_LATCHED_DYNAMIC_EXTERNAL" 2 "ESM_REAPPLY" 9 "ESM_DIAGNOSTIC_OPEN" 14 "ESM_DYNAMIC_EXTERNAL" 10 "ESM_DYNAMIC_PARK" 17 "ESM_SERVICE_PENDING" 15 "ESM_DYNAMIC_PENDING" 7 "ESM_SERVICE" 4 "ESM_DYNAMIC" ;
VAL_ 1448 EPBR_a249_previousState 11 "ESM_PARK_PENDING" 1 "ESM_PARK" 3 "ESM_OPEN" 5 "ESM_SUMMON" 0 "ESM_INIT" 6 "ESM_WINCHMODE" 13 "ESM_SUMMON_PARK" 18 "ESM_DYNAMIC_EXTERNAL_EXIT" 19 "ESM_UNKNOWN" 12 "ESM_WINCHMODE_PENDING" 8 "ESM_DIAGNOSTIC_PARK" 16 "ESM_LATCHED_DYNAMIC_EXTERNAL" 2 "ESM_REAPPLY" 9 "ESM_DIAGNOSTIC_OPEN" 14 "ESM_DYNAMIC_EXTERNAL" 10 "ESM_DYNAMIC_PARK" 17 "ESM_SERVICE_PENDING" 15 "ESM_DYNAMIC_PENDING" 7 "ESM_SERVICE" 4 "ESM_DYNAMIC" ;
VAL_ 1448 EPBR_a179_esmState 11 "ESM_PARK_PENDING" 1 "ESM_PARK" 3 "ESM_OPEN" 5 "ESM_SUMMON" 0 "ESM_INIT" 6 "ESM_WINCHMODE" 13 "ESM_SUMMON_PARK" 18 "ESM_DYNAMIC_EXTERNAL_EXIT" 19 "ESM_UNKNOWN" 12 "ESM_WINCHMODE_PENDING" 8 "ESM_DIAGNOSTIC_PARK" 16 "ESM_LATCHED_DYNAMIC_EXTERNAL" 2 "ESM_REAPPLY" 9 "ESM_DIAGNOSTIC_OPEN" 14 "ESM_DYNAMIC_EXTERNAL" 10 "ESM_DYNAMIC_PARK" 17 "ESM_SERVICE_PENDING" 15 "ESM_DYNAMIC_PENDING" 7 "ESM_SERVICE" 4 "ESM_DYNAMIC" ;
VAL_ 1448 EPBR_alertType 0 "ALERT_CLEARED" 1 "ALERT_SET" ;
VAL_ 1448 EPBR_alertID 249 "EPBR_a249_idleFaultRelease" 185 "EPBR_a185_summonAborted" 137 "EPBR_a137_PvUv" 107 "EPBR_a107_BMS_MIA" 125 "EPBR_a125_IdleVMismatch" 217 "EPBR_a217_SPI_MIA_debugData2" 186 "EPBR_a186_externalParkAbort" 177 "EPBR_a177_csmApplyRetry" 114 "EPBR_a114_ESP_MIA" 46 "EPBR_a046_Task1000msError" 179 "EPBR_a179_epbProblem" 117 "EPBR_a117_VCLEFT_MIA" 103 "EPBR_a103_CP_MIA" 45 "EPBR_a045_Task100msError" 2 "EPBR_a002_PowerLossReset" 61 "EPBR_a061_XCPConnected" 112 "EPBR_a112_EPBL_MIA" 42 "EPBR_a042_HighStackUsage" 102 "EPBR_a102_PTC_MIA" 123 "EPBR_a123_Uc" 30 "EPBR_a030_ECULogUploadRequest" 127 "EPBR_a127_MotorNVoltHigh" 60 "EPBR_a060_engineeringBuild" 200 "EPBR_a200_PmUnparkNotAllowed" 1 "EPBR_a001_WatchdogReset" 173 "EPBR_a173_hiCurrentMissing" 248 "EPBR_a248_csmDynamicApplyFailed" 135 "EPBR_a135_NvUv" 195 "EPBR_a195_parkForDriverIsLeaving" 64 "EPBR_a064_busSleepReqTimeout" 138 "EPBR_a138_NVMWriteTime" 201 "EPBR_a201_hwBrakeTypeMismatch" 59 "EPBR_a059_inputResistanceHigh" 0 "EPBR_ALERT_DO_NOT_USE_ZERO" 242 "EPBR_a242_hvOutputLocked" 170 "EPBR_a170_12vOv" 99 "EPBR_a099_PARK_MIA" 246 "EPBR_a246_idleFaultApply" 44 "EPBR_a044_Task10msError" 10 "EPBR_a010_ExtSupplyVoltError" 300 "EPBR_a300_leftRightConfusion" 141 "EPBR_a141_invalidState" 97 "EPBR_a097_CMP_MIA" 106 "EPBR_a106_PCS_MIA" 13 "EPBR_a013_AlertManagerFault" 62 "EPBR_a062_XCPWasConnected" 43 "EPBR_a043_Task1msError" 181 "EPBR_a181_TooSteepGradeToPark" 189 "EPBR_a189_epbDynamicParkCanceled" 126 "EPBR_a126_MotorNVoltLow" 174 "EPBR_a174_csmReleaseFailed" 108 "EPBR_a108_DIS_MIA" 180 "EPBR_a180_dynamicActive" 12 "EPBR_a012_CPUReset" 105 "EPBR_a105_TAS_MIA" 250 "EPBR_a250_WinchModeCanceled" 41 "EPBR_a041_HighCPULoad" 100 "EPBR_a100_CANbus_MIA" 188 "EPBR_a188_epbDynamic" 136 "EPBR_a136_PvOv" 110 "EPBR_a110_GTW_MIA" 109 "EPBR_a109_RCM_MIA" 111 "EPBR_a111_EPBR_MIA" 243 "EPBR_a243_bdwUnavailable" 244 "EPBR_a244_WinchModeActive" 182 "EPBR_a182_OneEPBAppliedUnsecEnv" 118 "EPBR_a118_VCFRONT_MIA" 21 "EPBR_a021_TaskSchedulerError" 183 "EPBR_a183_cdpNotAvailable" 171 "EPBR_a171_12vUv" 190 "EPBR_a190_csmApplyDegraded" 116 "EPBR_a116_VCRIGHT_MIA" 245 "EPBR_a245_serviceModeActive" 104 "EPBR_a104_DAS_MIA" 178 "EPBR_a178_caliperStateUnknown" 251 "EPBR_a251_currentVarianceHigh" 31 "EPBR_a031_UDSActive" 187 "EPBR_a187_cdpDynamic" 172 "EPBR_a172_SPI_MIA" 115 "EPBR_a115_VCSEC_MIA" 241 "EPBR_a241_diOutputLocked" 128 "EPBR_a128_MotorPVoltHigh" 175 "EPBR_a175_csmReleaseRetry" 120 "EPBR_a120_DI_DRIVE_MIA" 101 "EPBR_a101_PM_MIA" 22 "EPBR_a022_TaskInitError" 124 "EPBR_a124_calOutOfBounds" 134 "EPBR_a134_NvOv" 98 "EPBR_a098_DI_THERMAL_MIA" 15 "EPBR_a015_NVMMAlert" 121 "EPBR_a121_nDriveFault" 216 "EPBR_a216_SPI_MIA_debugData1" 176 "EPBR_a176_csmApplyFailed" 184 "EPBR_a184_dynamicParkAbort" 3 "EPBR_a003_SWAssertion" 119 "EPBR_a119_SCCM_MIA" 191 "EPBR_a191_csmReleaseDegraded" 63 "EPBR_a063_SwitchFault" 247 "EPBR_a247_csmDynamicApplyRetry" 122 "EPBR_a122_Oc" 113 "EPBR_a113_UI_MIA" ;
VAL_ 574 PARK_oocOffCourse 1023 "NONE" ;
VAL_ 574 PARK_oocHeight 1 "LOW_OBJ" 3 "HEIGHT_UNKNOWN" 0 "NO_OBJ" 2 "HIGH_OBJ" ;
VAL_ 574 PARK_oocUntrackedTime 63 "SNA" ;
VAL_ 574 PARK_oocCollisionSide 7 "COLLISION_SNA" 4 "REAR_COLLISION" 0 "NO_COLLISION" 3 "FRONT_COLLISION" 2 "LEFT_SIDE_COLLISION" 5 "COLLISION_UNKNOWN" 1 "RIGHT_SIDE_COLLISION" ;
VAL_ 574 PARK_oocVehicleY 255 "UNKNOWN" ;
VAL_ 574 PARK_oocVehicleX 255 "UNKNOWN" ;
VAL_ 574 PARK_oocConfidence 127 "SNA" 0 "NO_CONFIDENCE" ;
VAL_ 574 PARK_oocDistance 511 "SNA" 500 "NO_OBJ_COLLISION" 501 "NOT_INITIALIZED" ;
VAL_ 921 VCSEC_crashState 2 "CRASH_STATE_SEVERE" 0 "CRASH_STATE_IDLE" 1 "CRASH_STATE_MINOR" ;
VAL_ 921 VCSEC_crashDetectedType 1 "CRASH_DETECTED_TYPE_MINOR" 0 "CRASH_DETECTED_TYPE_NONE" 2 "CRASH_DETECTED_TYPE_SEVERE" ;
VAL_ 289 RCM_crashAlgoWakeup 0 "RCM_CRASH_ALGO_WAKEUP_EVENT_INACTIVE" 3 "RCM_CRASH_ALGO_WAKEUP_EVENT_SNA" 1 "RCM_CRASH_ALGO_WAKEUP_EVENT_ACTIVE" ;
VAL_ 289 RCM_nearDeployRollover 0 "RCM_NEAR_DEPLOY_EVENT_INACTIVE" 1 "RCM_NEAR_DEPLOY_EVENT_ACTIVE" 3 "RCM_NEAR_DEPLOY_EVENT_SNA" ;
VAL_ 289 RCM_nearDeployFront 0 "RCM_NEAR_DEPLOY_EVENT_INACTIVE" 1 "RCM_NEAR_DEPLOY_EVENT_ACTIVE" 3 "RCM_NEAR_DEPLOY_EVENT_SNA" ;
VAL_ 289 RCM_nearDeployLeft 0 "RCM_NEAR_DEPLOY_EVENT_INACTIVE" 1 "RCM_NEAR_DEPLOY_EVENT_ACTIVE" 3 "RCM_NEAR_DEPLOY_EVENT_SNA" ;
VAL_ 289 RCM_nearDeployRight 0 "RCM_NEAR_DEPLOY_EVENT_INACTIVE" 1 "RCM_NEAR_DEPLOY_EVENT_ACTIVE" 3 "RCM_NEAR_DEPLOY_EVENT_SNA" ;
VAL_ 289 RCM_nearDeployRear 0 "RCM_NEAR_DEPLOY_EVENT_INACTIVE" 1 "RCM_NEAR_DEPLOY_EVENT_ACTIVE" 3 "RCM_NEAR_DEPLOY_EVENT_SNA" ;
VAL_ 987 VCSEC_endpointDataIndex 1 "VCSEC_ENDPOINTDATA_AMBIENT_RSSI_0" 2 "VCSEC_ENDPOINTDATA_AMBIENT_RSSI_1" 0 "VCSEC_ENDPOINTDATA_TEMPERATURES" ;
VAL_ 995 VCRIGHT_rearFogLightStatus 3 "LIGHT_SNA" 1 "LIGHT_ON" 0 "LIGHT_OFF" 2 "LIGHT_FAULT" ;
VAL_ 995 VCRIGHT_reverseLightStatus 3 "LIGHT_SNA" 1 "LIGHT_ON" 0 "LIGHT_OFF" 2 "LIGHT_FAULT" ;
VAL_ 995 VCRIGHT_turnSignalStatus 3 "LIGHT_SNA" 1 "LIGHT_ON" 0 "LIGHT_OFF" 2 "LIGHT_FAULT" ;
VAL_ 995 VCRIGHT_tailLightStatus 3 "LIGHT_SNA" 1 "LIGHT_ON" 0 "LIGHT_OFF" 2 "LIGHT_FAULT" ;
VAL_ 995 VCRIGHT_brakeLightStatus 3 "LIGHT_SNA" 1 "LIGHT_ON" 0 "LIGHT_OFF" 2 "LIGHT_FAULT" ;
VAL_ 1834 BMS_serialNumberMultiplexer 0 "BMS_SERIAL_MUX0" 1 "BMS_SERIAL_MUX1" ;
VAL_ 1290 HVP_a050_negCtrState 2 "CONTACTOR_STATE_PRECHARGE" 3 "CONTACTOR_STATE_BLOCKED" 6 "CONTACTOR_STATE_ECONOMIZED" 4 "CONTACTOR_STATE_PULLED_IN" 0 "CONTACTOR_STATE_SNA" 1 "CONTACTOR_STATE_OPEN" 5 "CONTACTOR_STATE_OPENING" 7 "CONTACTOR_STATE_WELDED" ;
VAL_ 1290 HVP_a049_negCtrState 2 "CONTACTOR_STATE_PRECHARGE" 3 "CONTACTOR_STATE_BLOCKED" 6 "CONTACTOR_STATE_ECONOMIZED" 4 "CONTACTOR_STATE_PULLED_IN" 0 "CONTACTOR_STATE_SNA" 1 "CONTACTOR_STATE_OPEN" 5 "CONTACTOR_STATE_OPENING" 7 "CONTACTOR_STATE_WELDED" ;
VAL_ 1290 HVP_a020_shuntTemperature -32768 "SNA" ;
VAL_ 1290 HVP_a051_energyReserveV 65535 "SNA" ;
VAL_ 1290 HVP_a050_posCtrState 2 "CONTACTOR_STATE_PRECHARGE" 3 "CONTACTOR_STATE_BLOCKED" 6 "CONTACTOR_STATE_ECONOMIZED" 4 "CONTACTOR_STATE_PULLED_IN" 0 "CONTACTOR_STATE_SNA" 1 "CONTACTOR_STATE_OPEN" 5 "CONTACTOR_STATE_OPENING" 7 "CONTACTOR_STATE_WELDED" ;
VAL_ 1290 HVP_a049_posCtrState 2 "CONTACTOR_STATE_PRECHARGE" 3 "CONTACTOR_STATE_BLOCKED" 6 "CONTACTOR_STATE_ECONOMIZED" 4 "CONTACTOR_STATE_PULLED_IN" 0 "CONTACTOR_STATE_SNA" 1 "CONTACTOR_STATE_OPEN" 5 "CONTACTOR_STATE_OPENING" 7 "CONTACTOR_STATE_WELDED" ;
VAL_ 1290 HVP_a020_shuntCurrentAux -32768 "SNA" ;
VAL_ 1290 HVP_a051_shuntCurrent -32768 "SNA" ;
VAL_ 1290 HVP_a020_energyReserveV 65535 "SNA" ;
VAL_ 1290 HVP_a037_pyroFiringHandle 10 "PYRO_HANDLE_ENS_CRASH" 5 "PYRO_HANDLE_OVER_VOLTAGE" 2 "PYRO_HANDLE_OVER_DISCHARGE_CURRENT" 12 "PYRO_HANDLE_PACK_NEGATIVE_CTR_ARC" 4 "PYRO_HANDLE_OVER_CURRENT" 7 "PYRO_HANDLE_TEMPERATURE" 1 "PYRO_HANDLE_HVP" 9 "PYRO_HANDLE_SHUNT_MIA" 3 "PYRO_HANDLE_OVER_CHARGE_CURRENT" 6 "PYRO_HANDLE_UNDER_VOLTAGE" 11 "PYRO_HANDLE_PACK_POSITIVE_CTR_ARC" 8 "PYRO_HANDLE_OPEN_IMMEDIATELY" ;
VAL_ 1290 HVP_a021_pyroStatus 0 "STATUS_UNKNOWN" 1 "STATUS_OK" 3 "STATUS_ACTIVATED" 2 "STATUS_FAULT" ;
VAL_ 1290 HVP_a036_pyroFiringHandle 10 "PYRO_HANDLE_ENS_CRASH" 5 "PYRO_HANDLE_OVER_VOLTAGE" 2 "PYRO_HANDLE_OVER_DISCHARGE_CURRENT" 12 "PYRO_HANDLE_PACK_NEGATIVE_CTR_ARC" 4 "PYRO_HANDLE_OVER_CURRENT" 7 "PYRO_HANDLE_TEMPERATURE" 1 "PYRO_HANDLE_HVP" 9 "PYRO_HANDLE_SHUNT_MIA" 3 "PYRO_HANDLE_OVER_CHARGE_CURRENT" 6 "PYRO_HANDLE_UNDER_VOLTAGE" 11 "PYRO_HANDLE_PACK_POSITIVE_CTR_ARC" 8 "PYRO_HANDLE_OPEN_IMMEDIATELY" ;
VAL_ 1290 HVP_a051_shuntTemperature -32768 "SNA" ;
VAL_ 1290 HVP_a026_hvilStatus 6 "UNKNOWN_LOCATION_OPEN_FAULT" 0 "UNKNOWN" 5 "PENTHOUSE_LID_OPEN_FAULT" 3 "INTERNAL_OPEN_FAULT" 1 "STATUS_OK" 8 "NO_12V_SUPPLY" 7 "VEHICLE_NODE_FAULT" 4 "VEHICLE_OPEN_FAULT" 2 "CURRENT_SOURCE_FAULT" ;
VAL_ 1290 HVP_alertSet 0 "ALERT_CLEARED" 1 "ALERT_SET" ;
VAL_ 1290 HVP_alertID 12 "HVP_a012_SecondaryBmbMiaFault" 15 "HVP_a015_CpMiaFault" 8 "HVP_a008_OverTemperatureFault" 42 "HVP_a042_fcCtrCloseBlocked" 50 "HVP_a050_fcCtrCloseFailed" 5 "HVP_a005_OverDchgCurrentFault" 2 "HVP_a002_UnusedAlert2" 43 "HVP_a043_packContactorForceOpen" 7 "HVP_a007_OverCurrentFault" 32 "HVP_a032_ShuntHwAndBmsMiaFault" 45 "HVP_a045_dcLinkOverVoltage" 47 "HVP_a047_passivePyroDeploy" 41 "HVP_a041_packCtrCloseBlocked" 29 "HVP_a029_EnsMiaFault" 46 "HVP_a046_shuntOverTemperature" 19 "HVP_a019_CpFault" 20 "HVP_a020_ShuntHwMiaFault" 33 "HVP_a033_fcContHwFault" 27 "HVP_a027_BmsHvsMiaFault" 4 "HVP_a004_CrashEvent" 40 "HVP_a040_FcContactorFellOpen" 37 "HVP_a037_pyroFuseFailedToBlow" 18 "HVP_a018_PcsFault" 31 "HVP_a031_packNegCtrArcFault" 51 "HVP_a051_shuntThermistorMia" 16 "HVP_a016_PcsMiaFault" 17 "HVP_a017_BmsFault" 21 "HVP_a021_PyroMiaFault" 3 "HVP_a003_SwAssertion" 26 "HVP_a026_HvilFault" 24 "HVP_a024_Supply12vFault" 22 "HVP_a022_hvsMiaFault" 48 "HVP_a048_logUploadRequest" 0 "HVP_ALERT_DO_NOT_USE_ZERO" 9 "HVP_a009_OverVoltageFault" 25 "HVP_a025_VerSupplyFault" 38 "HVP_a038_CpilFault" 35 "HVP_a035_packContHwFault" 28 "HVP_a028_PackVoltMismatchFault" 36 "HVP_a036_pyroFuseBlown" 49 "HVP_a049_packCtrCloseFailed" 10 "HVP_a010_UnderVoltageFault" 1 "HVP_a001_WatchdogReset" 13 "HVP_a013_BmbMismatchFault" 6 "HVP_a006_OverChargeCurrentFault" 34 "HVP_a034_robinOverVoltageFault" 30 "HVP_a030_PackPosCtrArcFault" 14 "HVP_a014_BmsHviMiaFault" 39 "HVP_a039_PackContactorFellOpen" 44 "HVP_a044_fcContactorForceOpen" 11 "HVP_a011_PrimaryBmbMiaFault" ;
VAL_ 865 VCFRONT_CPULoad1000msTask 255 "SNA" ;
VAL_ 865 VCFRONT_CPULoad100msTask 255 "SNA" ;
VAL_ 865 VCFRONT_CPULoad10msTask 255 "SNA" ;
VAL_ 865 VCFRONT_CPULoad1msTask 255 "SNA" ;
VAL_ 865 VCFRONT_CPULoadTotal 255 "SNA" ;
